VERSION "HNNBNNNYNNNNNNNNNNNNNNNNNNNNNNNNNNNNNNNNNN/4/%%%/4/'%**4NNN///"

NS_ :

BS_:

BU_: BAP_Tester FASFrontradar ICAS1_X_Gateway MFK MFK120 MIK MRR2023 NR_1 NR_2

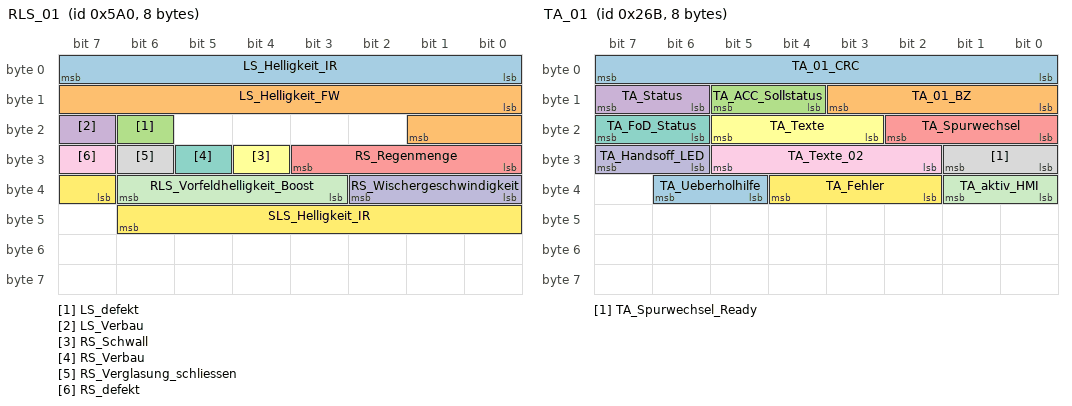
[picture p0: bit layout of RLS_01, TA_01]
BO_ 1440 RLS_01: 8 ICAS1_X_Gateway
 SG_ LS_Helligkeit_IR : 0|8@1+ (400,0) [0|101200] "Unit_Lux"  Vector__XXX
 SG_ LS_Helligkeit_FW : 8|10@1+ (6,0) [0|6126] "Unit_Lux"  Vector__XXX
 SG_ LS_defekt : 22|1@1+ (1.0,0.0) [0.0|1] ""  Vector__XXX
 SG_ LS_Verbau : 23|1@1+ (1.0,0.0) [0.0|1] ""  Vector__XXX
 SG_ RS_Regenmenge : 24|4@1+ (1.0,0.0) [0.0|15] ""  MFK120
 SG_ RS_Schwall : 28|1@1+ (1.0,0.0) [0.0|1] ""  Vector__XXX
 SG_ RS_Verbau : 29|1@1+ (1.0,0.0) [0.0|1] ""  Vector__XXX
 SG_ RS_Verglasung_schliessen : 30|1@1+ (1.0,0.0) [0.0|1] ""  Vector__XXX
 SG_ RS_defekt : 31|1@1+ (1.0,0.0) [0.0|1] ""  Vector__XXX
 SG_ RS_Wischergeschwindigkeit : 32|3@1+ (1.0,0.0) [0.0|7] ""  MFK,MFK120
 SG_ RLS_Vorfeldhelligkeit_Boost : 35|4@1+ (1.0,0.0) [0.0|15] ""  Vector__XXX
 SG_ SLS_Helligkeit_IR : 39|8@1+ (250,0) [0|7000] "Unit_Lux"  Vector__XXX

BO_ 2463978697 SAL_01: 8 ICAS1_X_Gateway
 SG_ SAL_01_CRC : 0|8@1+ (1,0) [0|255] ""  Vector__XXX
 SG_ SAL_01_BZ : 8|4@1+ (1,0) [0|15] ""  Vector__XXX
 SG_ SAL_LDS_Abblendlicht_Anf : 12|1@1+ (1.0,0.0) [0.0|1] ""  Vector__XXX
 SG_ SAL_LDS_Assistenzfahrlicht_Anf : 13|1@1+ (1.0,0.0) [0.0|1] ""  Vector__XXX
 SG_ SAL_LDS_Nullstellung_Anf : 14|1@1+ (1.0,0.0) [0.0|1] ""  Vector__XXX
 SG_ SAL_LDS_Standlicht_Anf : 15|1@1+ (1.0,0.0) [0.0|1] ""  Vector__XXX
 SG_ SBBR_SL_AnimDimm_Freigabe : 16|2@1+ (1.0,0.0) [0.0|3] ""  Vector__XXX
 SG_ BCM2_Bremsl_durch_ECD : 18|1@1+ (1.0,0.0) [0.0|1] ""  Vector__XXX
 SG_ SAL_LH_Anf : 19|1@1+ (1.0,0.0) [0.0|1] ""  Vector__XXX
 SG_ SAL_BRL_Anf : 20|1@1+ (1.0,0.0) [0.0|1] ""  Vector__XXX
 SG_ SAL_WBT_Bel : 21|1@1+ (1.0,0.0) [0.0|1] ""  Vector__XXX
 SG_ SAL_CH_Anf : 22|1@1+ (1.0,0.0) [0.0|1] ""  Vector__XXX
 SG_ SAL_PL_R_Anf : 23|1@1+ (1.0,0.0) [0.0|1] ""  Vector__XXX
 SG_ SAL_PL_L_Anf : 24|1@1+ (1.0,0.0) [0.0|1] ""  Vector__XXX
 SG_ SAL_BLK_R_Anf : 25|1@1+ (1.0,0.0) [0.0|1] ""  Vector__XXX
 SG_ SAL_BLK_L_Anf : 26|1@1+ (1.0,0.0) [0.0|1] ""  Vector__XXX
 SG_ SAL_RFL_Anf : 27|1@1+ (1.0,0.0) [0.0|1] ""  Vector__XXX
 SG_ SAL_NSL_Anf : 28|1@1+ (1.0,0.0) [0.0|1] ""  Vector__XXX
 SG_ SAL_SL_Anf : 29|1@1+ (1.0,0.0) [0.0|1] ""  Vector__XXX
 SG_ SAL_HGB_Anf : 30|1@1+ (1.0,0.0) [0.0|1] ""  Vector__XXX
 SG_ LWR_SollDC : 32|8@1+ (0.5,0) [0.0|100.0] "Unit_PerCent"  Vector__XXX
 SG_ SAL_Bremszyklus : 43|1@1+ (1.0,0.0) [0.0|1] ""  Vector__XXX
 SG_ SAL_Blinkerzyklus_R : 44|1@1+ (1.0,0.0) [0.0|1] ""  Vector__XXX
 SG_ SAL_Blinkerzyklus_L : 45|1@1+ (1.0,0.0) [0.0|1] ""  Vector__XXX
 SG_ LWR_Lampe : 46|1@1+ (1.0,0.0) [0.0|1] ""  Vector__XXX
 SG_ AFS_Lampe : 47|1@1+ (1.0,0.0) [0.0|1] ""  Vector__XXX
 SG_ LWR_Reisemodus_Texte : 48|2@1+ (1.0,0.0) [0.0|3] ""  Vector__XXX
 SG_ SAL_KZL_Anf : 50|1@1+ (1.0,0.0) [0.0|1] ""  Vector__XXX
 SG_ SAL_KL_50 : 51|1@1+ (1.0,0.0) [0.0|1] ""  Vector__XXX
 SG_ SAL_KL_75a_vFzg : 52|1@1+ (1.0,0.0) [0.0|1] ""  Vector__XXX
 SG_ SAL_KL_75a : 53|1@1+ (1.0,0.0) [0.0|1] ""  Vector__XXX
 SG_ SAL_KL_75_vFzg : 54|1@1+ (1.0,0.0) [0.0|1] ""  Vector__XXX
 SG_ SAL_Kl_75 : 55|1@1+ (1.0,0.0) [0.0|1] ""  Vector__XXX
 SG_ SAL_KL_50_5s : 56|1@1+ (1.0,0.0) [0.0|1] ""  Vector__XXX
 SG_ SAL_Kl_15_vFzg_S : 57|1@1+ (1.0,0.0) [0.0|1] ""  Vector__XXX
 SG_ SAL_Kl_15_vFzg : 58|1@1+ (1.0,0.0) [0.0|1] ""  Vector__XXX
 SG_ SAL_Kl_15 : 59|1@1+ (1.0,0.0) [0.0|1] ""  Vector__XXX
 SG_ DLI_Ambex_RefStatus : 60|3@1+ (1.0,0.0) [0.0|7] ""  Vector__XXX
 SG_ SAL_Aussenbeleuchtung_defekt : 63|1@1+ (1.0,0.0) [0.0|1] ""  MFK

BO_ 980 SMLS_01: 8 ICAS1_X_Gateway
 SG_ SMLS_01_CRC : 0|8@1+ (1,0) [0|255] ""  Vector__XXX
 SG_ SMLS_01_BZ : 8|4@1+ (1,0) [0|15] ""  Vector__XXX
 SG_ BH_Blinker_li : 12|1@1+ (1.0,0.0) [0.0|1] ""  FASFrontradar,MFK,MFK120,MRR2023
 SG_ BH_Blinker_re : 13|1@1+ (1.0,0.0) [0.0|1] ""  FASFrontradar,MFK,MFK120,MRR2023
 SG_ BH_Lichthupe : 14|1@1+ (1.0,0.0) [0.0|1] ""  Vector__XXX
 SG_ BH_Fernlicht : 15|1@1+ (1.0,0.0) [0.0|1] ""  MFK
 SG_ WH_Tipwischen : 16|1@1+ (1.0,0.0) [0.0|1] ""  Vector__XXX
 SG_ WH_Intervall : 17|1@1+ (1.0,0.0) [0.0|1] ""  Vector__XXX
 SG_ WH_WischerStufe1 : 18|1@1+ (1.0,0.0) [0.0|1] ""  Vector__XXX
 SG_ WH_WischerStufe2 : 19|1@1+ (1.0,0.0) [0.0|1] ""  Vector__XXX
 SG_ WH_Frontwaschen : 20|1@1+ (1.0,0.0) [0.0|1] ""  Vector__XXX
 SG_ WH_Heckintervall : 21|1@1+ (1.0,0.0) [0.0|1] ""  Vector__XXX
 SG_ WH_Heckwaschen : 22|1@1+ (1.0,0.0) [0.0|1] ""  Vector__XXX
 SG_ WH_Intervallstufen : 23|4@1+ (1.0,0.0) [0.0|15] ""  Vector__XXX
 SG_ FAS_Taster : 27|1@1+ (1.0,0.0) [0.0|1] ""  MFK
 SG_ FAS_Taster_Fehler : 28|1@1+ (1.0,0.0) [0.0|1] ""  MFK
 SG_ SMLS_Hupe : 29|1@1+ (1.0,0.0) [0.0|1] ""  Vector__XXX
 SG_ LRH_On_Off : 30|2@1+ (1.0,0.0) [0.0|3] ""  Vector__XXX
 SG_ LSS_Tastencode : 32|8@1+ (1.0,0.0) [0.0|255] ""  Vector__XXX
 SG_ LRH_aktiv : 40|1@1+ (1.0,0.0) [0.0|1] ""  Vector__XXX
 SG_ SMLS_P_verriegelt : 41|2@1+ (1.0,0.0) [0.0|3] ""  Vector__XXX
 SG_ SMLS_P_verriegelt_plausibel : 43|1@1+ (1.0,0.0) [0.0|1] ""  Vector__XXX
 SG_ WH_SRA : 44|1@1+ (1.0,0.0) [0.0|1] ""  Vector__XXX
 SG_ WH_Wischer_Fehler : 45|1@1+ (1.0,0.0) [0.0|1] ""  Vector__XXX
 SG_ BH_Blinker_Fehler : 46|1@1+ (1.0,0.0) [0.0|1] ""  FASFrontradar,MRR2023
 SG_ SMLS_PTT : 47|1@1+ (1.0,0.0) [0.0|1] ""  Vector__XXX
 SG_ WH_Tipwischen_lang : 48|1@1+ (1.0,0.0) [0.0|1] ""  Vector__XXX

BO_ 2464153679 SOK_FoD_Kamera_Req_Chal_01: 8 MFK120
 SG_ SOK_FoD_Kamera_Req_Challenge : 0|64@1+ (1,0) [0|18446744073709551615] "Unit_None"  ICAS1_X_Gateway

BO_ 2464284751 SOK_FoD_Kamera_Resp_Chal_01: 8 ICAS1_X_Gateway
 SG_ SOK_FoD_Kamera_Resp_Challenge : 0|64@1+ (1,0) [0|18446744073709551615] "Unit_None"  MFK120

BO_ 2464155061 SOK_FR_Auth_NAD_Chal_02: 8 ICAS1_X_Gateway
 SG_ SOK_FR_Auth_NAD_Challenge : 0|64@1+ (1,0) [0|18446744073709551615] "Unit_None"  MIK

BO_ 2464286133 SOK_FR_Auth_NAD_Resp_02: 16 MIK
 SG_ FaceRec_Status : 48|8@1+ (1,0) [0|255] "Unit_None"  ICAS1_X_Gateway
 SG_ FaceRec_Status_UserId : 56|8@1+ (1,0) [0|255] "Unit_None"  ICAS1_X_Gateway
 SG_ SOK_FR_Auth_NAD_Signatur : 64|64@1+ (1,0) [0|18446744073709551615] "Unit_None"  ICAS1_X_Gateway

BO_ 2464153657 SOK_FR_Enroll_MIK_Chal_01: 8 MIK
 SG_ SOK_FR_Enroll_MIK_Challenge : 0|64@1+ (1,0) [0|18446744073709551615] "Unit_None"  ICAS1_X_Gateway

BO_ 2464284729 SOK_FR_Enroll_MIK_Resp_01: 16 ICAS1_X_Gateway
 SG_ FaceRec_Control : 48|8@1+ (1,0) [0|255] "Unit_None"  MIK
 SG_ FaceRec_Control_UserId : 56|8@1+ (1,0) [0|255] "Unit_None"  MIK
 SG_ SOK_FR_Enroll_MIK_Signatur : 64|64@1+ (1,0) [0|18446744073709551615] "Unit_None"  MIK

BO_ 2589283756 SOK_NoAuthenticTime_01: 8 ICAS1_X_Gateway
 SG_ SOK_ungeschuetzte_Zeit : 8|56@1+ (1,0) [1|72057594037927935] "Unit_None"  Vector__XXX

BO_ 1413 Systeminfo_01: 8 ICAS1_X_Gateway
 SG_ SI_Sammel_SG_Fehler : 0|6@1+ (1,0) [0|60] ""  Vector__XXX
 SG_ SI_P_Mode_gueltig : 6|1@1+ (1.0,0.0) [0.0|1] ""  FASFrontradar
 SG_ SI_Diagnose_Aktiv : 7|1@1+ (1.0,0.0) [0.0|1] ""  Vector__XXX
 SG_ SI_QRS_Mode : 8|1@1+ (1.0,0.0) [0.0|1] ""  MIK
 SG_ SI_T_Mode : 9|1@1+ (1.0,0.0) [0.0|1] ""  MIK
 SG_ SI_NWDF : 10|1@1+ (1.0,0.0) [0.0|1] ""  FASFrontradar,MFK,MIK
 SG_ SI_NWDF_gueltig : 11|1@1+ (1.0,0.0) [0.0|1] ""  FASFrontradar,MFK,MIK
 SG_ SI_Sammelfehler : 12|1@1+ (1.0,0.0) [0.0|1] ""  Vector__XXX
 SG_ GW_KD_Fehler : 13|1@1+ (1.0,0.0) [0.0|1] ""  Vector__XXX
 SG_ SI_T_Schutz : 14|1@1+ (1.0,0.0) [0.0|1] ""  FASFrontradar,MIK
 SG_ SI_P_Mode : 15|1@1+ (1.0,0.0) [0.0|1] ""  FASFrontradar
 SG_ SI_BUS_01 : 16|1@1+ (1.0,0.0) [0.0|1] ""  MIK
 SG_ SI_BUS_02 : 17|1@1+ (1.0,0.0) [0.0|1] ""  MIK
 SG_ SI_BUS_03 : 18|1@1+ (1.0,0.0) [0.0|1] ""  Vector__XXX
 SG_ SI_BUS_04 : 19|1@1+ (1.0,0.0) [0.0|1] ""  Vector__XXX
 SG_ SI_BUS_05 : 20|1@1+ (1.0,0.0) [0.0|1] ""  Vector__XXX
 SG_ SI_BUS_06 : 21|1@1+ (1.0,0.0) [0.0|1] ""  Vector__XXX
 SG_ SI_BUS_07 : 22|1@1+ (1.0,0.0) [0.0|1] ""  Vector__XXX
 SG_ SI_BUS_08 : 23|1@1+ (1.0,0.0) [0.0|1] ""  Vector__XXX
 SG_ SI_BUS_09 : 24|1@1+ (1.0,0.0) [0.0|1] ""  Vector__XXX
 SG_ SI_BUS_10 : 25|1@1+ (1.0,0.0) [0.0|1] ""  Vector__XXX
 SG_ SI_BUS_11 : 26|1@1+ (1.0,0.0) [0.0|1] ""  Vector__XXX
 SG_ SI_BUS_12 : 27|1@1+ (1.0,0.0) [0.0|1] ""  Vector__XXX
 SG_ SI_BUS_13 : 28|1@1+ (1.0,0.0) [0.0|1] ""  Vector__XXX
 SG_ SI_BUS_14 : 29|1@1+ (1.0,0.0) [0.0|1] ""  Vector__XXX
 SG_ SI_BUS_15 : 30|1@1+ (1.0,0.0) [0.0|1] ""  Vector__XXX
 SG_ SI_Bus_Identifikation : 32|8@1+ (1.0,0.0) [0.0|255] ""  Vector__XXX
 SG_ SI_CAB_V15 : 40|24@1+ (1.0,0.0) [0.0|16777215] ""  Vector__XXX

BO_ 2589283775 SystemState_01: 8 ICAS1_X_Gateway
 SG_ NM_Req_Kessy : 0|1@1+ (1.0,0.0) [0.0|1] ""  Vector__XXX
 SG_ NM_Req_USS : 1|1@1+ (1.0,0.0) [0.0|1] ""  Vector__XXX
 SG_ NM_Req_IAA_PSO : 2|1@1+ (1.0,0.0) [0.0|1] ""  Vector__XXX
 SG_ NM_Req_KS : 3|1@1+ (1.0,0.0) [0.0|1] ""  Vector__XXX
 SG_ NM_Req_PaCo : 4|1@1+ (1.0,0.0) [0.0|1] ""  Vector__XXX
 SG_ NM_Req_STK : 5|1@1+ (1.0,0.0) [0.0|1] ""  Vector__XXX
 SG_ NM_Req_ZV : 6|1@1+ (1.0,0.0) [0.0|1] ""  Vector__XXX
 SG_ NM_Req_RTM : 7|1@1+ (1.0,0.0) [0.0|1] ""  Vector__XXX
 SG_ NM_Req_ZM : 8|1@1+ (1.0,0.0) [0.0|1] ""  Vector__XXX
 SG_ NM_Req_FoD : 9|1@1+ (1.0,0.0) [0.0|1] ""  Vector__XXX
 SG_ NM_Req_EMHLR : 10|1@1+ (1.0,0.0) [0.0|1] ""  Vector__XXX
 SG_ NM_Req_HVEM : 11|1@1+ (1.0,0.0) [0.0|1] ""  Vector__XXX
 SG_ NM_Req_ECM : 12|1@1+ (1.0,0.0) [0.0|1] ""  Vector__XXX
 SG_ NM_Req_CMS : 13|1@1+ (1.0,0.0) [0.0|1] ""  Vector__XXX
 SG_ NM_Req_DCP_01 : 14|1@1+ (1.0,0.0) [0.0|1] ""  Vector__XXX
 SG_ NM_Req_DIM : 15|1@1+ (1.0,0.0) [0.0|1] ""  Vector__XXX
 SG_ NM_Req_SAL : 16|1@1+ (1.0,0.0) [0.0|1] ""  Vector__XXX
 SG_ NM_Req_KLS : 17|1@1+ (1.0,0.0) [0.0|1] ""  Vector__XXX
 SG_ NM_Req_DCP_02 : 18|1@1+ (1.0,0.0) [0.0|1] ""  Vector__XXX
 SG_ NM_Req_SWC1 : 19|1@1+ (1.0,0.0) [0.0|1] ""  Vector__XXX
 SG_ NM_Req_SWC2 : 20|1@1+ (1.0,0.0) [0.0|1] ""  Vector__XXX
 SG_ NM_Req_internal : 21|1@1+ (1.0,0.0) [0.0|1] ""  Vector__XXX
 SG_ NM_Req_EOC : 22|1@1+ (1.0,0.0) [0.0|1] ""  Vector__XXX
 SG_ NM_Req_SWC3 : 23|1@1+ (1.0,0.0) [0.0|1] ""  Vector__XXX
 SG_ NM_aktiv_CWU : 24|1@1+ (1.0,0.0) [0.0|1] ""  Vector__XXX
 SG_ NM_aktiv_Buskopplung : 25|1@1+ (1.0,0.0) [0.0|1] ""  Vector__XXX
 SG_ NM_aktiv_CAB : 26|1@1+ (1.0,0.0) [0.0|1] ""  Vector__XXX
 SG_ NM_Req_SWC4 : 27|1@1+ (1.0,0.0) [0.0|1] ""  Vector__XXX
 SG_ NM_Req_SWC5 : 28|1@1+ (1.0,0.0) [0.0|1] ""  Vector__XXX
 SG_ NM_Req_SWC6 : 29|1@1+ (1.0,0.0) [0.0|1] ""  Vector__XXX
 SG_ NM_Req_SWC7 : 30|1@1+ (1.0,0.0) [0.0|1] ""  Vector__XXX
 SG_ NM_Req_SWC8 : 31|1@1+ (1.0,0.0) [0.0|1] ""  Vector__XXX
 SG_ Powerstate_Act : 32|5@1+ (1.0,0.0) [0.0|31] ""  Vector__XXX
 SG_ NM_Req_LIN_EMHLR : 37|1@1+ (1.0,0.0) [0.0|1] ""  Vector__XXX
 SG_ NM_Req_LIN_AI : 38|1@1+ (1.0,0.0) [0.0|1] ""  Vector__XXX
 SG_ NM_Req_LIN_EOC : 39|1@1+ (1.0,0.0) [0.0|1] ""  Vector__XXX
 SG_ NM_Req_LIN_SWC1 : 40|1@1+ (1.0,0.0) [0.0|1] ""  Vector__XXX
 SG_ NM_Req_LIN_SWC2 : 41|1@1+ (1.0,0.0) [0.0|1] ""  Vector__XXX
 SG_ NM_Req_LIN_SWC3 : 42|1@1+ (1.0,0.0) [0.0|1] ""  Vector__XXX
 SG_ Diagnose_ActLine : 45|1@1+ (1.0,0.0) [0.0|1] ""  Vector__XXX
 SG_ Diagnose_OnBoard : 46|1@1+ (1.0,0.0) [0.0|1] ""  Vector__XXX
 SG_ Diagnose_OffBoard : 47|1@1+ (1.0,0.0) [0.0|1] ""  Vector__XXX
 SG_ Powerstate_Time : 48|16@1+ (1,0) [0|65535] "Unit_Minut"  Vector__XXX

BO_ 2589283947 SystemState_02: 16 ICAS1_X_Gateway
 SG_ NM_Reason_Kessy : 0|4@1+ (1.0,0.0) [0.0|15] ""  Vector__XXX
 SG_ NM_Reason_USS : 4|4@1+ (1.0,0.0) [0.0|15] ""  Vector__XXX
 SG_ NM_Reason_IAA_PSO : 8|4@1+ (1.0,0.0) [0.0|15] ""  Vector__XXX
 SG_ NM_Reason_KS : 12|4@1+ (1.0,0.0) [0.0|15] ""  Vector__XXX
 SG_ NM_Reason_PaCo : 16|4@1+ (1.0,0.0) [0.0|15] ""  Vector__XXX
 SG_ NM_Reason_STK : 20|4@1+ (1.0,0.0) [0.0|15] ""  Vector__XXX
 SG_ NM_Reason_ZV : 24|4@1+ (1.0,0.0) [0.0|15] ""  Vector__XXX
 SG_ NM_Reason_RTM : 28|4@1+ (1.0,0.0) [0.0|15] ""  Vector__XXX
 SG_ NM_Reason_ZM : 32|4@1+ (1.0,0.0) [0.0|15] ""  Vector__XXX
 SG_ NM_Reason_FoD : 36|4@1+ (1.0,0.0) [0.0|15] ""  Vector__XXX
 SG_ NM_Reason_EMHLR : 40|4@1+ (1.0,0.0) [0.0|15] ""  Vector__XXX
 SG_ NM_Reason_HVEM : 44|4@1+ (1.0,0.0) [0.0|15] ""  Vector__XXX
 SG_ NM_Reason_ECM : 48|4@1+ (1.0,0.0) [0.0|15] ""  Vector__XXX
 SG_ NM_Reason_CMS : 52|4@1+ (1.0,0.0) [0.0|15] ""  Vector__XXX
 SG_ NM_Reason_DCP_1 : 56|4@1+ (1.0,0.0) [0.0|15] ""  Vector__XXX
 SG_ NM_Reason_DCP_2 : 60|4@1+ (1.0,0.0) [0.0|15] ""  Vector__XXX
 SG_ NM_Reason_DIM : 64|4@1+ (1.0,0.0) [0.0|15] ""  Vector__XXX
 SG_ NM_Reason_SAL : 68|4@1+ (1.0,0.0) [0.0|15] ""  Vector__XXX
 SG_ NM_Reason_KLS : 72|4@1+ (1.0,0.0) [0.0|15] ""  Vector__XXX
 SG_ NM_Reason_SWC1 : 76|4@1+ (1.0,0.0) [0.0|15] ""  Vector__XXX
 SG_ NM_Reason_SWC2 : 80|4@1+ (1.0,0.0) [0.0|15] ""  Vector__XXX
 SG_ NM_Reason_ICAS1_internal : 84|4@1+ (1.0,0.0) [0.0|15] ""  Vector__XXX
 SG_ NM_Reason_EOC : 88|4@1+ (1.0,0.0) [0.0|15] ""  Vector__XXX
 SG_ NM_Reason_SWC3 : 92|4@1+ (1.0,0.0) [0.0|15] ""  Vector__XXX
 SG_ NM_Reason_SWC4 : 96|4@1+ (1.0,0.0) [0.0|15] ""  Vector__XXX
 SG_ NM_Reason_SWC5 : 100|4@1+ (1.0,0.0) [0.0|15] ""  Vector__XXX
 SG_ Powerstate_Prev_01 : 104|5@1+ (1.0,0.0) [0.0|31] ""  Vector__XXX
 SG_ Powerstate_Prev_02 : 109|5@1+ (1.0,0.0) [0.0|31] ""  Vector__XXX
 SG_ NM_Reason_SWC6 : 114|4@1+ (1.0,0.0) [0.0|15] ""  Vector__XXX
 SG_ NM_Reason_SWC7 : 118|4@1+ (1.0,0.0) [0.0|15] ""  Vector__XXX
 SG_ NM_Reason_SWC8 : 122|4@1+ (1.0,0.0) [0.0|15] ""  Vector__XXX

BO_ 619 TA_01: 8 MFK
 SG_ TA_01_CRC : 0|8@1+ (1,0) [0|255] ""  ICAS1_X_Gateway
 SG_ TA_01_BZ : 8|4@1+ (1,0) [0|15] ""  ICAS1_X_Gateway
 SG_ TA_ACC_Sollstatus : 12|2@1+ (1.0,0.0) [0.0|3] ""  FASFrontradar,ICAS1_X_Gateway,MRR2023
 SG_ TA_Status : 14|2@1+ (1.0,0.0) [0.0|3] ""  FASFrontradar,ICAS1_X_Gateway,MRR2023
 SG_ TA_Spurwechsel : 16|3@1+ (1.0,0.0) [0.0|7] ""  FASFrontradar,ICAS1_X_Gateway,MRR2023
 SG_ TA_Texte : 19|3@1+ (1.0,0.0) [0.0|7] ""  FASFrontradar,ICAS1_X_Gateway,MRR2023
 SG_ TA_FoD_Status : 22|2@1+ (1.0,0.0) [0.0|3] ""  FASFrontradar,ICAS1_X_Gateway
 SG_ TA_Spurwechsel_Ready : 24|2@1+ (1.0,0.0) [0.0|3] ""  ICAS1_X_Gateway
 SG_ TA_Texte_02 : 26|4@1+ (1.0,0.0) [0.0|15] ""  ICAS1_X_Gateway
 SG_ TA_Handsoff_LED : 30|2@1+ (1.0,0.0) [0.0|3] ""  ICAS1_X_Gateway
 SG_ TA_aktiv_HMI : 32|2@1+ (1.0,0.0) [0.0|3] ""  FASFrontradar,ICAS1_X_Gateway,MRR2023
 SG_ TA_Fehler : 34|3@1+ (1.0,0.0) [0.0|7] ""  FASFrontradar,ICAS1_X_Gateway,MRR2023
 SG_ TA_Ueberholhilfe : 37|2@1+ (1.0,0.0) [0.0|3] ""  FASFrontradar,ICAS1_X_Gateway,MRR2023

BO_ 2589283750 Temperaturen_01: 8 ICAS1_X_Gateway
 SG_ KBI_QBit_Aussen_Temp_gef : 12|1@1+ (1.0,0.0) [0.0|1] ""  Vector__XXX
 SG_ KBI_Aussen_Temp_gef : 16|8@1+ (0.5,-50) [-50.0|75.0] "Unit_DegreCelsi"  MFK120

BO_ 165 TimeSync_01: 16 ICAS1_X_Gateway
 SG_ TS_CAN_Ma_Type : 0|8@1+ (1.0,0.0) [0.0|255] ""  MFK120,MRR2023,NR_1,NR_2
 SG_ TS_CAN_Ma_CRC : 8|8@1+ (1,0) [0|255] ""  MFK120,MRR2023,NR_1,NR_2
 SG_ TS_CAN_Ma_SequenceCounter : 16|4@1+ (1,0) [0|15] ""  MFK120,MRR2023,NR_1,NR_2
 SG_ TS_CAN_Ma_TimeDomain : 20|4@1+ (1,0) [0|15] ""  MFK120,MRR2023,NR_1,NR_2
 SG_ TS_CAN_Ma_OVS : 24|2@1+ (1,0) [0|3] ""  MFK120,MRR2023,NR_1,NR_2
 SG_ TS_CAN_Ma_SGW : 26|1@1+ (1.0,0.0) [0.0|1] ""  MFK120,MRR2023,NR_1,NR_2
 SG_ TS_CAN_Ma_SyncTimeSec : 39|32@0+ (1,0) [0|4294967295] ""  MFK120,MRR2023,NR_1,NR_2

BO_ 2264486930 TLT_Req_ACC_01: 48 MRR2023
 SG_ TLT_ReqMsgType_ACC_01 : 12|3@1+ (1.0,0.0) [0.0|7] ""  ICAS1_X_Gateway
 SG_ TLT_ReqProtocolType_ACC_01 : 15|3@1+ (1.0,0.0) [0.0|7] ""  ICAS1_X_Gateway
 SG_ TLT_ReqSlaveID_ACC_01 : 24|8@1+ (1,0) [0|253] "Unit_None"  ICAS1_X_Gateway
 SG_ TLT_ReqSequenceID_ACC_01 : 32|16@1+ (1,0) [0|65533] "Unit_None"  ICAS1_X_Gateway
 SG_ TLT_CurSlaveTimestampS_ACC_01 : 48|48@1+ (1,0) [0|281474976710653] "Unit_Secon"  ICAS1_X_Gateway
 SG_ TLT_CurSlaveTimestampNs_ACC_01 : 96|32@1+ (1,0) [0|999999999] "Unit_NanoSecon"  ICAS1_X_Gateway
 SG_ TLT_CurRTTS_ACC_01 : 128|48@1+ (1,0) [0|281474976710653] "Unit_Secon"  ICAS1_X_Gateway
 SG_ TLT_CurRTTNs_ACC_01 : 176|32@1+ (1,0) [0|999999999] "Unit_NanoSecon"  ICAS1_X_Gateway
 SG_ TLT_ErrorMaxNs_ACC_01 : 208|32@1+ (1,0) [0|999999999] "Unit_NanoSecon"  ICAS1_X_Gateway
 SG_ TLT_ErrorMinNs_ACC_01 : 240|32@1+ (1,0) [0|999999999] "Unit_NanoSecon"  ICAS1_X_Gateway

BO_ 2264486928 TLT_Req_Kamera: 48 MFK120
 SG_ TLT_Req_Kamera_CRC : 0|8@1+ (1,0) [0|255] ""  Vector__XXX
 SG_ TLT_Req_Kamera_BZ : 8|4@1+ (1,0) [0|15] ""  Vector__XXX
 SG_ TLT_ReqMsgType_Kamera : 12|3@1+ (1.0,0.0) [0.0|7] ""  ICAS1_X_Gateway
 SG_ TLT_ReqProtocolType_Kamera : 15|3@1+ (1.0,0.0) [0.0|7] ""  ICAS1_X_Gateway
 SG_ TLT_ReqSlaveID_Kamera : 24|8@1+ (1,0) [0|253] "Unit_None"  ICAS1_X_Gateway
 SG_ TLT_ReqSequenceID_Kamera : 32|16@1+ (1,0) [0|65533] "Unit_None"  ICAS1_X_Gateway
 SG_ TLT_CurSlaveTimestampS_Kamera : 48|48@1+ (1,0) [0|281474976710653] "Unit_Secon"  ICAS1_X_Gateway
 SG_ TLT_CurSlaveTimestampNs_Kamera : 96|32@1+ (1,0) [0|999999999] "Unit_NanoSecon"  ICAS1_X_Gateway
 SG_ TLT_CurRTTS_Kamera : 128|48@1+ (1,0) [0|281474976710653] "Unit_Secon"  ICAS1_X_Gateway
 SG_ TLT_CurRTTNs_Kamera : 176|32@1+ (1,0) [0|999999999] "Unit_NanoSecon"  ICAS1_X_Gateway
 SG_ TLT_ErrorMaxNs_Kamera : 208|32@1+ (1,0) [0|999999999] "Unit_NanoSecon"  ICAS1_X_Gateway
 SG_ TLT_ErrorMinNs_Kamera : 240|32@1+ (1,0) [0|999999999] "Unit_NanoSecon"  ICAS1_X_Gateway

BO_ 2264486932 TLT_Req_NR_01: 48 NR_1
 SG_ TLT_Req_NR_01_CRC : 0|8@1+ (1,0) [0|255] ""  Vector__XXX
 SG_ TLT_Req_NR_01_BZ : 8|4@1+ (1,0) [0|15] ""  Vector__XXX
 SG_ TLT_ReqMsgType_NR_01 : 12|3@1+ (1.0,0.0) [0.0|7] ""  ICAS1_X_Gateway
 SG_ TLT_ReqProtocolType_NR_01 : 15|3@1+ (1.0,0.0) [0.0|7] ""  ICAS1_X_Gateway
 SG_ TLT_ReqSlaveID_NR_01 : 24|8@1+ (1,0) [0|253] "Unit_None"  ICAS1_X_Gateway
 SG_ TLT_ReqSequenceID_NR_01 : 32|16@1+ (1,0) [0|65533] "Unit_None"  ICAS1_X_Gateway
 SG_ TLT_CurSlaveTimestampS_NR_01 : 48|48@1+ (1,0) [0|281474976710653] "Unit_Secon"  ICAS1_X_Gateway
 SG_ TLT_CurSlaveTimestampNs_NR_01 : 96|32@1+ (1,0) [0|999999999] "Unit_NanoSecon"  ICAS1_X_Gateway
 SG_ TLT_CurRTTS_NR_01 : 128|48@1+ (1,0) [0|281474976710653] "Unit_Secon"  ICAS1_X_Gateway
 SG_ TLT_CurRTTNs_NR_01 : 176|32@1+ (1,0) [0|999999999] "Unit_NanoSecon"  ICAS1_X_Gateway
 SG_ TLT_ErrorMaxNs_NR_01 : 208|32@1+ (1,0) [0|999999999] "Unit_NanoSecon"  ICAS1_X_Gateway
 SG_ TLT_ErrorMinNs_NR_01 : 240|32@1+ (1,0) [0|999999999] "Unit_NanoSecon"  ICAS1_X_Gateway

BO_ 2264486934 TLT_Req_NR_02: 48 NR_2
 SG_ TLT_Req_NR_02_CRC : 0|8@1+ (1,0) [0|255] ""  Vector__XXX
 SG_ TLT_Req_NR_02_BZ : 8|4@1+ (1,0) [0|15] ""  Vector__XXX
 SG_ TLT_ReqMsgType_NR_02 : 12|3@1+ (1.0,0.0) [0.0|7] ""  ICAS1_X_Gateway
 SG_ TLT_ReqProtocolType_NR_02 : 15|3@1+ (1.0,0.0) [0.0|7] ""  ICAS1_X_Gateway
 SG_ TLT_ReqSlaveID_NR_02 : 24|8@1+ (1,0) [0|253] "Unit_None"  ICAS1_X_Gateway
 SG_ TLT_ReqSequenceID_NR_02 : 32|16@1+ (1,0) [0|65533] "Unit_None"  ICAS1_X_Gateway
 SG_ TLT_CurSlaveTimestampS_NR_02 : 48|48@1+ (1,0) [0|281474976710653] "Unit_Secon"  ICAS1_X_Gateway
 SG_ TLT_CurSlaveTimestampNs_NR_02 : 96|32@1+ (1,0) [0|999999999] "Unit_NanoSecon"  ICAS1_X_Gateway
 SG_ TLT_CurRTTS_NR_02 : 128|48@1+ (1,0) [0|281474976710653] "Unit_Secon"  ICAS1_X_Gateway
 SG_ TLT_CurRTTNs_NR_02 : 176|32@1+ (1,0) [0|999999999] "Unit_NanoSecon"  Vector__XXX
 SG_ TLT_ErrorMaxNs_NR_02 : 208|32@1+ (1,0) [0|999999999] "Unit_NanoSecon"  ICAS1_X_Gateway
 SG_ TLT_ErrorMinNs_NR_02 : 240|32@1+ (1,0) [0|999999999] "Unit_NanoSecon"  ICAS1_X_Gateway

BO_ 2264486931 TLT_Resp_ACC_01: 32 ICAS1_X_Gateway
 SG_ TLT_Resp_ACC_01_CRC : 0|8@1+ (1,0) [0|255] ""  MRR2023
 SG_ TLT_Resp_ACC_01_BZ : 8|4@1+ (1,0) [0|15] ""  MRR2023
 SG_ TLT_RespMsgType_ACC_01 : 12|3@1+ (1.0,0.0) [0.0|7] ""  MRR2023
 SG_ TLT_RespProtocolType_ACC_01 : 15|3@1+ (1.0,0.0) [0.0|7] ""  MRR2023
 SG_ TLT_LapCounter_ACC_01 : 18|14@1+ (1,0) [0|16381] "Unit_None"  MRR2023
 SG_ TLT_RespSequenceID_ACC_01 : 32|16@1+ (1,0) [0|65533] "Unit_None"  MRR2023
 SG_ TLT_RespSlaveID_ACC_01 : 48|8@1+ (1,0) [0|253] "Unit_None"  MRR2023
 SG_ TLT_ReqIngressTimestampNs_ACC_01 : 56|32@1+ (1,0) [0|999999999] "Unit_NanoSecon"  MRR2023
 SG_ TLT_ReqIngressTimestampS_ACC_01 : 88|48@1+ (1,0) [0|281474976710653] "Unit_Secon"  MRR2023
 SG_ TLT_RespEgressTimestampNs_ACC_01 : 136|32@1+ (1,0) [0|999999999] "Unit_NanoSecon"  MRR2023
 SG_ TLT_RespEgressTimestampS_ACC_01 : 168|48@1+ (1,0) [0|281474976710653] "Unit_Secon"  MRR2023

BO_ 2264486929 TLT_Resp_Kamera: 32 ICAS1_X_Gateway
 SG_ TLT_Resp_Kamera_CRC : 0|8@1+ (1,0) [0|255] ""  Vector__XXX
 SG_ TLT_Resp_Kamera_BZ : 8|4@1+ (1,0) [0|15] ""  Vector__XXX
 SG_ TLT_RespMsgType_Kamera : 12|3@1+ (1.0,0.0) [0.0|7] ""  MFK120
 SG_ TLT_RespProtocolType_Kamera : 15|3@1+ (1.0,0.0) [0.0|7] ""  MFK120
 SG_ TLT_LapCounter_Kamera : 18|14@1+ (1,0) [0|16381] "Unit_None"  MFK120
 SG_ TLT_RespSequenceID_Kamera : 32|16@1+ (1,0) [0|65533] "Unit_None"  MFK120
 SG_ TLT_RespSlaveID_Kamera : 48|8@1+ (1,0) [0|253] "Unit_None"  MFK120
 SG_ TLT_ReqIngressTimestampNs_Kamera : 56|32@1+ (1,0) [0|999999999] "Unit_NanoSecon"  MFK120
 SG_ TLT_ReqIngressTimestampS_Kamera : 88|48@1+ (1,0) [0|281474976710653] "Unit_Secon"  MFK120
 SG_ TLT_RespEgressTimestampNs_Kamera : 136|32@1+ (1,0) [0|999999999] "Unit_NanoSecon"  MFK120
 SG_ TLT_RespEgressTimestampS_Kamera : 168|48@1+ (1,0) [0|281474976710653] "Unit_Secon"  MFK120

BO_ 2264486933 TLT_Resp_NR_01: 32 ICAS1_X_Gateway
 SG_ TLT_Resp_NR_01_CRC : 0|8@1+ (1,0) [0|255] ""  Vector__XXX
 SG_ TLT_Resp_NR_01_BZ : 8|4@1+ (1,0) [0|15] ""  Vector__XXX
 SG_ TLT_RespMsgType_NR_01 : 12|3@1+ (1.0,0.0) [0.0|7] ""  NR_1
 SG_ TLT_RespProtocolType_NR_01 : 15|3@1+ (1.0,0.0) [0.0|7] ""  NR_1
 SG_ TLT_LapCounter_NR_01 : 18|14@1+ (1,0) [0|16381] "Unit_None"  NR_1
 SG_ TLT_RespSequenceID_NR_01 : 32|16@1+ (1,0) [0|65533] "Unit_None"  NR_1
 SG_ TLT_RespSlaveID_NR_01 : 48|8@1+ (1,0) [0|253] "Unit_None"  NR_1
 SG_ TLT_ReqIngressTimestampNs_NR_01 : 56|32@1+ (1,0) [0|999999999] "Unit_NanoSecon"  NR_1
 SG_ TLT_ReqIngressTimestampS_NR_01 : 88|48@1+ (1,0) [0|281474976710653] "Unit_Secon"  NR_1
 SG_ TLT_RespEgressTimestampNs_NR_01 : 136|32@1+ (1,0) [0|999999999] "Unit_NanoSecon"  NR_1
 SG_ TLT_RespEgressTimestampS_NR_01 : 168|48@1+ (1,0) [0|281474976710653] "Unit_Secon"  NR_1

BO_ 2264486935 TLT_Resp_NR_02: 32 ICAS1_X_Gateway
 SG_ TLT_Resp_NR_02_CRC : 0|8@1+ (1,0) [0|255] ""  Vector__XXX
 SG_ TLT_Resp_NR_02_BZ : 8|4@1+ (1,0) [0|15] ""  Vector__XXX
 SG_ TLT_RespMsgType_NR_02 : 12|3@1+ (1.0,0.0) [0.0|7] ""  Vector__XXX
 SG_ TLT_RespProtocolType_NR_02 : 15|3@1+ (1.0,0.0) [0.0|7] ""  Vector__XXX
 SG_ TLT_LapCounter_NR_02 : 18|14@1+ (1,0) [0|16381] "Unit_None"  Vector__XXX
 SG_ TLT_RespSequenceID_NR_02 : 32|16@1+ (1,0) [0|65533] "Unit_None"  Vector__XXX
 SG_ TLT_RespSlaveID_NR_02 : 48|8@1+ (1,0) [0|253] "Unit_None"  Vector__XXX
 SG_ TLT_ReqIngressTimestampNs_NR_02 : 56|32@1+ (1,0) [0|999999999] "Unit_NanoSecon"  Vector__XXX
 SG_ TLT_ReqIngressTimestampS_NR_02 : 88|48@1+ (1,0) [0|281474976710653] "Unit_Secon"  Vector__XXX
 SG_ TLT_RespEgressTimestampNs_NR_02 : 136|32@1+ (1,0) [0|999999999] "Unit_NanoSecon"  Vector__XXX
 SG_ TLT_RespEgressTimestampS_NR_02 : 168|48@1+ (1,0) [0|281474976710653] "Unit_Secon"  Vector__XXX

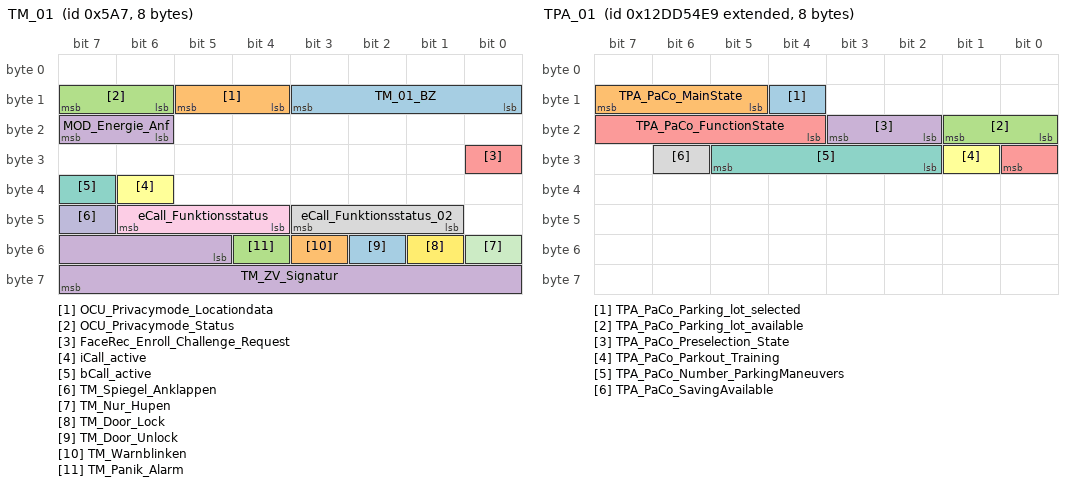
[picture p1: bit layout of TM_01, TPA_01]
BO_ 1447 TM_01: 8 ICAS1_X_Gateway
 SG_ TM_01_BZ : 8|4@1+ (1,0) [0|15] ""  Vector__XXX
 SG_ OCU_Privacymode_Locationdata : 12|2@1+ (1.0,0.0) [0.0|3] ""  Vector__XXX
 SG_ OCU_Privacymode_Status : 14|2@1+ (1.0,0.0) [0.0|3] ""  Vector__XXX
 SG_ MOD_Energie_Anf : 22|2@1+ (1.0,0.0) [0.0|3] ""  Vector__XXX
 SG_ FaceRec_Enroll_Challenge_Request : 24|1@1+ (1.0,0.0) [0.0|1] ""  MIK
 SG_ iCall_active : 38|1@1+ (1.0,0.0) [0.0|1] ""  Vector__XXX
 SG_ bCall_active : 39|1@1+ (1.0,0.0) [0.0|1] ""  Vector__XXX
 SG_ eCall_Funktionsstatus_02 : 41|3@1+ (1.0,0.0) [0.0|7] ""  Vector__XXX
 SG_ eCall_Funktionsstatus : 44|3@1+ (1.0,0.0) [0.0|7] ""  Vector__XXX
 SG_ TM_Spiegel_Anklappen : 47|1@1+ (1.0,0.0) [0.0|1] ""  Vector__XXX
 SG_ TM_Nur_Hupen : 48|1@1+ (1.0,0.0) [0.0|1] ""  Vector__XXX
 SG_ TM_Door_Lock : 49|1@1+ (1.0,0.0) [0.0|1] ""  Vector__XXX
 SG_ TM_Door_Unlock : 50|1@1+ (1.0,0.0) [0.0|1] ""  Vector__XXX
 SG_ TM_Warnblinken : 51|1@1+ (1.0,0.0) [0.0|1] ""  Vector__XXX
 SG_ TM_Panik_Alarm : 52|1@1+ (1.0,0.0) [0.0|1] ""  Vector__XXX
 SG_ TM_ZV_Signatur : 53|11@1+ (1,0) [1|2047] "Unit_None"  Vector__XXX

BO_ 2463978729 TPA_01: 8 MFK
 SG_ TPA_PaCo_Parking_lot_selected : 12|1@1+ (1.0,0.0) [0.0|1] ""  ICAS1_X_Gateway
 SG_ TPA_PaCo_MainState : 13|3@1+ (1.0,0.0) [0.0|7] ""  ICAS1_X_Gateway
 SG_ TPA_PaCo_Parking_lot_available : 16|2@1+ (1.0,0.0) [0.0|3] ""  ICAS1_X_Gateway
 SG_ TPA_PaCo_Preselection_State : 18|2@1+ (1.0,0.0) [0.0|3] ""  ICAS1_X_Gateway
 SG_ TPA_PaCo_FunctionState : 20|5@1+ (1.0,0.0) [0.0|31] ""  ICAS1_X_Gateway
 SG_ TPA_PaCo_Parkout_Training : 25|1@1+ (1.0,0.0) [0.0|1] ""  ICAS1_X_Gateway
 SG_ TPA_PaCo_Number_ParkingManeuvers : 26|4@1+ (1.0,0.0) [0.0|15] ""  ICAS1_X_Gateway
 SG_ TPA_PaCo_SavingAvailable : 30|1@1+ (1.0,0.0) [0.0|1] ""  ICAS1_X_Gateway

BO_ 2463978788 TPA_02: 64 MFK
 SG_ TPA_Traj_Update : 12|4@1+ (1,0) [0|15] "Unit_None"  ICAS1_X_Gateway
 SG_ TPA_Zeitstempel : 16|13@1+ (0.001,0) [0.000|8.190] "Unit_Secon"  ICAS1_X_Gateway
 SG_ TPA_Fortschrittsanzeige : 29|7@1+ (1,0) [0|100] "Unit_None"  ICAS1_X_Gateway
 SG_ TPA_Status : 36|4@1+ (1.0,0.0) [0.0|15] ""  ICAS1_X_Gateway
 SG_ TPA_Unsicherheit_PosX : 40|4@1+ (1,0) [0|15] "Unit_None"  ICAS1_X_Gateway
 SG_ TPA_Unsicherheit_PosY : 44|4@1+ (1,0) [0|15] "Unit_None"  ICAS1_X_Gateway
 SG_ TPA_FzgPositionY : 48|13@1+ (2,-8188) [-8188|8188] "Unit_Centimeter"  ICAS1_X_Gateway
 SG_ TPA_Verfuegbarkeit : 61|3@1+ (1.0,0.0) [0.0|7] ""  ICAS1_X_Gateway
 SG_ TPA_FzgPositionX : 64|13@1+ (2,-8188) [-8188|8188] "Unit_Centimeter"  ICAS1_X_Gateway
 SG_ TPA_FzgAusrichtung : 77|9@1+ (1,0) [0|509] "Unit_DegreOfArc"  ICAS1_X_Gateway
 SG_ TPA_Traj_P1_Zugrichtung : 86|2@1+ (1.0,0.0) [0.0|3] ""  ICAS1_X_Gateway
 SG_ TPA_Traj_P2_Zugrichtung : 88|2@1+ (1.0,0.0) [0.0|3] ""  ICAS1_X_Gateway
 SG_ TPA_Traj_P3_Zugrichtung : 90|2@1+ (1.0,0.0) [0.0|3] ""  ICAS1_X_Gateway
 SG_ TPA_Traj_P4_Zugrichtung : 92|2@1+ (1.0,0.0) [0.0|3] ""  ICAS1_X_Gateway
 SG_ TPA_Traj_P5_Zugrichtung : 94|2@1+ (1.0,0.0) [0.0|3] ""  ICAS1_X_Gateway
 SG_ TPA_Traj_P6_Zugrichtung : 96|2@1+ (1.0,0.0) [0.0|3] ""  ICAS1_X_Gateway
 SG_ TPA_Traj_P7_Zugrichtung : 98|2@1+ (1.0,0.0) [0.0|3] ""  ICAS1_X_Gateway
 SG_ TPA_Traj_P8_Zugrichtung : 100|2@1+ (1.0,0.0) [0.0|3] ""  ICAS1_X_Gateway
 SG_ TPA_Traj_P9_Zugrichtung : 102|2@1+ (1.0,0.0) [0.0|3] ""  ICAS1_X_Gateway
 SG_ TPA_Traj_P10_Zugrichtung : 104|2@1+ (1.0,0.0) [0.0|3] ""  ICAS1_X_Gateway
 SG_ TPA_Traj_P11_Zugrichtung : 106|2@1+ (1.0,0.0) [0.0|3] ""  ICAS1_X_Gateway
 SG_ TPA_Traj_P12_Zugrichtung : 108|2@1+ (1.0,0.0) [0.0|3] ""  ICAS1_X_Gateway
 SG_ TPA_Traj_P1_X : 110|13@1+ (2,-8188) [-8188|8188] "Unit_Centimeter"  ICAS1_X_Gateway
 SG_ TPA_Traj_P1_Y : 123|13@1+ (2,-8188) [-8188|8188] "Unit_Centimeter"  ICAS1_X_Gateway
 SG_ TPA_Traj_P2_dX : 136|8@1+ (1,-126) [-126|126] "Unit_Centimeter"  ICAS1_X_Gateway
 SG_ TPA_Traj_P2_dY : 144|8@1+ (1,-126) [-126|126] "Unit_Centimeter"  ICAS1_X_Gateway
 SG_ TPA_Traj_P3_dX : 152|8@1+ (1,-126) [-126|126] "Unit_Centimeter"  ICAS1_X_Gateway
 SG_ TPA_Traj_P3_dY : 160|8@1+ (1,-126) [-126|126] "Unit_Centimeter"  ICAS1_X_Gateway
 SG_ TPA_Traj_P4_dX : 168|8@1+ (1,-126) [-126|126] "Unit_Centimeter"  ICAS1_X_Gateway
 SG_ TPA_Traj_P4_dY : 176|8@1+ (1,-126) [-126|126] "Unit_Centimeter"  ICAS1_X_Gateway
 SG_ TPA_Traj_P5_dX : 184|8@1+ (1,-126) [-126|126] "Unit_Centimeter"  ICAS1_X_Gateway
 SG_ TPA_Traj_P5_dY : 192|8@1+ (1,-126) [-126|126] "Unit_Centimeter"  ICAS1_X_Gateway
 SG_ TPA_Traj_P6_dX : 200|8@1+ (1,-126) [-126|126] "Unit_Centimeter"  ICAS1_X_Gateway
 SG_ TPA_Traj_P6_dY : 208|8@1+ (1,-126) [-126|126] "Unit_Centimeter"  ICAS1_X_Gateway
 SG_ TPA_Traj_P7_dX : 216|8@1+ (1,-126) [-126|126] "Unit_Centimeter"  ICAS1_X_Gateway
 SG_ TPA_Traj_P7_dY : 224|8@1+ (1,-126) [-126|126] "Unit_Centimeter"  ICAS1_X_Gateway
 SG_ TPA_Traj_P8_dX : 232|8@1+ (1,-126) [-126|126] "Unit_Centimeter"  ICAS1_X_Gateway
 SG_ TPA_Traj_P8_dY : 240|8@1+ (1,-126) [-126|126] "Unit_Centimeter"  ICAS1_X_Gateway
 SG_ TPA_Traj_P9_dX : 248|8@1+ (1,-126) [-126|126] "Unit_Centimeter"  ICAS1_X_Gateway
 SG_ TPA_Traj_P9_dY : 256|8@1+ (1,-126) [-126|126] "Unit_Centimeter"  ICAS1_X_Gateway
 SG_ TPA_Traj_P10_dX : 264|8@1+ (1,-126) [-126|126] "Unit_Centimeter"  ICAS1_X_Gateway
 SG_ TPA_Traj_P10_dY : 272|8@1+ (1,-126) [-126|126] "Unit_Centimeter"  ICAS1_X_Gateway
 SG_ TPA_Traj_P11_dX : 280|8@1+ (1,-126) [-126|126] "Unit_Centimeter"  ICAS1_X_Gateway
 SG_ TPA_Traj_P11_dY : 288|8@1+ (1,-126) [-126|126] "Unit_Centimeter"  ICAS1_X_Gateway
 SG_ TPA_Traj_P12_dX : 296|8@1+ (1,-126) [-126|126] "Unit_Centimeter"  ICAS1_X_Gateway
 SG_ TPA_Traj_P12_dY : 304|8@1+ (1,-126) [-126|126] "Unit_Centimeter"  ICAS1_X_Gateway
 SG_ TPA_Traj_P1_Tangentenwinkel : 312|7@1+ (3,0) [0|375] "Unit_DegreOfArc"  ICAS1_X_Gateway
 SG_ TPA_Traj_P2_Tangentenwinkel : 319|7@1+ (3,0) [0|375] "Unit_DegreOfArc"  ICAS1_X_Gateway
 SG_ TPA_Traj_P3_Tangentenwinkel : 326|7@1+ (3,0) [0|375] "Unit_DegreOfArc"  ICAS1_X_Gateway
 SG_ TPA_Traj_P4_Tangentenwinkel : 333|7@1+ (3,0) [0|375] "Unit_DegreOfArc"  ICAS1_X_Gateway
 SG_ TPA_Traj_P5_Tangentenwinkel : 340|7@1+ (3,0) [0|375] "Unit_DegreOfArc"  ICAS1_X_Gateway
 SG_ TPA_Traj_P6_Tangentenwinkel : 347|7@1+ (3,0) [0|375] "Unit_DegreOfArc"  ICAS1_X_Gateway
 SG_ TPA_Traj_P7_Tangentenwinkel : 354|7@1+ (3,0) [0|375] "Unit_DegreOfArc"  ICAS1_X_Gateway
 SG_ TPA_Traj_P8_Tangentenwinkel : 361|7@1+ (3,0) [0|375] "Unit_DegreOfArc"  ICAS1_X_Gateway
 SG_ TPA_Traj_P9_Tangentenwinkel : 368|7@1+ (3,0) [0|375] "Unit_DegreOfArc"  ICAS1_X_Gateway
 SG_ TPA_Traj_P10_Tangentenwinkel : 375|7@1+ (3,0) [0|375] "Unit_DegreOfArc"  ICAS1_X_Gateway
 SG_ TPA_Traj_P11_Tangentenwinkel : 382|7@1+ (3,0) [0|375] "Unit_DegreOfArc"  ICAS1_X_Gateway
 SG_ TPA_Traj_P12_Tangentenwinkel : 389|7@1+ (3,0) [0|375] "Unit_DegreOfArc"  ICAS1_X_Gateway
 SG_ TPA_Abbruch : 396|3@1+ (1.0,0.0) [0.0|7] ""  ICAS1_X_Gateway
 SG_ TPA_Remote_aktivierbar : 399|1@1+ (1.0,0.0) [0.0|1] ""  ICAS1_X_Gateway
 SG_ TPA_Remote_verfuegbar : 400|1@1+ (1.0,0.0) [0.0|1] ""  ICAS1_X_Gateway
 SG_ TPA_Traj_P1_Kruemmung_VZ : 427|1@1+ (1.0,0.0) [0.0|1] ""  ICAS1_X_Gateway
 SG_ TPA_Traj_P2_Kruemmung_VZ : 428|1@1+ (1.0,0.0) [0.0|1] ""  ICAS1_X_Gateway
 SG_ TPA_Traj_P3_Kruemmung_VZ : 429|1@1+ (1.0,0.0) [0.0|1] ""  ICAS1_X_Gateway
 SG_ TPA_Traj_P4_Kruemmung_VZ : 430|1@1+ (1.0,0.0) [0.0|1] ""  ICAS1_X_Gateway
 SG_ TPA_Traj_P5_Kruemmung_VZ : 431|1@1+ (1.0,0.0) [0.0|1] ""  ICAS1_X_Gateway
 SG_ TPA_Traj_P1_Kruemmung_02 : 432|16@1+ (0.0000067,0) [0E-7|0.4390711] "Unit_MeterInver"  ICAS1_X_Gateway
 SG_ TPA_Traj_P2_Kruemmung_02 : 448|16@1+ (0.0000067,0) [0E-7|0.4390711] "Unit_MeterInver"  ICAS1_X_Gateway
 SG_ TPA_Traj_P3_Kruemmung_02 : 464|16@1+ (0.0000067,0) [0E-7|0.4390711] "Unit_MeterInver"  ICAS1_X_Gateway
 SG_ TPA_Traj_P4_Kruemmung_02 : 480|16@1+ (0.0000067,0) [0E-7|0.4390711] "Unit_MeterInver"  ICAS1_X_Gateway
 SG_ TPA_Traj_P5_Kruemmung_02 : 496|16@1+ (0.0000067,0) [0E-7|0.4390711] "Unit_MeterInver"  ICAS1_X_Gateway

BO_ 2589283583 TPA_03: 32 MFK
 SG_ TPA_Traj_Update_TS : 12|4@1+ (1,0) [0|15] "Unit_None"  ICAS1_X_Gateway
 SG_ TPA_Zeitstempel_Sek : 16|32@1+ (1,0) [0|4294967295] "Unit_Secon"  ICAS1_X_Gateway
 SG_ TPA_Zeitstempel_NSek : 48|32@1+ (1,0) [0|4294967295] "Unit_NanoSecon"  ICAS1_X_Gateway
 SG_ TPA_Traj_P6_Kruemmung_02 : 80|16@1+ (0.0000067,0) [0E-7|0.4390711] "Unit_MeterInver"  ICAS1_X_Gateway
 SG_ TPA_Traj_P7_Kruemmung_02 : 96|16@1+ (0.0000067,0) [0E-7|0.4390711] "Unit_MeterInver"  ICAS1_X_Gateway
 SG_ TPA_Traj_P8_Kruemmung_02 : 112|16@1+ (0.0000067,0) [0E-7|0.4390711] "Unit_MeterInver"  ICAS1_X_Gateway
 SG_ TPA_Traj_P9_Kruemmung_02 : 128|16@1+ (0.0000067,0) [0E-7|0.4390711] "Unit_MeterInver"  ICAS1_X_Gateway
 SG_ TPA_Traj_P10_Kruemmung_02 : 144|16@1+ (0.0000067,0) [0E-7|0.4390711] "Unit_MeterInver"  ICAS1_X_Gateway
 SG_ TPA_Traj_P11_Kruemmung_02 : 160|16@1+ (0.0000067,0) [0E-7|0.4390711] "Unit_MeterInver"  ICAS1_X_Gateway
 SG_ TPA_Traj_P12_Kruemmung_02 : 176|16@1+ (0.0000067,0) [0E-7|0.4390711] "Unit_MeterInver"  ICAS1_X_Gateway
 SG_ TPA_Traj_P6_Kruemmung_VZ : 192|1@1+ (1.0,0.0) [0.0|1] ""  ICAS1_X_Gateway
 SG_ TPA_Traj_P7_Kruemmung_VZ : 193|1@1+ (1.0,0.0) [0.0|1] ""  ICAS1_X_Gateway
 SG_ TPA_Traj_P8_Kruemmung_VZ : 194|1@1+ (1.0,0.0) [0.0|1] ""  ICAS1_X_Gateway
 SG_ TPA_Traj_P9_Kruemmung_VZ : 195|1@1+ (1.0,0.0) [0.0|1] ""  ICAS1_X_Gateway
 SG_ TPA_Traj_P10_Kruemmung_VZ : 196|1@1+ (1.0,0.0) [0.0|1] ""  ICAS1_X_Gateway
 SG_ TPA_Traj_P11_Kruemmung_VZ : 197|1@1+ (1.0,0.0) [0.0|1] ""  ICAS1_X_Gateway
 SG_ TPA_Traj_P12_Kruemmung_VZ : 198|1@1+ (1.0,0.0) [0.0|1] ""  ICAS1_X_Gateway
 SG_ TPA_Traj_P13_Kruemmung_VZ : 199|1@1+ (1.0,0.0) [0.0|1] ""  ICAS1_X_Gateway
 SG_ TPA_Traj_P14_Kruemmung_VZ : 200|1@1+ (1.0,0.0) [0.0|1] ""  ICAS1_X_Gateway
 SG_ TPA_Traj_P15_Kruemmung_VZ : 201|1@1+ (1.0,0.0) [0.0|1] ""  ICAS1_X_Gateway
 SG_ TPA_Traj_P13_Kruemmung_02 : 208|16@1+ (0.0000067,0) [0E-7|0.4390711] "Unit_MeterInver"  ICAS1_X_Gateway
 SG_ TPA_Traj_P14_Kruemmung_02 : 224|16@1+ (0.0000067,0) [0E-7|0.4390711] "Unit_MeterInver"  ICAS1_X_Gateway
 SG_ TPA_Traj_P15_Kruemmung_02 : 240|16@1+ (0.0000067,0) [0E-7|0.4390711] "Unit_MeterInver"  ICAS1_X_Gateway

BO_TX_BU_ 619 :MFK,MFK120;
CM_ BO_ 1440 "8Byte ab MLBevo
LIN-CAN (1:1) Botschaften werden geroutet
-  wenn entsprechender Slave codiert ist
-  wenn fehlerfreie Kommunikation zum Slave besteht
-  bei fehlerhafter Kommunikation zum Slave wird die Botschaft für 4s mit den letzten gültigen Werte";
CM_ BO_ 980 "Ab MQB 7.2";
CM_ BO_ 1413 "MQB, MLBevo";

CM_ SG_ 1440 LS_defekt "Fehlererkennung Lichtsensor
";
CM_ SG_ 1440 LS_Helligkeit_FW "Vorfeldhelligkeit";
CM_ SG_ 1440 LS_Helligkeit_IR "Globalfeldhelligkeit";
CM_ SG_ 1440 LS_Verbau "Verbauinfo Lichtsensor";
CM_ SG_ 1440 RLS_Vorfeldhelligkeit_Boost "erweiterte Helligkeitssensierung für HUD";
CM_ SG_ 1440 RS_defekt "Fehlererkennung Regensensor";
CM_ SG_ 1440 RS_Regenmenge "Regenmenge";
CM_ SG_ 1440 RS_Schwall "Schwallereignis";
CM_ SG_ 1440 RS_Verbau "Verbauinfo Regensensor";
CM_ SG_ 1440 RS_Verglasung_schliessen "Anforderung: Verglasung schliessen
";
CM_ SG_ 1440 RS_Wischergeschwindigkeit "Wischergeschwindigkeit (Hübe/min)";
CM_ SG_ 1440 SLS_Helligkeit_IR "Helligkeitswert des 'Smart-Light-Sensor' im Dashboard analog / alternativ zu LS_Helligkeit_IR.

Es ist entweder ein RLS_LIN oder ein Smart-LS im FZG verbaut.";

CM_ SG_ 2463978697 AFS_Lampe "Status der Fehlerlampe: aktuell anliegender Fehlerzustand des dynamischen oder statischen Kurvenlichtes";
CM_ SG_ 2463978697 BCM2_Bremsl_durch_ECD "Bremslicht (ECD-Bremsung)
";
CM_ SG_ 2463978697 DLI_Ambex_RefStatus "Status vom DLI an das Exterieur Ambiente";
CM_ SG_ 2463978697 LWR_Lampe "Status der Fehlerlampe: aktuell anliegender Fehlerzustand";
CM_ SG_ 2463978697 LWR_Reisemodus_Texte "Anzeige der eingestellten Verkehrsart bei aktivem Touristenlicht";
CM_ SG_ 2463978697 LWR_SollDC "Sollspannung in [% von UBatt] des linken und rechten Abblendlichtbündels.";
CM_ SG_ 2463978697 SAL_01_BZ "4bit Botschaftszähler, wird mit jeder Sendebotschaft inkrementiert";
CM_ SG_ 2463978697 SAL_01_CRC "Für MLB:
Berechnung siehe Lastenheft 'Kommunikationsabsicherung für FlexRay und CAN'
Ab MQB und MLBevo:
Berechnung siehe Lastenheft 'End-to-End Kommunikationsabsicherung'

Endwerte siehe Begleitdokument 'S-PDU Kennungsfolgen'";
CM_ SG_ 2463978697 SAL_Aussenbeleuchtung_defekt "Signal gibt an, ob mindestens ein Leuchtmittel der Außenbeleuchtung defekt ist. Dies wird für Funktionen benötigt, die bei defekter Außenbeleuchtung nicht starten bzw. abbrechen (z.B. IPA/RPA, Parkhauspilot, etc.)";
CM_ SG_ 2463978697 SAL_Blinkerzyklus_L "Signal wird im MEB benötigt, um dem SAM mitzuteilen, dass eine Blinkfunktion für die linke Seite aktiv ist.";
CM_ SG_ 2463978697 SAL_Blinkerzyklus_R "Signal wird im MEB benötigt, um dem SAM mitzuteilen, dass eine Blinkfunktion für die rechte Seite aktiv ist.";
CM_ SG_ 2463978697 SAL_BLK_L_Anf "Blink-Anforderung links an Lichtrouter";
CM_ SG_ 2463978697 SAL_BLK_R_Anf "Anforderung Blinker rechts an Lichtrouter";
CM_ SG_ 2463978697 SAL_Bremszyklus "Das Signal ist aktiv, wenn im Falle einer Notbremsung (Bremslicht-Blinken EA bzw. NBA) das Bremslicht hochfrequenz blinkt.";
CM_ SG_ 2463978697 SAL_BRL_Anf "Bremslicht-Anforderung an Lichtrouter";
CM_ SG_ 2463978697 SAL_CH_Anf "Anforderung CH an Lichtrouter";
CM_ SG_ 2463978697 SAL_HGB_Anf "Anforderung HGB an Lichtrouter";
CM_ SG_ 2463978697 SAL_Kl_15 "Vom Standard Außenlicht generierte Kl15, welche durch das Geschwindigkeitssignal plausibilisiert ist. Hiermit wird sichergestellt, dass das Licht nicht erlischt, wenn die Kl15 aus ist und das FZG trotzdem rollt.";
CM_ SG_ 2463978697 SAL_Kl_15_vFzg "Die Kl-15 Botschaft, erweitert um die Information, ob das Fahrzeug aktive Wegstrecke zurücklegt.";
CM_ SG_ 2463978697 SAL_Kl_15_vFzg_S "Kl_15_vfzg_S für Sicherheitsanforderung im Außenlicht.";
CM_ SG_ 2463978697 SAL_KL_50 "Klemme 50 nach Plausibilisierung des Startwunsches. Dies wird für das Außenlicht benötigt.";
CM_ SG_ 2463978697 SAL_KL_50_5s "Kl_50_5s ist die um 5 Sekunden verzögerte Klemme 50.";
CM_ SG_ 2463978697 SAL_Kl_75 "Für Standard-Außenlicht wird die abgesicherte Kl.75 benötigt. Diese wird um das Geschwindigkeitssignal erweitert.";
CM_ SG_ 2463978697 SAL_KL_75_vFzg "Die um das Geschwindigkeitssignal erweiterte Klemme 75.";
CM_ SG_ 2463978697 SAL_KL_75a "Für Standard-Außenlicht wird die abgesicherte Kl.75a benötigt. Diese wird um das Geschwindigkeitssignal erweitert.";
CM_ SG_ 2463978697 SAL_KL_75a_vFzg "Die um die Geschwindigkeitsinformation erweiterte Kl75a.";
CM_ SG_ 2463978697 SAL_KZL_Anf "Anforderung Kennzeichenleuchte an Lichtrouter";
CM_ SG_ 2463978697 SAL_LDS_Abblendlicht_Anf "Signal gibt an, ob das Abblendlicht angefordert wird.";
CM_ SG_ 2463978697 SAL_LDS_Assistenzfahrlicht_Anf "Signal gibt an, ob das Assistenzfahrlicht (AUTO) angefordert wird.";
CM_ SG_ 2463978697 SAL_LDS_Nullstellung_Anf "Signal gibt an, ob das Nullstellung vom Lichtdrehschalter angefordert wird.";
CM_ SG_ 2463978697 SAL_LDS_Standlicht_Anf "Signal gibt an, ob das Standlicht angefordert wird.";
CM_ SG_ 2463978697 SAL_LH_Anf "Anforderung LH an Lichtrouter";
CM_ SG_ 2463978697 SAL_NSL_Anf "Anforderung Nebelschlussleuchte an Lichtrouter";
CM_ SG_ 2463978697 SAL_PL_L_Anf "Anforderung Parklicht Links an Lichtrouter.";
CM_ SG_ 2463978697 SAL_PL_R_Anf "Anforderung Parklicht rechts an Lichtrouter";
CM_ SG_ 2463978697 SAL_RFL_Anf "Anforderung Rückfahrlicht an Lichtrouter";
CM_ SG_ 2463978697 SAL_SL_Anf "Anforderung Standlicht an Lichtrouter.";
CM_ SG_ 2463978697 SAL_WBT_Bel "Beleuchtung Warnblinktaster an SAM";
CM_ SG_ 2463978697 SBBR_SL_AnimDimm_Freigabe "Freigabesignal für Dimmung und Animation";

CM_ SG_ 980 BH_Blinker_Fehler "Anzeige, ob am Lenkstockschalter ein Fehler anliegt.
Notwendig aufgrund ASIL-Einstufung";
CM_ SG_ 980 BH_Blinker_li "Blinkerhebel Richtung links";
CM_ SG_ 980 BH_Blinker_re "Blinkerhebel Richtung rechts";
CM_ SG_ 980 BH_Fernlicht "Betaetigung Fernlicht
";
CM_ SG_ 980 BH_Lichthupe "Betaetigung Lichthupe
";
CM_ SG_ 980 FAS_Taster "Betaetigung FAS Taster
";
CM_ SG_ 980 FAS_Taster_Fehler "Fehlerstatus FAS Taster
";
CM_ SG_ 980 LRH_aktiv "Signal gibt an, ob ein Heizstrom durch die Lenkradheizung fließt. Es dient der Auswertung durch das Energiemanagement.";
CM_ SG_ 980 LRH_On_Off "Status Lenkradheizung";
CM_ SG_ 980 LSS_Tastencode "0x00 = No key pressed / key released
0x01 = Menu
0x02 = Menu Up / Next Screen
0x03 = Menu Down / Previous Screen
0x04 = Up
0x05 = Down
0x06 = Up / Down ThumbWheel
0x07 = OK (ThumbWheel-Button)
0x08 = Cancel / Escape
0x09..0x0F = reserved for furt";
CM_ SG_ 980 SMLS_01_BZ "4bit Botschaftszaehler, wird mit jeder Sendebotschaft inkrementiert";
CM_ SG_ 980 SMLS_01_CRC "Für MLB:
'Berechnung siehe Lastenheft 'Kommunikationsabsicherung für FlexRay und CAN''

Ab MQB und MLBevo:
'Berechnung siehe Lastenheft 'End-to-End Kommunikationsabsicherung''

Endwerte siehe Begleitdokument 'S-PDU Kennungsfolgen'";
CM_ SG_ 980 SMLS_Hupe "Betaetigung Hupe
";
CM_ SG_ 980 SMLS_P_verriegelt "Signal stellt den Status des Signals P-verriegelt auf den Fahrzeugbus zur Verfügung. Nutzer sind z.B. die ELV, die das Signal für die Verriegelung benötigt und die Funktion Verlassenswarnung, die den Fahrer beim Verrollen des Fahrzeugs warnt.";
CM_ SG_ 980 SMLS_P_verriegelt_plausibel "Signal stellt den Plausibilisierungstatus des Signals p_verriegelt auf den Fahrzeugbus zur Verfügung. Eine Plausibilität muss explizit erkannt werden. Initial wird 'unplausibel' gesendet. Ein plausibles Signal wird erkannt, wenn p_verriegelt plausibel geg";
CM_ SG_ 980 SMLS_PTT "Betaetigung PTT";
CM_ SG_ 980 WH_Frontwaschen "Wischerhebel: Stellung Wisch Wasch vorne
";
CM_ SG_ 980 WH_Heckintervall "Wischerhebel: Stellung Heckintervall
";
CM_ SG_ 980 WH_Heckwaschen "Wischerhebel: Stellung Wisch Wasch hinten
";
CM_ SG_ 980 WH_Intervall "Wischerhebel: Stellung Intervall
";
CM_ SG_ 980 WH_Intervallstufen "Wischerhebel: Stellung Intervallstufen";
CM_ SG_ 980 WH_SRA "Scheinwerferreinigungsanlage

derzeit nur bei PAG umgesetzt";
CM_ SG_ 980 WH_Tipwischen "Wischerhebel: Tippwischen

MQB A0/ PQ26: Bei Verbau LSS (kein SMLS): gespiegelter Wert zu Signal WH_WischerStufe1";
CM_ SG_ 980 WH_Tipwischen_lang "Wischerhebel: Tippwischen lang
(dient zur Auswertung für die Unterscheidung Tippwischen oder Serviceposition Wischer)";
CM_ SG_ 980 WH_Wischer_Fehler "Anzeige, ob am Lenkstockschalter ein Fehler anliegt.
Notwendig aufgrund ASIL-Einstufung";
CM_ SG_ 980 WH_WischerStufe1 "Wischerhebel: Stufe Wischen 1
";
CM_ SG_ 980 WH_WischerStufe2 "Wischerhebel: Stufe Wischen 2
";

CM_ SG_ 2464153679 SOK_FoD_Kamera_Req_Challenge "Challenge im Rahmen des SOK Challenge-Response Protokolls.

Geschützte Funktion: Function on Demand";

CM_ SG_ 2464284751 SOK_FoD_Kamera_Resp_Challenge "Challenge im Rahmen des SOK Challenge-Response Protokolls.

Geschützte Funktion: Function on Demand";

CM_ SG_ 2464155061 SOK_FR_Auth_NAD_Challenge "Challenge im Rahmen des SOK Challenge-Response Protokolls.

Geschützte Funktion: Gesichtserkennung (FaceRec)";

CM_ SG_ 2464286133 FaceRec_Status "status messages used to signal state changes, recognition/authentication events and errors to the HMI/IAA components";
CM_ SG_ 2464286133 FaceRec_Status_UserId "Id associated with a users face template. Is sent together with FaceRec_Status";
CM_ SG_ 2464286133 SOK_FR_Auth_NAD_Signatur "Signatur im Rahmen des SOK Challenge-Response Protokolls

Geschützte Funktion: Gesichtserkennung (FaceRec)
Geschützte Signale: FaceRec_Status, FaceRec_Status_UserId";

CM_ SG_ 2464153657 SOK_FR_Enroll_MIK_Challenge "Challenge im Rahmen des SOK Challenge-Response Protokolls.

Geschützte Funktion: Gesichtserkennung (FaceRec)";

CM_ SG_ 2464284729 FaceRec_Control "Predefined messages used to control the Face Recognition function on the MIK";
CM_ SG_ 2464284729 FaceRec_Control_UserId "Id associated with a users face template. Is sent together with  FaceRec_Control.";
CM_ SG_ 2464284729 SOK_FR_Enroll_MIK_Signatur "Signatur im Rahmen des SOK Challenge-Response Protokolls

Geschützte Funktion: Gesichtserkennung (FaceRec)
Geschützte Signale: FaceRec_Control, FaceRec_Control_UserId";

CM_ SG_ 2589283756 SOK_ungeschuetzte_Zeit "Periodisch verschickter SOK Zeitwert des SOK Zeitmasters als Referenzzeit zur Erkennung von Clockjitter durch andere SOK Teilnehmer.

Der Empfang dieses Signals ist verpflichtend für jedes Steuergerät, das durch die authentische Broadcast Funktionalität";

CM_ SG_ 1413 GW_KD_Fehler "Kundendienstfehlerbit Gateway zur Anzeige eines im Gateway abgelegten Fehlerspeichereintrages.";
CM_ SG_ 1413 SI_BUS_01 "MQB/MQB_A0/PQ26: ACAN
MQB2020: ACAN(FD)
MLBevo: HCAN
E3_Volumen: ACAN(FD)
MQBw_Baseline: ACAN(FD)";
CM_ SG_ 1413 SI_BUS_02 "MQB/MQB A0 Standard+, High: FCAN
MQB2020: FCAN(FD)
MLBevo: Frei
E3_Volumen: FCAN(FD)
MQBw_Baseline: FCAN(FD)";
CM_ SG_ 1413 SI_BUS_03 "MQB/MQB A0/PQ26: KCAN
MQB2020: KCAN
MLBevo: KCAN
E3_Volumen: KCAN(HS) / K2CAN(FD) (Buskopplung)
MQBw_Baseline: KCAN(HS)";
CM_ SG_ 1413 SI_BUS_04 "MQB/MQB A0 Standard+, High: ICAN
MQB2020: ICAN(HS)
MLBevo: ICAN
E3_Volumen: ABCAN(FD)
MQBw_Baseline: ICAN(HS)";
CM_ SG_ 1413 SI_BUS_05 "MQB/MQB A0/PQ26: DiagCAN
MQB2020: DiagCAN(FD)
MLBevo: DiagCAN
E3_Volumen: DiagCAN(FD)
MQBw_Baseline: DiagCAN(FD)";
CM_ SG_ 1413 SI_BUS_06 "MQB/MQB A0/PQ26: ECAN
MQB2020: FASCAN(FD)
MLBevo: ECAN
E3_Volumen: FASCAN_1(FD)
MQBw_Baseline: FASCAN_1(FD)";
CM_ SG_ 1413 SI_BUS_07 "MQB: LIN1 (Energie)
MQB2020: LIN1 (Energie)
MLBevo: LIN1 (Energie)
E3_Volumen: LIN 1 (Energie)
MQBw_Baseline: LIN1 (Energie)";
CM_ SG_ 1413 SI_BUS_08 "MQB: LIN2 (MFL)
MQB2020: LIN2 (MFL)
MLBevo: LIN2 (MFL)
E3_Volumen: LIN2 (MFL)
MQBw_Baseline: LIN2 (MFL)";
CM_ SG_ 1413 SI_BUS_09 "MQB: LIN3 (unbelegt)
MQB2020: LIN3 (Uhr/FES)
MLBevo: LIN3 (Energie2)
MEB: LIN3
E³ 1.1 UNECE: MDKCAN";
CM_ SG_ 1413 SI_BUS_10 "MLBevo: Flexray
MQB2020: MCAN
MQBw_Baseline: FASCAN_2(FD)
E³ 1.1 UNECE: FASCAN_2(FD)";
CM_ SG_ 1413 SI_BUS_11 "MLBevo: Ethernet
MEB: LIN4";
CM_ SG_ 1413 SI_BUS_12 "MQB: unbelegt
MLBevo: K2CAN
E3_Volumen: MFLCAN
MQBw_Baseline: K2CAN(FD)";
CM_ SG_ 1413 SI_BUS_13 "MQB: unbelegt
MLBevo: DCAN
MEB: CCAN
MQBw_Baseline: K3CAN(FD)";
CM_ SG_ 1413 SI_BUS_14 "MQB/MQB A0: unbelegt
MQB2020: HCAN
MLBevo: CCAN
E3_Volumen: EVCAN(FD)
MQBw_Baseline: EVCANFD(FD)";
CM_ SG_ 1413 SI_BUS_15 "MQB: frei
MQB2020: frei
MLBevo: frei
MEB: AFSCAN";
CM_ SG_ 1413 SI_Bus_Identifikation "Das Signal identifiziert den Bus eindeutig. Das Signal ist konstant auf jedem Bus.
Der Signalwert entspricht dem Wert 'Busnummer' aus der VW80127 Gateway_component_list_databus_identification (0x2A2D) 'Bus-Identifier'.";
CM_ SG_ 1413 SI_CAB_V15 "CAB = Clusteraktivbits (V15)";
CM_ SG_ 1413 SI_Diagnose_Aktiv "Gibt an ob Diagnose-Botschaften empfangen werden und somit eine Diagnose aktiv ist.
MQB: Gibt an ob Diagnose-Bus Botschaften empfangen werden und somit eine Diagnose aktiv ist.";
CM_ SG_ 1413 SI_NWDF "Netzwerk-Diagnose Freigebe zur zentralen Aktivierung der Netzwerkdiagnose";
CM_ SG_ 1413 SI_NWDF_gueltig "Gültigkeitsbit zu SI_NWDF gemäß Lastenheft: Zentrale Aktivierung Netzwerkdiagnose";
CM_ SG_ 1413 SI_P_Mode "Zentrale Steuerung des Produktionsmodes gemäß Q-LAH-Produktionsmode (LAH.DUM.907.AS)";
CM_ SG_ 1413 SI_P_Mode_gueltig "zeigt an, ob es sich um ein Fahrzeug mit zentraler oder dezentraler Steu-erung des Produktionsmodes handelt
Siehe Q-LAH Produktionsmode (LAH.DUM.907.AS)";
CM_ SG_ 1413 SI_QRS_Mode "Messmodus Quick-Ruhestrom";
CM_ SG_ 1413 SI_Sammel_SG_Fehler "Anzahl der gesetzten KD-Fehler direkt angeschlossener Steuergeräte der DK3 und DK4 gemäß 80127.
Hinweis: Ein Subbusmaster stellt nur die gesammelte Information der an ihn angeschlossenen Steuergeräte der DK3 und DK4 zur Verfügung.

Für ServiceKey Auswe";
CM_ SG_ 1413 SI_Sammelfehler "Sammelfehlermeldung zur Anzeige im Kombi - siehe Spez. Sammelfehlermeldung
Hinweis: Einzelne Steuergeräte können zur Anpassung an den Produktionsprozess im Gateway auskodiert werden!";
CM_ SG_ 1413 SI_T_Mode "0x0: Transportmodus nicht aktiv
0x1: Transportmodus aktiv";
CM_ SG_ 1413 SI_T_Schutz "Transportschutz-Signal, das bei Transportmodus und Motorlauf aktiv bleibt
0x0: Transportschutz nicht aktiv
0x1: Transportschutz aktiv";

CM_ SG_ 2589283775 Diagnose_ActLine "Nachlauf aufgrund der Activation-Line";
CM_ SG_ 2589283775 Diagnose_OffBoard "Nachlauf aufgrund einer OffBoard Diagnose";
CM_ SG_ 2589283775 Diagnose_OnBoard "Nachlauf aufgrund einer OnBoard Diagnose";
CM_ SG_ 2589283775 NM_aktiv_Buskopplung "Nachlauf wegen Buskopplung (z.B. FAS CAN1 und CAN2)";
CM_ SG_ 2589283775 NM_aktiv_CAB "Nachlauf wegen empfangenen CAB-Signal";
CM_ SG_ 2589283775 NM_aktiv_CWU "Nachlauf wegen empfangenen CarWakeUp";
CM_ SG_ 2589283775 NM_Req_CMS "Cluster werden auf Grund einer Aktivität dieser SWC wachgehalten";
CM_ SG_ 2589283775 NM_Req_DCP_01 "Cluster werden auf Grund einer Aktivität dieser SWC wachgehalten";
CM_ SG_ 2589283775 NM_Req_DCP_02 "Cluster werden auf Grund einer Aktivität dieser SWC wachgehalten";
CM_ SG_ 2589283775 NM_Req_DIM "Cluster werden auf Grund einer Aktivität dieser SWC wachgehalten";
CM_ SG_ 2589283775 NM_Req_ECM "Cluster werden auf Grund einer Aktivität dieser SWC wachgehalten";
CM_ SG_ 2589283775 NM_Req_EMHLR "Cluster werden auf Grund einer Aktivität dieser SWC wachgehalten";
CM_ SG_ 2589283775 NM_Req_EOC "Cluster werden auf Grund einer Aktivität dieser Easy-Open-Close wachgehalten";
CM_ SG_ 2589283775 NM_Req_FoD "Dieser Bus wird auf Grund einer Aktivität der Function on Demand wachgehalten";
CM_ SG_ 2589283775 NM_Req_HVEM "Dieser Bus wird auf Grund einer Aktivität des Hochvolt Energiemanagements wachgehalten";
CM_ SG_ 2589283775 NM_Req_IAA_PSO "Dieser Bus wird auf Grund einer Aktivität des User State Servers wachgehalten";
CM_ SG_ 2589283775 NM_Req_internal "Cluster werden auf Grund einer Aktivität dieser SWC wachgehalten";
CM_ SG_ 2589283775 NM_Req_Kessy "Dieser Bus wird auf Grund einer Aktivität der Funktion Kessy wachgehalten";
CM_ SG_ 2589283775 NM_Req_KLS "Dieser Bus wird auf Grund einer Aktivität der Klemmensteuerung wachgehalten";
CM_ SG_ 2589283775 NM_Req_KS "Dieser Bus wird auf Grund einer Aktivität des Komponentenschutzes wachgehalten";
CM_ SG_ 2589283775 NM_Req_LIN_AI "LIN-Kommunikation aufgrund einer Aktivität der Alcohol-Interlock LIB.";
CM_ SG_ 2589283775 NM_Req_LIN_EMHLR "LIN-Kommunikation aufgrund einer Aktivität der EMHLR LIB.";
CM_ SG_ 2589283775 NM_Req_LIN_EOC "LIN-Kommunikation aufgrund einer Aktivität der EasyOpenClose LIB.";
CM_ SG_ 2589283775 NM_Req_LIN_SWC1 "LIN-Kommunikation aufgrund einer Aktivität dieser SW-Komponente.";
CM_ SG_ 2589283775 NM_Req_LIN_SWC2 "LIN-Kommunikation aufgrund einer Aktivität dieser SW-Komponente.";
CM_ SG_ 2589283775 NM_Req_LIN_SWC3 "LIN-Kommunikation aufgrund einer Aktivität dieser SW-Komponente.";
CM_ SG_ 2589283775 NM_Req_PaCo "Dieser Bus wird auf Grund einer Aktivität des Park Koordinators wachgehalten";
CM_ SG_ 2589283775 NM_Req_RTM "Cluster werden auf Grund einer Aktivität dieser SWC wachgehalten";
CM_ SG_ 2589283775 NM_Req_SAL "Dieser Bus wird auf Grund einer Aktivität des Standardaußenlichts wachgehalten";
CM_ SG_ 2589283775 NM_Req_STK "Cluster werden auf Grund einer Aktivität dieser SWC wachgehalten";
CM_ SG_ 2589283775 NM_Req_SWC1 "Cluster werden auf Grund einer Aktivität dieser SWC wachgehalten";
CM_ SG_ 2589283775 NM_Req_SWC2 "Cluster werden auf Grund einer Aktivität dieser SWC wachgehalten";
CM_ SG_ 2589283775 NM_Req_SWC3 "Cluster werden auf Grund einer Aktivität dieser SW-Komponente wachgehalten.";
CM_ SG_ 2589283775 NM_Req_SWC4 "Cluster werden auf Grund einer Aktivität dieser SW-Komponente wachgehalten.";
CM_ SG_ 2589283775 NM_Req_SWC5 "Cluster werden auf Grund einer Aktivität dieser SW-Komponente wachgehalten.";
CM_ SG_ 2589283775 NM_Req_SWC6 "Cluster werden aufgrund einer Aktivität dieser SW-Komponente wachgehalten.";
CM_ SG_ 2589283775 NM_Req_SWC7 "Cluster werden aufgrund einer Aktivität dieser SW-Komponente wachgehalten.";
CM_ SG_ 2589283775 NM_Req_SWC8 "Cluster werden aufgrund einer Aktivität dieser SW-Komponente wachgehalten.";
CM_ SG_ 2589283775 NM_Req_USS "Dieser Bus wird auf Grund einer Aktivität des User State Servers wachgehalten";
CM_ SG_ 2589283775 NM_Req_ZM "Dieser Bus wird auf Grund einer Aktivität des Zeitmasters wachgehalten";
CM_ SG_ 2589283775 NM_Req_ZV "Cluster werden auf Grund einer Aktivität dieser SWC wachgehalten";
CM_ SG_ 2589283775 Powerstate_Act "Zeigt die Übergänge und Zustände des Powermanagements vom Sender an";
CM_ SG_ 2589283775 Powerstate_Time "Zeigt die Dauer des Ausgangszustands an";

CM_ SG_ 2589283947 NM_Reason_CMS "Cluster werden auf Grundeiner Aktivität des Charging Management Servers vom HVLM wachgehalten";
CM_ SG_ 2589283947 NM_Reason_DCP_1 "Cluster werden auf Grundeiner Aktivität von Dynamic Charging POIs vom HVLM wachgehalten";
CM_ SG_ 2589283947 NM_Reason_DCP_2 "Cluster werden auf Grundeiner Aktivität von Dynamic Charging POIs (Req) vom HVLM wachgehalten";
CM_ SG_ 2589283947 NM_Reason_DIM "Cluster werden auf Grundeiner Aktivität der Dimmung wachgehalten.";
CM_ SG_ 2589283947 NM_Reason_ECM "Cluster werden auf Grundeiner Aktivität des Extended Charging Monitoring vom HVLM wachgehalten";
CM_ SG_ 2589283947 NM_Reason_EMHLR "Cluster werden auf Grundeiner Aktivität der Energiemanagement Heizleistungsregelung wachgehalten";
CM_ SG_ 2589283947 NM_Reason_EOC "Cluster werden auf Grund einer Aktivität Easy-Open-Close wachgehalten.";
CM_ SG_ 2589283947 NM_Reason_FoD "Cluster werden auf Grundeiner Aktivität der Function on Demand wachgehalten";
CM_ SG_ 2589283947 NM_Reason_HVEM "Cluster werden auf Grundeiner Aktivität des Hochvolt Energiemanagements wachgehalten";
CM_ SG_ 2589283947 NM_Reason_IAA_PSO "Cluster werden auf Grundeiner Aktivität des IAA wachgehalten";
CM_ SG_ 2589283947 NM_Reason_ICAS1_internal "Cluster werden auf Grund einer internen ICAS Aktivität wachgehalten";
CM_ SG_ 2589283947 NM_Reason_Kessy "Cluster werden auf Grund einer Aktivität der Funktion Kessy wachgehalten";
CM_ SG_ 2589283947 NM_Reason_KLS "Cluster werden auf Grundeiner Aktivität der Klemmensteuerung wachgehalten";
CM_ SG_ 2589283947 NM_Reason_KS "Cluster werden auf Grundeiner Aktivität des Komponentenschutzes wachgehalten";
CM_ SG_ 2589283947 NM_Reason_PaCo "Cluster werden auf Grundeiner Aktivität des Park Koordinators wachgehalten";
CM_ SG_ 2589283947 NM_Reason_RTM "Cluster werden auf Grundeiner Aktivität des Real Time Monitors wachgehalten";
CM_ SG_ 2589283947 NM_Reason_SAL "Cluster werden auf Grundeiner Aktivität des Standardaußenlichts wachgehalten";
CM_ SG_ 2589283947 NM_Reason_STK "Cluster werden auf Grundeiner Aktivität der Standklimatisierung wachgehalten";
CM_ SG_ 2589283947 NM_Reason_SWC1 "Cluster werden auf Grundeiner Aktivität einer Softwarekomponente 1 wachgehalten.";
CM_ SG_ 2589283947 NM_Reason_SWC2 "Cluster werden auf Grundeiner Aktivität einer Softwarekomponente 2 wachgehalten.";
CM_ SG_ 2589283947 NM_Reason_SWC3 "Cluster werden aufgrund einer Aktivität dieser SW-Komponente wachgehalten.";
CM_ SG_ 2589283947 NM_Reason_SWC4 "Cluster werden aufgrund einer Aktivität dieser SW-Komponente wachgehalten.";
CM_ SG_ 2589283947 NM_Reason_SWC5 "Cluster werden aufgrund einer Aktivität dieser SW-Komponente wachgehalten.";
CM_ SG_ 2589283947 NM_Reason_SWC6 "Cluster werden aufgrund einer Aktivität dieser SW-Komponente wachgehalten.";
CM_ SG_ 2589283947 NM_Reason_SWC7 "Cluster werden aufgrund einer Aktivität dieser SW-Komponente wachgehalten.";
CM_ SG_ 2589283947 NM_Reason_SWC8 "Cluster werden aufgrund einer Aktivität dieser SW-Komponente wachgehalten.";
CM_ SG_ 2589283947 NM_Reason_USS "Cluster werden auf Grundeiner Aktivität des User State Servers wachgehalten";
CM_ SG_ 2589283947 NM_Reason_ZM "Cluster werden auf Grundeiner Aktivität des Zeitmasters wachgehalten";
CM_ SG_ 2589283947 NM_Reason_ZV "Cluster werden auf Grundeiner Aktivität der Zentralverriegelung wachgehalten";
CM_ SG_ 2589283947 Powerstate_Prev_01 "Zeigt die Übergänge und Zustände des Powermanagements vom Sender an";
CM_ SG_ 2589283947 Powerstate_Prev_02 "Zeigt die Übergänge und Zustände des Powermanagements vom Sender an";

CM_ SG_ 619 TA_01_BZ "4bit Botschaftszähler, wird mit jeder Sendebotschaft inkrementiert";
CM_ SG_ 619 TA_01_CRC "Für MLB:
Berechnung siehe Lastenheft 'Kommunikationsabsicherung für FlexRay und CAN'
Ab MQB und MLBevo:
Berechnung siehe Lastenheft 'End-to-End Kommunikationsabsicherung'

Endwerte siehe Begleitdokument 'S-PDU Kennungsfolgen'";
CM_ SG_ 619 TA_ACC_Sollstatus "Status-Anforderung ACC vom TravelAssist";
CM_ SG_ 619 TA_aktiv_HMI "Signalwert an Anzeigegerät welche Funktion aktiv";
CM_ SG_ 619 TA_Fehler "Fehler im Modus Travel Assist";
CM_ SG_ 619 TA_FoD_Status "TAwird durch FoD geschützt sein und so reicht die PR/Zieldatencontainer basierte Codierung nicht mehr aus.

Aus diesem Grund brauch wir ein separates Signal, dass uns den Freischaltezustand mitteilt.";
CM_ SG_ 619 TA_Handsoff_LED "Anfordern der Anzeige des LAHO-Icon in weiß und rot unabhängig von der Textmeldung";
CM_ SG_ 619 TA_Spurwechsel "Anzeige für die Durchführung eines Spurwechsels im Kombi";
CM_ SG_ 619 TA_Spurwechsel_Ready "Angabe der assistierten Spurwechselmöglichkeiten durch die Funktion 'Travel Assist'";
CM_ SG_ 619 TA_Status "Anzeige TravelAssist-Statusleuchte im Kombi";
CM_ SG_ 619 TA_Texte "Anzeige TravelAssist-Texte im Kombi";
CM_ SG_ 619 TA_Texte_02 "Anzeige TravelAssist-Texte im Kombi";
CM_ SG_ 619 TA_Ueberholhilfe "zusätzliches Signal für Handshake TA <--> ACC hinsichtlich Überholhilfe";

CM_ SG_ 2589283750 KBI_QBit_Aussen_Temp_gef "0x0 = gültiger Wert
0x1 = Ersatz-, Init- oder Fehlerwert";

CM_ SG_ 165 TS_CAN_Ma_CRC "CRC of TimeSync Message.
DataIDList={0x00;0x00;0x00;0x00;0x00;0x00;0x00;0x00;0x00;0x00;0x00;0x00;0x00;0x00;0x00;0x00}";
CM_ SG_ 165 TS_CAN_Ma_OVS "Overflow of seconds";
CM_ SG_ 165 TS_CAN_Ma_SequenceCounter "Sequence Counter of TimeSync Message";
CM_ SG_ 165 TS_CAN_Ma_SGW "Time Gateway synchronization status";
CM_ SG_ 165 TS_CAN_Ma_SyncTimeSec "32 bit LSB of the 48 bits  seconds part of time";
CM_ SG_ 165 TS_CAN_Ma_TimeDomain "Time Domain of TimeSync Messages";
CM_ SG_ 165 TS_CAN_Ma_Type "Type of TimeSync Message";

CM_ SG_ 2264486930 TLT_CurRTTNs_ACC_01 "Nanosecond portion of current calculated RTT at slave";
CM_ SG_ 2264486930 TLT_CurRTTS_ACC_01 "Second portion of current calculated RTT at slave";
CM_ SG_ 2264486930 TLT_CurSlaveTimestampNs_ACC_01 "Nanosecond portion of current local time at slave";
CM_ SG_ 2264486930 TLT_CurSlaveTimestampS_ACC_01 "Seconds part of current local time at slave";
CM_ SG_ 2264486930 TLT_ErrorMaxNs_ACC_01 "Upper bound of TLT window";
CM_ SG_ 2264486930 TLT_ErrorMinNs_ACC_01 "Lower bound of TLT window";
CM_ SG_ 2264486930 TLT_ReqMsgType_ACC_01 "Indicate Message Type";
CM_ SG_ 2264486930 TLT_ReqProtocolType_ACC_01 "Indicate protocol version";
CM_ SG_ 2264486930 TLT_ReqSequenceID_ACC_01 "Sequence ID of TLT synchronization cycle";
CM_ SG_ 2264486930 TLT_ReqSlaveID_ACC_01 "Unique ID for TLT Slave";

CM_ SG_ 2264486928 TLT_CurRTTNs_Kamera "Nanosecond portion of current calculated RTT at slave";
CM_ SG_ 2264486928 TLT_CurRTTS_Kamera "Second portion of current calculated RTT at slave";
CM_ SG_ 2264486928 TLT_CurSlaveTimestampNs_Kamera "Nanosecond portion of current local time at slave";
CM_ SG_ 2264486928 TLT_CurSlaveTimestampS_Kamera "Seconds part of current local time at slave";
CM_ SG_ 2264486928 TLT_ErrorMaxNs_Kamera "Upper bound of TLT window";
CM_ SG_ 2264486928 TLT_ErrorMinNs_Kamera "Lower bound of TLT window";
CM_ SG_ 2264486928 TLT_Req_Kamera_BZ "4bit Botschaftszähler, wird mit jeder Sendebotschaft inkrementiert";
CM_ SG_ 2264486928 TLT_Req_Kamera_CRC "Für MLB:
Berechnung siehe Lastenheft 'Kommunikationsabsicherung für FlexRay und CAN'
Ab MQB und MLBevo:
Berechnung siehe Lastenheft 'End-to-End Kommunikationsabsicherung'

Endwerte siehe Begleitdokument 'S-PDU Kennungsfolgen'";
CM_ SG_ 2264486928 TLT_ReqMsgType_Kamera "Indicate Message Type";
CM_ SG_ 2264486928 TLT_ReqProtocolType_Kamera "Indicate protocol version";
CM_ SG_ 2264486928 TLT_ReqSequenceID_Kamera "Sequence ID of TLT synchronization cycle";
CM_ SG_ 2264486928 TLT_ReqSlaveID_Kamera "Unique ID for TLT Slave";

CM_ SG_ 2264486932 TLT_CurRTTNs_NR_01 "Nanosecond portion of current calculated RTT at slave";
CM_ SG_ 2264486932 TLT_CurRTTS_NR_01 "Second portion of current calculated RTT at slave";
CM_ SG_ 2264486932 TLT_CurSlaveTimestampNs_NR_01 "Nanosecond portion of current local time at slave";
CM_ SG_ 2264486932 TLT_CurSlaveTimestampS_NR_01 "Seconds part of current local time at slave";
CM_ SG_ 2264486932 TLT_ErrorMaxNs_NR_01 "Upper bound of TLT window";
CM_ SG_ 2264486932 TLT_ErrorMinNs_NR_01 "Lower bound of TLT window";
CM_ SG_ 2264486932 TLT_Req_NR_01_BZ "4bit Botschaftszähler, wird mit jeder Sendebotschaft inkrementiert";
CM_ SG_ 2264486932 TLT_Req_NR_01_CRC "Für MLB:
Berechnung siehe Lastenheft 'Kommunikationsabsicherung für FlexRay und CAN'
Ab MQB und MLBevo:
Berechnung siehe Lastenheft 'End-to-End Kommunikationsabsicherung'

Endwerte siehe Begleitdokument 'S-PDU Kennungsfolgen'";
CM_ SG_ 2264486932 TLT_ReqMsgType_NR_01 "Indicate Message Type";
CM_ SG_ 2264486932 TLT_ReqProtocolType_NR_01 "Indicate protocol version";
CM_ SG_ 2264486932 TLT_ReqSequenceID_NR_01 "Sequence ID of TLT synchronization cycle";
CM_ SG_ 2264486932 TLT_ReqSlaveID_NR_01 "Unique ID for TLT Slave";

CM_ SG_ 2264486934 TLT_CurRTTNs_NR_02 "Nanosecond portion of current calculated RTT at slave";
CM_ SG_ 2264486934 TLT_CurRTTS_NR_02 "Second portion of current calculated RTT at slave";
CM_ SG_ 2264486934 TLT_CurSlaveTimestampNs_NR_02 "Nanosecond portion of current local time at slave";
CM_ SG_ 2264486934 TLT_CurSlaveTimestampS_NR_02 "Seconds part of current local time at slave";
CM_ SG_ 2264486934 TLT_ErrorMaxNs_NR_02 "Upper bound of TLT window";
CM_ SG_ 2264486934 TLT_ErrorMinNs_NR_02 "Lower bound of TLT window";
CM_ SG_ 2264486934 TLT_Req_NR_02_BZ "4bit Botschaftszähler, wird mit jeder Sendebotschaft inkrementiert";
CM_ SG_ 2264486934 TLT_Req_NR_02_CRC "Für MLB:
Berechnung siehe Lastenheft 'Kommunikationsabsicherung für FlexRay und CAN'
Ab MQB und MLBevo:
Berechnung siehe Lastenheft 'End-to-End Kommunikationsabsicherung'

Endwerte siehe Begleitdokument 'S-PDU Kennungsfolgen'";
CM_ SG_ 2264486934 TLT_ReqMsgType_NR_02 "Indicate Message Type";
CM_ SG_ 2264486934 TLT_ReqProtocolType_NR_02 "Indicate protocol version";
CM_ SG_ 2264486934 TLT_ReqSequenceID_NR_02 "Sequence ID of TLT synchronization cycle";
CM_ SG_ 2264486934 TLT_ReqSlaveID_NR_02 "Unique ID for TLT Slave";

CM_ SG_ 2264486931 TLT_LapCounter_ACC_01 "Number of current active TLT lap";
CM_ SG_ 2264486931 TLT_ReqIngressTimestampNs_ACC_01 "Timestamp of Request Ingress from Slave in Nanoseconds";
CM_ SG_ 2264486931 TLT_ReqIngressTimestampS_ACC_01 "Timestamp of TLT request ingress from slave in seconds";
CM_ SG_ 2264486931 TLT_Resp_ACC_01_BZ "4bit Botschaftszähler, wird mit jeder Sendebotschaft inkrementiert";
CM_ SG_ 2264486931 TLT_Resp_ACC_01_CRC "Für MLB:
Berechnung siehe Lastenheft 'Kommunikationsabsicherung für FlexRay und CAN'
Ab MQB und MLBevo:
Berechnung siehe Lastenheft 'End-to-End Kommunikationsabsicherung'

Endwerte siehe Begleitdokument 'S-PDU Kennungsfolgen'";
CM_ SG_ 2264486931 TLT_RespEgressTimestampNs_ACC_01 "Timestamp of Master response egress in Nanoseconds";
CM_ SG_ 2264486931 TLT_RespEgressTimestampS_ACC_01 "Timestamp of Master response egress in Seconds";
CM_ SG_ 2264486931 TLT_RespMsgType_ACC_01 "indicate message type";
CM_ SG_ 2264486931 TLT_RespProtocolType_ACC_01 "Indicate protocol type";
CM_ SG_ 2264486931 TLT_RespSequenceID_ACC_01 "Sequence ID of TLT synchronization cycle";
CM_ SG_ 2264486931 TLT_RespSlaveID_ACC_01 "Unique slave ID for response message";

CM_ SG_ 2264486929 TLT_LapCounter_Kamera "Number of current active TLT lap";
CM_ SG_ 2264486929 TLT_ReqIngressTimestampNs_Kamera "Timestamp of Request Ingress from Slave in Nanoseconds";
CM_ SG_ 2264486929 TLT_ReqIngressTimestampS_Kamera "Timestamp of TLT request ingress from slave in seconds";
CM_ SG_ 2264486929 TLT_Resp_Kamera_BZ "4bit Botschaftszähler, wird mit jeder Sendebotschaft inkrementiert";
CM_ SG_ 2264486929 TLT_Resp_Kamera_CRC "Für MLB:
Berechnung siehe Lastenheft 'Kommunikationsabsicherung für FlexRay und CAN'
Ab MQB und MLBevo:
Berechnung siehe Lastenheft 'End-to-End Kommunikationsabsicherung'

Endwerte siehe Begleitdokument 'S-PDU Kennungsfolgen'";
CM_ SG_ 2264486929 TLT_RespEgressTimestampNs_Kamera "Timestamp of Master response egress in Nanoseconds";
CM_ SG_ 2264486929 TLT_RespEgressTimestampS_Kamera "Timestamp of Master response egress in Seconds";
CM_ SG_ 2264486929 TLT_RespMsgType_Kamera "indicate message type";
CM_ SG_ 2264486929 TLT_RespProtocolType_Kamera "Indicate protocol type";
CM_ SG_ 2264486929 TLT_RespSequenceID_Kamera "Sequence ID of TLT synchronization cycle";
CM_ SG_ 2264486929 TLT_RespSlaveID_Kamera "Unique slave ID for response message";

CM_ SG_ 2264486933 TLT_LapCounter_NR_01 "Number of current active TLT lap";
CM_ SG_ 2264486933 TLT_ReqIngressTimestampNs_NR_01 "Timestamp of Request Ingress from Slave in Nanoseconds";
CM_ SG_ 2264486933 TLT_ReqIngressTimestampS_NR_01 "Timestamp of TLT request ingress from slave in seconds";
CM_ SG_ 2264486933 TLT_Resp_NR_01_BZ "4bit Botschaftszähler, wird mit jeder Sendebotschaft inkrementiert";
CM_ SG_ 2264486933 TLT_Resp_NR_01_CRC "Für MLB:
Berechnung siehe Lastenheft 'Kommunikationsabsicherung für FlexRay und CAN'
Ab MQB und MLBevo:
Berechnung siehe Lastenheft 'End-to-End Kommunikationsabsicherung'

Endwerte siehe Begleitdokument 'S-PDU Kennungsfolgen'";
CM_ SG_ 2264486933 TLT_RespEgressTimestampNs_NR_01 "Timestamp of Master response egress in Nanoseconds";
CM_ SG_ 2264486933 TLT_RespEgressTimestampS_NR_01 "Timestamp of Master response egress in Seconds";
CM_ SG_ 2264486933 TLT_RespMsgType_NR_01 "indicate message type";
CM_ SG_ 2264486933 TLT_RespProtocolType_NR_01 "Indicate protocol type";
CM_ SG_ 2264486933 TLT_RespSequenceID_NR_01 "Sequence ID of TLT synchronization cycle";
CM_ SG_ 2264486933 TLT_RespSlaveID_NR_01 "Unique slave ID for response message";

CM_ SG_ 2264486935 TLT_LapCounter_NR_02 "Number of current active TLT lap";
CM_ SG_ 2264486935 TLT_ReqIngressTimestampNs_NR_02 "Timestamp of Request Ingress from Slave in Nanoseconds";
CM_ SG_ 2264486935 TLT_ReqIngressTimestampS_NR_02 "Timestamp of TLT request ingress from slave in seconds";
CM_ SG_ 2264486935 TLT_Resp_NR_02_BZ "4bit Botschaftszähler, wird mit jeder Sendebotschaft inkrementiert";
CM_ SG_ 2264486935 TLT_Resp_NR_02_CRC "Für MLB:
Berechnung siehe Lastenheft 'Kommunikationsabsicherung für FlexRay und CAN'
Ab MQB und MLBevo:
Berechnung siehe Lastenheft 'End-to-End Kommunikationsabsicherung'

Endwerte siehe Begleitdokument 'S-PDU Kennungsfolgen'";
CM_ SG_ 2264486935 TLT_RespEgressTimestampNs_NR_02 "Timestamp of Master response egress in Nanoseconds";
CM_ SG_ 2264486935 TLT_RespEgressTimestampS_NR_02 "Timestamp of Master response egress in Seconds";
CM_ SG_ 2264486935 TLT_RespMsgType_NR_02 "indicate message type";
CM_ SG_ 2264486935 TLT_RespProtocolType_NR_02 "Indicate protocol type";
CM_ SG_ 2264486935 TLT_RespSequenceID_NR_02 "Sequence ID of TLT synchronization cycle";
CM_ SG_ 2264486935 TLT_RespSlaveID_NR_02 "Unique slave ID for response message";

CM_ SG_ 1447 bCall_active "1: Breakdown call is active
0: BreakdownCall is inactive";
CM_ SG_ 1447 eCall_Funktionsstatus "HMI-Aufruf im Kombi (Broadcast)
Fehlerfälle die im Kombi angezeigt werden können";
CM_ SG_ 1447 eCall_Funktionsstatus_02 "Erweiterung des Funktionsstatus für andere Funktionen
ACN aktiv, MEC aktiv
MEC = manual emergency call = maueller Notruf
ACN = automatic emergency call = automatischer Notruf";
CM_ SG_ 1447 FaceRec_Enroll_Challenge_Request "When FaceRec on MIK receives this signal it will provide a challenge via SOK_FR_Enroll_MIK_Challenge.";
CM_ SG_ 1447 iCall_active "Statusrückmeldung von OCU über Infocall aktiv/inaktiv";
CM_ SG_ 1447 MOD_Energie_Anf "Anforderung Energieversorgung MOD-Job an das NVEM";
CM_ SG_ 1447 OCU_Privacymode_Locationdata "Signal zur Ausgabe des speziellen Privacymode Status zur Ausleitung von Fahrzeugpositionsdaten.

0 = Init
1 = Ausgabe der Fahrzeugpositionsdaten ist erlaubt
2 = Ausgabe der Fahrzeugpositionsdaten ist untersagt";
CM_ SG_ 1447 OCU_Privacymode_Status "Signal zur Ausgabe des Privacymode Status

0 = Init
1 = Privacymode ist nicht aktiv
2 = Privacymode ist aktiv";
CM_ SG_ 1447 TM_01_BZ "4bit Botschaftszähler, wird mit jeder Sendebotschaft inkrementiert";
CM_ SG_ 1447 TM_Door_Lock "Remote Door lock angefordert: ZV zu/verriegeln";
CM_ SG_ 1447 TM_Door_Unlock "Remote Door unlock angefordert: ZV auf/entriegeln";
CM_ SG_ 1447 TM_Nur_Hupen "Remote Hupen (ohne Blinken) aktiviert";
CM_ SG_ 1447 TM_Panik_Alarm "Remote Hupen und Blinken aktiv";
CM_ SG_ 1447 TM_Spiegel_Anklappen "Anklappen der Außenspiegel über Remote MOD Anforderung";
CM_ SG_ 1447 TM_Warnblinken "Remote Blinken aktiviert";
CM_ SG_ 1447 TM_ZV_Signatur "Gespeicherte Signatur der ZV für Authentifizierung";

CM_ SG_ 2463978729 TPA_PaCo_FunctionState "Funktionsstatus der Kundenfunktion TPA";
CM_ SG_ 2463978729 TPA_PaCo_MainState "Hauptzustand der Kundenfunktion TPA.

0 Init: TPA befindet sich in der Initialisierung
1 InOperation_NoError: TPA befindet sich im Betrieb ohne Fehler
7 Fehler: TPA befindet sich im Fehlerzustand";
CM_ SG_ 2463978729 TPA_PaCo_Number_ParkingManeuvers "zeigt an, wie viele gespeicherte Parkplätze erkannt wurden";
CM_ SG_ 2463978729 TPA_PaCo_Parking_lot_available "Anzeige, ob ein trainierter Parkplatz erreichbar ist";
CM_ SG_ 2463978729 TPA_PaCo_Parking_lot_selected "Anzeige,ob ein trainierter Parkplatz ausgewählt ist";
CM_ SG_ 2463978729 TPA_PaCo_Parkout_Training "Das Signal zeigt an, ob das Training eines TPA-Ausparkmanövers aktiv ist";
CM_ SG_ 2463978729 TPA_PaCo_Preselection_State "Status der Vorauswahl eines trainierten Parkplatzes";
CM_ SG_ 2463978729 TPA_PaCo_SavingAvailable "zeigt an, ob dem Kunden das Speichern eines Parkplatzes angeboten werden soll";

CM_ SG_ 2463978788 TPA_Abbruch "zeigt den Abbruch der Funktion unter Angabe des Grundes an";
CM_ SG_ 2463978788 TPA_Fortschrittsanzeige "Signal zur Fortschrittsanzeige für den aktuellen Zug";
CM_ SG_ 2463978788 TPA_FzgAusrichtung "Ausrichtung des Fahrzeugs";
CM_ SG_ 2463978788 TPA_FzgPositionX "X-Position des Fahrzeugs";
CM_ SG_ 2463978788 TPA_FzgPositionY "Y-Position des Fahrzeugs";
CM_ SG_ 2463978788 TPA_Remote_aktivierbar "zeigt an, ob die Remote-Bedienung für einen Parkvorgang aktiviert werden kann bzw. soll";
CM_ SG_ 2463978788 TPA_Remote_verfuegbar "zeigt an, ob die Remote-Bedienung für ein Parkmanöver verfügbar ist";
CM_ SG_ 2463978788 TPA_Status "signalisiert den Funktionsstatus von TPA";
CM_ SG_ 2463978788 TPA_Traj_P10_dX "X-Position des Traj.-punkts P10 relativ zum Vorgänger; es werden immer die nächsten 12 Punkte der Trajektorie gemeinsam übertragen";
CM_ SG_ 2463978788 TPA_Traj_P10_dY "Y-Position des Traj.-punkts P10 relativ zum Vorgänger; es werden immer die nächsten 12 Punkte der Trajektorie gemeinsam übertragen";
CM_ SG_ 2463978788 TPA_Traj_P10_Tangentenwinkel "Winkel der Tangente am Traj.-Punkt P10; es werden immer die nächsten 15 Punkte der Trajektorie gemeinsam übertragen";
CM_ SG_ 2463978788 TPA_Traj_P10_Zugrichtung "Zugrichtung am Traj.-punkt P10; es werden immer die nächsten 15 Punkte der Trajektorie gemeinsam übertragen";
CM_ SG_ 2463978788 TPA_Traj_P11_dX "X-Position des Traj.-punkts P11 relativ zum Vorgänger; es werden immer die nächsten 12 Punkte der Trajektorie gemeinsam übertragen";
CM_ SG_ 2463978788 TPA_Traj_P11_dY "Y-Position des Traj.-punkts P11 relativ zum Vorgänger; es werden immer die nächsten 12 Punkte der Trajektorie gemeinsam übertragen";
CM_ SG_ 2463978788 TPA_Traj_P11_Tangentenwinkel "Winkel der Tangente am Traj.-Punkt P11; es werden immer die nächsten 15 Punkte der Trajektorie gemeinsam übertragen";
CM_ SG_ 2463978788 TPA_Traj_P11_Zugrichtung "Zugrichtung am Traj.-punkt P11; es werden immer die nächsten 15 Punkte der Trajektorie gemeinsam übertragen";
CM_ SG_ 2463978788 TPA_Traj_P12_dX "X-Position des Traj.-punkts P12 relativ zum Vorgänger; es werden immer die nächsten 12 Punkte der Trajektorie gemeinsam übertragen";
CM_ SG_ 2463978788 TPA_Traj_P12_dY "Y-Position des Traj.-punkts P12 relativ zum Vorgänger; es werden immer die nächsten 12 Punkte der Trajektorie gemeinsam übertragen";
CM_ SG_ 2463978788 TPA_Traj_P12_Tangentenwinkel "Winkel der Tangente am Traj.-Punkt P12; es werden immer die nächsten 15 Punkte der Trajektorie gemeinsam übertragen";
CM_ SG_ 2463978788 TPA_Traj_P12_Zugrichtung "Zugrichtung am Traj.-punkt P12; es werden immer die nächsten 15 Punkte der Trajektorie gemeinsam übertragen";
CM_ SG_ 2463978788 TPA_Traj_P1_Kruemmung_02 "Krümmung am Traj.-Punkt P1 mit erweitertem Wertebereich";
CM_ SG_ 2463978788 TPA_Traj_P1_Kruemmung_VZ "Vorzeichen für die Krümmung am Traj.-Punkt P1";
CM_ SG_ 2463978788 TPA_Traj_P1_Tangentenwinkel "Winkel der Tangente am Traj.-Punkt P1; es werden immer die nächsten 15 Punkte der Trajektorie gemeinsam übertragen";
CM_ SG_ 2463978788 TPA_Traj_P1_X "X-Position des Traj.-punkts P1; es werden immer die nächsten 15 Punkte der Trajektorie gemeinsam übertragen";
CM_ SG_ 2463978788 TPA_Traj_P1_Y "Y-Position des Traj.-punkts P1; es werden immer die nächsten 15 Punkte der Trajektorie gemeinsam übertragen";
CM_ SG_ 2463978788 TPA_Traj_P1_Zugrichtung "Zugrichtung am Traj.-punkt P1; es werden immer die nächsten 15 Punkte der Trajektorie gemeinsam übertragen";
CM_ SG_ 2463978788 TPA_Traj_P2_dX "X-Position des Traj.-punkts P2 relativ zum Vorgänger; es werden immer die nächsten 12 Punkte der Trajektorie gemeinsam übertragen";
CM_ SG_ 2463978788 TPA_Traj_P2_dY "Y-Position des Traj.-punkts P2 relativ zum Vorgänger; es werden immer die nächsten 12 Punkte der Trajektorie gemeinsam übertragen";
CM_ SG_ 2463978788 TPA_Traj_P2_Kruemmung_02 "Krümmung am Traj.-Punkt P2 mit erweitertem Wertebereich";
CM_ SG_ 2463978788 TPA_Traj_P2_Kruemmung_VZ "Vorzeichen für die Krümmung am Traj.-Punkt P2";
CM_ SG_ 2463978788 TPA_Traj_P2_Tangentenwinkel "Winkel der Tangente am Traj.-Punkt P2; es werden immer die nächsten 15 Punkte der Trajektorie gemeinsam übertragen";
CM_ SG_ 2463978788 TPA_Traj_P2_Zugrichtung "Zugrichtung am Traj.-punkt P2; es werden immer die nächsten 15 Punkte der Trajektorie gemeinsam übertragen";
CM_ SG_ 2463978788 TPA_Traj_P3_dX "X-Position des Traj.-punkts P3 relativ zum Vorgänger; es werden immer die nächsten 12 Punkte der Trajektorie gemeinsam übertragen";
CM_ SG_ 2463978788 TPA_Traj_P3_dY "Y-Position des Traj.-punkts P3 relativ zum Vorgänger; es werden immer die nächsten 12 Punkte der Trajektorie gemeinsam übertragen";
CM_ SG_ 2463978788 TPA_Traj_P3_Kruemmung_02 "Krümmung am Traj.-Punkt P3 mit erweitertem Wertebereich";
CM_ SG_ 2463978788 TPA_Traj_P3_Kruemmung_VZ "Vorzeichen für die Krümmung am Traj.-Punkt P3";
CM_ SG_ 2463978788 TPA_Traj_P3_Tangentenwinkel "Winkel der Tangente am Traj.-Punkt P3; es werden immer die nächsten 15 Punkte der Trajektorie gemeinsam übertragen";
CM_ SG_ 2463978788 TPA_Traj_P3_Zugrichtung "Zugrichtung am Traj.-punkt P3; es werden immer die nächsten 15 Punkte der Trajektorie gemeinsam übertragen";
CM_ SG_ 2463978788 TPA_Traj_P4_dX "X-Position des Traj.-punkts P4 relativ zum Vorgänger; es werden immer die nächsten 12 Punkte der Trajektorie gemeinsam übertragen";
CM_ SG_ 2463978788 TPA_Traj_P4_dY "Y-Position des Traj.-punkts P4 relativ zum Vorgänger; es werden immer die nächsten 12 Punkte der Trajektorie gemeinsam übertragen";
CM_ SG_ 2463978788 TPA_Traj_P4_Kruemmung_02 "Krümmung am Traj.-Punkt P4 mit erweitertem Wertebereich";
CM_ SG_ 2463978788 TPA_Traj_P4_Kruemmung_VZ "Vorzeichen für die Krümmung am Traj.-Punkt P4";
CM_ SG_ 2463978788 TPA_Traj_P4_Tangentenwinkel "Winkel der Tangente am Traj.-Punkt P4; es werden immer die nächsten 15 Punkte der Trajektorie gemeinsam übertragen";
CM_ SG_ 2463978788 TPA_Traj_P4_Zugrichtung "Zugrichtung am Traj.-punkt P4; es werden immer die nächsten 15 Punkte der Trajektorie gemeinsam übertragen";
CM_ SG_ 2463978788 TPA_Traj_P5_dX "X-Position des Traj.-punkts P5 relativ zum Vorgänger; es werden immer die nächsten 12 Punkte der Trajektorie gemeinsam übertragen";
CM_ SG_ 2463978788 TPA_Traj_P5_dY "Y-Position des Traj.-punkts P5 relativ zum Vorgänger; es werden immer die nächsten 12 Punkte der Trajektorie gemeinsam übertragen";
CM_ SG_ 2463978788 TPA_Traj_P5_Kruemmung_02 "Krümmung am Traj.-Punkt P5 mit erweitertem Wertebereich";
CM_ SG_ 2463978788 TPA_Traj_P5_Kruemmung_VZ "Vorzeichen für die Krümmung am Traj.-Punkt P5";
CM_ SG_ 2463978788 TPA_Traj_P5_Tangentenwinkel "Winkel der Tangente am Traj.-Punkt P5; es werden immer die nächsten 15 Punkte der Trajektorie gemeinsam übertragen";
CM_ SG_ 2463978788 TPA_Traj_P5_Zugrichtung "Zugrichtung am Traj.-punkt P5; es werden immer die nächsten 10 Punkte der Trajektorie gemeinsam übertragen";
CM_ SG_ 2463978788 TPA_Traj_P6_dX "X-Position des Traj.-punkts P6 relativ zum Vorgänger; es werden immer die nächsten 12 Punkte der Trajektorie gemeinsam übertragen";
CM_ SG_ 2463978788 TPA_Traj_P6_dY "Y-Position des Traj.-punkts P6 relativ zum Vorgänger; es werden immer die nächsten 12 Punkte der Trajektorie gemeinsam übertragen";
CM_ SG_ 2463978788 TPA_Traj_P6_Tangentenwinkel "Winkel der Tangente am Traj.-Punkt P6; es werden immer die nächsten 15 Punkte der Trajektorie gemeinsam übertragen";
CM_ SG_ 2463978788 TPA_Traj_P6_Zugrichtung "Zugrichtung am Traj.-punkt P6; es werden immer die nächsten 15 Punkte der Trajektorie gemeinsam übertragen";
CM_ SG_ 2463978788 TPA_Traj_P7_dX "X-Position des Traj.-punkts P7 relativ zum Vorgänger; es werden immer die nächsten 12 Punkte der Trajektorie gemeinsam übertragen";
CM_ SG_ 2463978788 TPA_Traj_P7_dY "Y-Position des Traj.-punkts P7 relativ zum Vorgänger; es werden immer die nächsten 12 Punkte der Trajektorie gemeinsam übertragen";
CM_ SG_ 2463978788 TPA_Traj_P7_Tangentenwinkel "Winkel der Tangente am Traj.-Punkt P7; es werden immer die nächsten 15 Punkte der Trajektorie gemeinsam übertragen";
CM_ SG_ 2463978788 TPA_Traj_P7_Zugrichtung "Zugrichtung am Traj.-punkt P7; es werden immer die nächsten 15 Punkte der Trajektorie gemeinsam übertragen";
CM_ SG_ 2463978788 TPA_Traj_P8_dX "X-Position des Traj.-punkts P8 relativ zum Vorgänger; es werden immer die nächsten 12 Punkte der Trajektorie gemeinsam übertragen";
CM_ SG_ 2463978788 TPA_Traj_P8_dY "Y-Position des Traj.-punkts P8 relativ zum Vorgänger; es werden immer die nächsten 12 Punkte der Trajektorie gemeinsam übertragen";
CM_ SG_ 2463978788 TPA_Traj_P8_Tangentenwinkel "Winkel der Tangente am Traj.-Punkt P8; es werden immer die nächsten 15 Punkte der Trajektorie gemeinsam übertragen";
CM_ SG_ 2463978788 TPA_Traj_P8_Zugrichtung "Zugrichtung am Traj.-punkt P8; es werden immer die nächsten 15 Punkte der Trajektorie gemeinsam übertragen";
CM_ SG_ 2463978788 TPA_Traj_P9_dX "X-Position des Traj.-punkts P9 relativ zum Vorgänger; es werden immer die nächsten 12 Punkte der Trajektorie gemeinsam übertragen";
CM_ SG_ 2463978788 TPA_Traj_P9_dY "Y-Position des Traj.-punkts P9 relativ zum Vorgänger; es werden immer die nächsten 12 Punkte der Trajektorie gemeinsam übertragen";
CM_ SG_ 2463978788 TPA_Traj_P9_Tangentenwinkel "Winkel der Tangente am Traj.-Punkt P9; es werden immer die nächsten 15 Punkte der Trajektorie gemeinsam übertragen";
CM_ SG_ 2463978788 TPA_Traj_P9_Zugrichtung "Zugrichtung am Traj.-punkt P9; es werden immer die nächsten 15 Punkte der Trajektorie gemeinsam übertragen";
CM_ SG_ 2463978788 TPA_Traj_Update "Aktualisierung der Trajektoriendaten";
CM_ SG_ 2463978788 TPA_Unsicherheit_PosX "Positionsunsicherheit in X-Richtung";
CM_ SG_ 2463978788 TPA_Unsicherheit_PosY "Positionsunsicherheit in Y-Richtung";
CM_ SG_ 2463978788 TPA_Verfuegbarkeit "zeigt eine Nicht-Verfuegbarkeit von TPA unter Angabe des Grundes an";
CM_ SG_ 2463978788 TPA_Zeitstempel "Zeitstempel der übertragenen Trajektoriendaten";

CM_ SG_ 2589283583 TPA_Traj_P10_Kruemmung_02 "Krümmung am Traj.-Punkt P10 mit erweitertem Wertebereich";
CM_ SG_ 2589283583 TPA_Traj_P10_Kruemmung_VZ "Vorzeichen für die Krümmung am Traj.-Punkt P10";
CM_ SG_ 2589283583 TPA_Traj_P11_Kruemmung_02 "Krümmung am Traj.-Punkt P11 mit erweitertem Wertebereich";
CM_ SG_ 2589283583 TPA_Traj_P11_Kruemmung_VZ "Vorzeichen für die Krümmung am Traj.-Punkt P11";
CM_ SG_ 2589283583 TPA_Traj_P12_Kruemmung_02 "Krümmung am Traj.-Punkt P12 mit erweitertem Wertebereich";
CM_ SG_ 2589283583 TPA_Traj_P12_Kruemmung_VZ "Vorzeichen für die Krümmung am Traj.-Punkt P1";
CM_ SG_ 2589283583 TPA_Traj_P13_Kruemmung_02 "Krümmung am Traj.-Punkt P13 mit erweitertem Wertebereich";
CM_ SG_ 2589283583 TPA_Traj_P13_Kruemmung_VZ "Vorzeichen für die Krümmung am Traj.-Punkt P13";
CM_ SG_ 2589283583 TPA_Traj_P14_Kruemmung_02 "Krümmung am Traj.-Punkt P14 mit erweitertem Wertebereich";
CM_ SG_ 2589283583 TPA_Traj_P14_Kruemmung_VZ "Vorzeichen für die Krümmung am Traj.-Punkt P14";
CM_ SG_ 2589283583 TPA_Traj_P15_Kruemmung_02 "Krümmung am Traj.-Punkt P15 mit erweitertem Wertebereich";
CM_ SG_ 2589283583 TPA_Traj_P15_Kruemmung_VZ "Vorzeichen für die Krümmung am Traj.-Punkt P15";
CM_ SG_ 2589283583 TPA_Traj_P6_Kruemmung_02 "Krümmung am Traj.-Punkt P6 mit erweitertem Wertebereich";
CM_ SG_ 2589283583 TPA_Traj_P6_Kruemmung_VZ "Vorzeichen für die Krümmung am Traj.-Punkt P6";
CM_ SG_ 2589283583 TPA_Traj_P7_Kruemmung_02 "Krümmung am Traj.-Punkt P7 mit erweitertem Wertebereich";
CM_ SG_ 2589283583 TPA_Traj_P7_Kruemmung_VZ "Vorzeichen für die Krümmung am Traj.-Punkt P7";
CM_ SG_ 2589283583 TPA_Traj_P8_Kruemmung_02 "Krümmung am Traj.-Punkt P8 mit erweitertem Wertebereich";
CM_ SG_ 2589283583 TPA_Traj_P8_Kruemmung_VZ "Vorzeichen für die Krümmung am Traj.-Punkt P8";
CM_ SG_ 2589283583 TPA_Traj_P9_Kruemmung_02 "Krümmung am Traj.-Punkt P9 mit erweitertem Wertebereich";
CM_ SG_ 2589283583 TPA_Traj_P9_Kruemmung_VZ "Vorzeichen für die Krümmung am Traj.-Punkt P9";
CM_ SG_ 2589283583 TPA_Traj_Update_TS "Aktualisierung der Trajektoriendaten";
CM_ SG_ 2589283583 TPA_Zeitstempel_NSek "Zeitstempel der übertragenen Trajektoriendaten basierend auf PLT (Nanosekundenteil)";
CM_ SG_ 2589283583 TPA_Zeitstempel_Sek "Zeitstempel der übertragenen Trajektoriendaten basierend auf PLT (Sekundenteil)";
BA_DEF_REL_ BU_SG_REL_  "GenSigTimeoutTime" INT 0 65535;
BA_DEF_ BO_  "DiagRequest" ENUM "No", "Yes";
BA_DEF_ BO_  "DiagResponse" ENUM "No", "Yes";
BA_DEF_ BO_  "DiagState" ENUM "No", "Yes";
BA_DEF_ BO_  "GenMsgChkConstant" HEX 0 4095;
BA_DEF_ BO_  "GenMsgCycleTime" INT 0 65535;
BA_DEF_ BO_  "GenMsgCycleTimeFast" INT 0 65535;
BA_DEF_ BO_  "GenMsgDelayTime" INT 0 100000;
BA_DEF_ BO_  "GenMsgILSupport" ENUM "No", "Yes";
BA_DEF_ BO_  "GenMsgNrOfRepetition" INT 0 100;
BA_DEF_ BO_  "GenMsgPDUConstants" STRING;
BA_DEF_ BO_  "GenMsgSendType" ENUM "Cyclic", "not_used", "not_used", "not_used", "not_used", "not_used", "not_used", "IfActive", "NoMsgSendType";
BA_DEF_ BO_  "GenMsgStartDelayTime" INT 0 100000;
BA_DEF_ BO_  "NmMessage" ENUM "No", "Yes";
BA_DEF_ BO_  "NmhMessage" ENUM "No", "Yes";
BA_DEF_ BO_  "MsgType" ENUM "Application", "NM ", "NMH", "TP2.0", "ISO-TP ", "BAP", "EID", "KS", "XCP_PRE_CONFIGURED", "XCP_RUNTIME_CONFIGURED";
BA_DEF_ BO_  "VAGTP20_API" HEX 0 255;
BA_DEF_ BO_  "VAGTP20_DynConnection" ENUM "No", "Yes";
BA_DEF_ BO_  "VAGTP20_DynSetup" ENUM "No", "Yes";
BA_DEF_ BO_  "VAGTP20_StatConnection" ENUM "No", "Yes";
BA_DEF_ BO_  "CANFD_BRS" ENUM "0", "1";
BA_DEF_ BO_  "VFrameFormat" ENUM "StandardCAN", "ExtendedCAN", "reserved", "reserved", "reserved", "reserved", "reserved", "reserved", "reserved", "reserved", "reserved", "reserved", "reserved", "reserved", "StandardCAN_FD", "ExtendedCAN_FD";
BA_DEF_ SG_  "GenSigActiveRepetitions" INT -2147483648 2147483647;
BA_DEF_ SG_  "GenSigInactiveValue" INT -2147483648 2147483647;
BA_DEF_ SG_  "GenSigSendType" ENUM "Cyclic", "OnWrite", "OnWriteWithRepetition", "OnChange", "OnChangeWithRepetition", "IfActive", "IfActiveWithRepetition", "NoSigSendType", "OnChangeAndIfActive", "OnChangeAndIfActiveWithRepetition";
BA_DEF_ SG_  "GenSigStartValue" INT -2147483648 2147483647;
BA_DEF_ SG_  "NWM-WakeupAllowed" ENUM "No", "Yes";
BA_DEF_ SG_  "GenSigFuncType" ENUM "NoFunction", "MsgCounter", "CRC-8", "XOR", "XOR-2", "DatedBit", "SW-Kl15", "CHK", "Constant", "Protocol", "CRC-8-SAE_J1850", "CRC-32", "DataLength", "DataID", "MsgCounter16", "SOK-Signatur", "Cluster";
BA_DEF_ SG_  "GenSigSwitchedByIgnition" ENUM "No", "Yes";
BA_DEF_ SG_  "Fehlerwert" HEX 0 2147483647;
BA_DEF_ SG_  "GenSigMissingSourceValue" HEX 0 2147483647;
BA_DEF_DEF_REL_  "GenSigTimeoutTime" 0;
BA_DEF_DEF_  "DiagRequest" "No";
BA_DEF_DEF_  "DiagResponse" "No";
BA_DEF_DEF_  "DiagState" "No";
BA_DEF_DEF_  "GenMsgChkConstant" 0;
BA_DEF_DEF_  "GenMsgCycleTime" 0;
BA_DEF_DEF_  "GenMsgCycleTimeFast" 0;
BA_DEF_DEF_  "GenMsgDelayTime" 0;
BA_DEF_DEF_  "GenMsgILSupport" "No";
BA_DEF_DEF_  "GenMsgNrOfRepetition" 0;
BA_DEF_DEF_  "GenMsgPDUConstants" "";
BA_DEF_DEF_  "GenMsgSendType" "NoMsgSendType";
BA_DEF_DEF_  "GenMsgStartDelayTime" 0;
BA_DEF_DEF_  "NmMessage" "No";
BA_DEF_DEF_  "NmhMessage" "No";
BA_DEF_DEF_  "MsgType" "Application";
BA_DEF_DEF_  "VAGTP20_API" 0;
BA_DEF_DEF_  "VAGTP20_DynConnection" "No";
BA_DEF_DEF_  "VAGTP20_DynSetup" "No";
BA_DEF_DEF_  "VAGTP20_StatConnection" "No";
BA_DEF_DEF_  "CANFD_BRS" "1";
BA_DEF_DEF_  "VFrameFormat" "StandardCAN";
BA_DEF_DEF_  "GenSigActiveRepetitions" 0;
BA_DEF_DEF_  "GenSigInactiveValue" 0;
BA_DEF_DEF_  "GenSigSendType" "NoSigSendType";
BA_DEF_DEF_  "GenSigStartValue" 0;
BA_DEF_DEF_  "NWM-WakeupAllowed" "No";
BA_DEF_DEF_  "GenSigFuncType" "NoFunction";
BA_DEF_DEF_  "GenSigSwitchedByIgnition" "Yes";
BA_DEF_DEF_  "Fehlerwert" 0;
BA_DEF_DEF_  "GenSigMissingSourceValue" 0;
BA_ "GenMsgCycleTime" BO_ 1440 200;
BA_ "GenMsgILSupport" BO_ 1440 1;
BA_ "GenMsgSendType" BO_ 1440 0;
BA_ "VFrameFormat" BO_ 1440 14;
BA_ "GenMsgCycleTime" BO_ 2463978697 80;
BA_ "GenMsgCycleTimeFast" BO_ 2463978697 50;
BA_ "GenMsgDelayTime" BO_ 2463978697 10;
BA_ "GenMsgILSupport" BO_ 2463978697 1;
BA_ "GenMsgNrOfRepetition" BO_ 2463978697 5;
BA_ "GenMsgPDUConstants" BO_ 2463978697 "0xde,0xa9,0x83,0x0b,0x0c,0x64,0x79,0x44,0x0f,0xf6,0xc6,0xc7,0x05,0x45,0xb7,0x59";
BA_ "GenMsgSendType" BO_ 2463978697 0;
BA_ "VFrameFormat" BO_ 2463978697 15;
BA_ "GenMsgCycleTime" BO_ 980 1000;
BA_ "GenMsgCycleTimeFast" BO_ 980 100;
BA_ "GenMsgDelayTime" BO_ 980 50;
BA_ "GenMsgILSupport" BO_ 980 1;
BA_ "GenMsgNrOfRepetition" BO_ 980 5;
BA_ "GenMsgPDUConstants" BO_ 980 "0xc3,0x79,0xbf,0xdb,0xe9,0x11,0x46,0x86,0x69,0xb6,0x9b,0x29,0x15,0x9c,0x45,0x0d";
BA_ "GenMsgSendType" BO_ 980 0;
BA_ "VFrameFormat" BO_ 980 14;
BA_ "GenMsgDelayTime" BO_ 2464153679 50;
BA_ "GenMsgILSupport" BO_ 2464153679 1;
BA_ "VFrameFormat" BO_ 2464153679 15;
BA_ "GenMsgDelayTime" BO_ 2464284751 50;
BA_ "GenMsgILSupport" BO_ 2464284751 1;
BA_ "VFrameFormat" BO_ 2464284751 15;
BA_ "GenMsgCycleTime" BO_ 2464155061 1000;
BA_ "GenMsgDelayTime" BO_ 2464155061 100;
BA_ "GenMsgILSupport" BO_ 2464155061 1;
BA_ "GenMsgSendType" BO_ 2464155061 0;
BA_ "VFrameFormat" BO_ 2464155061 15;
BA_ "GenMsgCycleTime" BO_ 2464286133 1000;
BA_ "GenMsgDelayTime" BO_ 2464286133 100;
BA_ "GenMsgSendType" BO_ 2464286133 0;
BA_ "VFrameFormat" BO_ 2464286133 15;
BA_ "GenMsgCycleTime" BO_ 2464153657 2000;
BA_ "GenMsgDelayTime" BO_ 2464153657 100;
BA_ "GenMsgILSupport" BO_ 2464153657 1;
BA_ "VFrameFormat" BO_ 2464153657 15;
BA_ "GenMsgDelayTime" BO_ 2464284729 100;
BA_ "VFrameFormat" BO_ 2464284729 15;
BA_ "GenMsgCycleTime" BO_ 2589283756 1000;
BA_ "GenMsgDelayTime" BO_ 2589283756 100;
BA_ "GenMsgILSupport" BO_ 2589283756 1;
BA_ "GenMsgSendType" BO_ 2589283756 0;
BA_ "VFrameFormat" BO_ 2589283756 15;
BA_ "GenMsgCycleTime" BO_ 1413 1000;
BA_ "GenMsgDelayTime" BO_ 1413 10;
BA_ "GenMsgILSupport" BO_ 1413 1;
BA_ "GenMsgSendType" BO_ 1413 0;
BA_ "VFrameFormat" BO_ 1413 14;
BA_ "GenMsgCycleTime" BO_ 2589283775 1000;
BA_ "GenMsgDelayTime" BO_ 2589283775 40;
BA_ "GenMsgILSupport" BO_ 2589283775 1;
BA_ "GenMsgSendType" BO_ 2589283775 0;
BA_ "VFrameFormat" BO_ 2589283775 15;
BA_ "GenMsgCycleTime" BO_ 2589283947 1000;
BA_ "GenMsgDelayTime" BO_ 2589283947 40;
BA_ "GenMsgILSupport" BO_ 2589283947 1;
BA_ "GenMsgSendType" BO_ 2589283947 0;
BA_ "VFrameFormat" BO_ 2589283947 15;
BA_ "GenMsgCycleTime" BO_ 619 100;
BA_ "GenMsgDelayTime" BO_ 619 20;
BA_ "GenMsgILSupport" BO_ 619 1;
BA_ "GenMsgPDUConstants" BO_ 619 "0xce,0xcc,0xbd,0x69,0xa1,0x3c,0x18,0x76,0x0f,0x04,0xf2,0x3a,0x93,0x24,0x19,0x51";
BA_ "GenMsgSendType" BO_ 619 0;
BA_ "VFrameFormat" BO_ 619 14;
BA_ "GenMsgCycleTime" BO_ 2589283750 1000;
BA_ "GenMsgILSupport" BO_ 2589283750 1;
BA_ "GenMsgSendType" BO_ 2589283750 0;
BA_ "VFrameFormat" BO_ 2589283750 15;
BA_ "GenMsgCycleTime" BO_ 165 100;
BA_ "GenMsgDelayTime" BO_ 165 10;
BA_ "GenMsgILSupport" BO_ 165 1;
BA_ "GenMsgSendType" BO_ 165 0;
BA_ "VFrameFormat" BO_ 165 14;
BA_ "GenMsgCycleTime" BO_ 2264486930 500;
BA_ "GenMsgILSupport" BO_ 2264486930 1;
BA_ "GenMsgPDUConstants" BO_ 2264486930 "0x43,0xc3,0xfb,0x79,0x9e,0xbf,0xf3,0xdb,0x3f,0xe9,0x66,0x11,0x35,0x46,0x98,0x86";
BA_ "GenMsgSendType" BO_ 2264486930 0;
BA_ "VFrameFormat" BO_ 2264486930 15;
BA_ "GenMsgCycleTime" BO_ 2264486928 500;
BA_ "GenMsgILSupport" BO_ 2264486928 1;
BA_ "GenMsgPDUConstants" BO_ 2264486928 "0x58,0xb7,0x03,0x85,0x41,0x13,0x20,0x34,0x23,0x87,0x28,0x7a,0x79,0xca,0x40,0x8f";
BA_ "GenMsgSendType" BO_ 2264486928 0;
BA_ "VFrameFormat" BO_ 2264486928 15;
BA_ "GenMsgCycleTime" BO_ 2264486932 500;
BA_ "GenMsgILSupport" BO_ 2264486932 1;
BA_ "GenMsgPDUConstants" BO_ 2264486932 "0x5e,0x4f,0x33,0x2f,0xf0,0x9f,0x99,0x44,0x18,0x97,0x7b,0x72,0x80,0xc5,0x5b,0xd3";
BA_ "GenMsgSendType" BO_ 2264486932 0;
BA_ "VFrameFormat" BO_ 2264486932 15;
BA_ "GenMsgCycleTime" BO_ 2264486934 500;
BA_ "GenMsgILSupport" BO_ 2264486934 1;
BA_ "GenMsgPDUConstants" BO_ 2264486934 "0xb0,0xf1,0xe8,0x5e,0xfa,0xa1,0x84,0x4f,0x3b,0x8e,0xc8,0x33,0x8a,0x01,0xd5,0x2f";
BA_ "GenMsgSendType" BO_ 2264486934 0;
BA_ "VFrameFormat" BO_ 2264486934 15;
BA_ "GenMsgCycleTime" BO_ 2264486931 500;
BA_ "GenMsgILSupport" BO_ 2264486931 1;
BA_ "GenMsgPDUConstants" BO_ 2264486931 "0xa3,0xc7,0xb0,0xd8,0x95,0xf1,0x7f,0xc4,0xe8,0xe3,0x51,0x5e,0x90,0x9a,0xfa,0xe2";
BA_ "GenMsgSendType" BO_ 2264486931 0;
BA_ "VFrameFormat" BO_ 2264486931 15;
BA_ "GenMsgCycleTime" BO_ 2264486929 500;
BA_ "GenMsgILSupport" BO_ 2264486929 1;
BA_ "GenMsgPDUConstants" BO_ 2264486929 "0x4d,0xb9,0x2d,0x36,0x78,0xea,0x52,0x3b,0x6c,0x68,0xef,0xe0,0x63,0x8c,0x3a,0x5f";
BA_ "GenMsgSendType" BO_ 2264486929 0;
BA_ "VFrameFormat" BO_ 2264486929 15;
BA_ "GenMsgCycleTime" BO_ 2264486933 500;
BA_ "GenMsgILSupport" BO_ 2264486933 1;
BA_ "GenMsgPDUConstants" BO_ 2264486933 "0xfb,0xbf,0x3f,0x11,0x98,0x69,0x3d,0x29,0x39,0x45,0x12,0xdc,0x2a,0x28,0x94,0xbd";
BA_ "GenMsgSendType" BO_ 2264486933 0;
BA_ "VFrameFormat" BO_ 2264486933 15;
BA_ "GenMsgCycleTime" BO_ 2264486935 500;
BA_ "GenMsgILSupport" BO_ 2264486935 1;
BA_ "GenMsgPDUConstants" BO_ 2264486935 "0x56,0x3f,0xc5,0x69,0x47,0x39,0xcd,0xdc,0xc7,0x94,0x85,0xf9,0x0e,0x14,0x92,0x64";
BA_ "GenMsgSendType" BO_ 2264486935 0;
BA_ "VFrameFormat" BO_ 2264486935 15;
BA_ "GenMsgCycleTime" BO_ 1447 1000;
BA_ "GenMsgCycleTimeFast" BO_ 1447 100;
BA_ "GenMsgDelayTime" BO_ 1447 50;
BA_ "GenMsgILSupport" BO_ 1447 1;
BA_ "GenMsgSendType" BO_ 1447 0;
BA_ "VFrameFormat" BO_ 1447 14;
BA_ "GenMsgCycleTime" BO_ 2463978729 100;
BA_ "GenMsgILSupport" BO_ 2463978729 1;
BA_ "GenMsgSendType" BO_ 2463978729 0;
BA_ "VFrameFormat" BO_ 2463978729 15;
BA_ "GenMsgCycleTime" BO_ 2463978788 500;
BA_ "GenMsgDelayTime" BO_ 2463978788 20;
BA_ "GenMsgILSupport" BO_ 2463978788 1;
BA_ "GenMsgSendType" BO_ 2463978788 0;
BA_ "VFrameFormat" BO_ 2463978788 15;
BA_ "GenMsgCycleTime" BO_ 2589283583 500;
BA_ "GenMsgDelayTime" BO_ 2589283583 20;
BA_ "GenMsgILSupport" BO_ 2589283583 1;
BA_ "GenMsgSendType" BO_ 2589283583 0;
BA_ "VFrameFormat" BO_ 2589283583 15;
BA_ "GenSigSendType" SG_ 1440 LS_defekt 0;
BA_ "GenSigSwitchedByIgnition" SG_ 1440 LS_defekt 0;
BA_ "GenSigSendType" SG_ 1440 LS_Helligkeit_FW 0;
BA_ "GenSigStartValue" SG_ 1440 LS_Helligkeit_FW 1022;
BA_ "GenSigSwitchedByIgnition" SG_ 1440 LS_Helligkeit_FW 0;
BA_ "Fehlerwert" SG_ 1440 LS_Helligkeit_FW 1023;
BA_ "GenSigMissingSourceValue" SG_ 1440 LS_Helligkeit_FW 1023;
BA_ "GenSigSendType" SG_ 1440 LS_Helligkeit_IR 0;
BA_ "GenSigStartValue" SG_ 1440 LS_Helligkeit_IR 254;
BA_ "GenSigSwitchedByIgnition" SG_ 1440 LS_Helligkeit_IR 0;
BA_ "Fehlerwert" SG_ 1440 LS_Helligkeit_IR 255;
BA_ "GenSigMissingSourceValue" SG_ 1440 LS_Helligkeit_IR 255;
BA_ "GenSigSendType" SG_ 1440 LS_Verbau 0;
BA_ "GenSigSwitchedByIgnition" SG_ 1440 LS_Verbau 0;
BA_ "GenSigSendType" SG_ 1440 RLS_Vorfeldhelligkeit_Boost 0;
BA_ "GenSigStartValue" SG_ 1440 RLS_Vorfeldhelligkeit_Boost 15;
BA_ "GenSigSwitchedByIgnition" SG_ 1440 RLS_Vorfeldhelligkeit_Boost 0;
BA_ "GenSigSendType" SG_ 1440 RS_defekt 0;
BA_ "GenSigSwitchedByIgnition" SG_ 1440 RS_defekt 0;
BA_ "GenSigSendType" SG_ 1440 RS_Regenmenge 0;
BA_ "GenSigStartValue" SG_ 1440 RS_Regenmenge 14;
BA_ "GenSigSwitchedByIgnition" SG_ 1440 RS_Regenmenge 0;
BA_ "Fehlerwert" SG_ 1440 RS_Regenmenge 15;
BA_ "GenSigMissingSourceValue" SG_ 1440 RS_Regenmenge 15;
BA_ "GenSigSendType" SG_ 1440 RS_Schwall 0;
BA_ "GenSigSwitchedByIgnition" SG_ 1440 RS_Schwall 0;
BA_ "GenSigSendType" SG_ 1440 RS_Verbau 0;
BA_ "GenSigSwitchedByIgnition" SG_ 1440 RS_Verbau 0;
BA_ "GenSigSendType" SG_ 1440 RS_Verglasung_schliessen 0;
BA_ "GenSigSwitchedByIgnition" SG_ 1440 RS_Verglasung_schliessen 0;
BA_ "GenSigSendType" SG_ 1440 RS_Wischergeschwindigkeit 0;
BA_ "GenSigSwitchedByIgnition" SG_ 1440 RS_Wischergeschwindigkeit 0;
BA_ "GenSigSendType" SG_ 1440 SLS_Helligkeit_IR 0;
BA_ "GenSigStartValue" SG_ 1440 SLS_Helligkeit_IR 254;
BA_ "GenSigSwitchedByIgnition" SG_ 1440 SLS_Helligkeit_IR 0;
BA_ "Fehlerwert" SG_ 1440 SLS_Helligkeit_IR 255;
BA_ "GenSigSendType" SG_ 2463978697 AFS_Lampe 3;
BA_ "GenSigSendType" SG_ 2463978697 BCM2_Bremsl_durch_ECD 4;
BA_ "GenSigSwitchedByIgnition" SG_ 2463978697 BCM2_Bremsl_durch_ECD 0;
BA_ "GenSigSendType" SG_ 2463978697 DLI_Ambex_RefStatus 3;
BA_ "GenSigSwitchedByIgnition" SG_ 2463978697 DLI_Ambex_RefStatus 0;
BA_ "Fehlerwert" SG_ 2463978697 DLI_Ambex_RefStatus 4;
BA_ "GenSigSendType" SG_ 2463978697 LWR_Lampe 3;
BA_ "GenSigSendType" SG_ 2463978697 LWR_Reisemodus_Texte 3;
BA_ "GenSigSendType" SG_ 2463978697 LWR_SollDC 3;
BA_ "GenSigStartValue" SG_ 2463978697 LWR_SollDC 254;
BA_ "GenSigSwitchedByIgnition" SG_ 2463978697 LWR_SollDC 0;
BA_ "Fehlerwert" SG_ 2463978697 LWR_SollDC 255;
BA_ "GenSigSendType" SG_ 2463978697 SAL_01_BZ 0;
BA_ "GenSigFuncType" SG_ 2463978697 SAL_01_BZ 1;
BA_ "GenSigSwitchedByIgnition" SG_ 2463978697 SAL_01_BZ 0;
BA_ "GenSigSendType" SG_ 2463978697 SAL_01_CRC 0;
BA_ "GenSigFuncType" SG_ 2463978697 SAL_01_CRC 2;
BA_ "GenSigSwitchedByIgnition" SG_ 2463978697 SAL_01_CRC 0;
BA_ "GenSigSendType" SG_ 2463978697 SAL_Aussenbeleuchtung_defekt 3;
BA_ "GenSigSwitchedByIgnition" SG_ 2463978697 SAL_Aussenbeleuchtung_defekt 0;
BA_ "GenSigSendType" SG_ 2463978697 SAL_Blinkerzyklus_L 3;
BA_ "GenSigSwitchedByIgnition" SG_ 2463978697 SAL_Blinkerzyklus_L 0;
BA_ "GenSigSendType" SG_ 2463978697 SAL_Blinkerzyklus_R 3;
BA_ "GenSigSwitchedByIgnition" SG_ 2463978697 SAL_Blinkerzyklus_R 0;
BA_ "GenSigSendType" SG_ 2463978697 SAL_BLK_L_Anf 4;
BA_ "GenSigSwitchedByIgnition" SG_ 2463978697 SAL_BLK_L_Anf 0;
BA_ "GenSigSendType" SG_ 2463978697 SAL_BLK_R_Anf 4;
BA_ "GenSigSwitchedByIgnition" SG_ 2463978697 SAL_BLK_R_Anf 0;
BA_ "GenSigSendType" SG_ 2463978697 SAL_Bremszyklus 3;
BA_ "GenSigSwitchedByIgnition" SG_ 2463978697 SAL_Bremszyklus 0;
BA_ "GenSigSendType" SG_ 2463978697 SAL_BRL_Anf 4;
BA_ "GenSigSwitchedByIgnition" SG_ 2463978697 SAL_BRL_Anf 0;
BA_ "GenSigSendType" SG_ 2463978697 SAL_CH_Anf 4;
BA_ "GenSigSwitchedByIgnition" SG_ 2463978697 SAL_CH_Anf 0;
BA_ "GenSigSendType" SG_ 2463978697 SAL_HGB_Anf 4;
BA_ "GenSigSwitchedByIgnition" SG_ 2463978697 SAL_HGB_Anf 0;
BA_ "GenSigSendType" SG_ 2463978697 SAL_Kl_15 3;
BA_ "GenSigSwitchedByIgnition" SG_ 2463978697 SAL_Kl_15 0;
BA_ "GenSigSendType" SG_ 2463978697 SAL_Kl_15_vFzg 3;
BA_ "GenSigSwitchedByIgnition" SG_ 2463978697 SAL_Kl_15_vFzg 0;
BA_ "GenSigSendType" SG_ 2463978697 SAL_Kl_15_vFzg_S 3;
BA_ "GenSigSwitchedByIgnition" SG_ 2463978697 SAL_Kl_15_vFzg_S 0;
BA_ "GenSigSendType" SG_ 2463978697 SAL_KL_50 3;
BA_ "GenSigSwitchedByIgnition" SG_ 2463978697 SAL_KL_50 0;
BA_ "GenSigSendType" SG_ 2463978697 SAL_KL_50_5s 3;
BA_ "GenSigSwitchedByIgnition" SG_ 2463978697 SAL_KL_50_5s 0;
BA_ "GenSigSendType" SG_ 2463978697 SAL_Kl_75 3;
BA_ "GenSigSwitchedByIgnition" SG_ 2463978697 SAL_Kl_75 0;
BA_ "GenSigSendType" SG_ 2463978697 SAL_KL_75_vFzg 3;
BA_ "GenSigSwitchedByIgnition" SG_ 2463978697 SAL_KL_75_vFzg 0;
BA_ "GenSigSendType" SG_ 2463978697 SAL_KL_75a 3;
BA_ "GenSigSwitchedByIgnition" SG_ 2463978697 SAL_KL_75a 0;
BA_ "GenSigSendType" SG_ 2463978697 SAL_KL_75a_vFzg 3;
BA_ "GenSigSwitchedByIgnition" SG_ 2463978697 SAL_KL_75a_vFzg 0;
BA_ "GenSigSendType" SG_ 2463978697 SAL_KZL_Anf 4;
BA_ "GenSigSwitchedByIgnition" SG_ 2463978697 SAL_KZL_Anf 0;
BA_ "GenSigSendType" SG_ 2463978697 SAL_LDS_Abblendlicht_Anf 4;
BA_ "GenSigSwitchedByIgnition" SG_ 2463978697 SAL_LDS_Abblendlicht_Anf 0;
BA_ "GenSigSendType" SG_ 2463978697 SAL_LDS_Assistenzfahrlicht_Anf 4;
BA_ "GenSigSwitchedByIgnition" SG_ 2463978697 SAL_LDS_Assistenzfahrlicht_Anf 0;
BA_ "GenSigSendType" SG_ 2463978697 SAL_LDS_Nullstellung_Anf 4;
BA_ "GenSigSwitchedByIgnition" SG_ 2463978697 SAL_LDS_Nullstellung_Anf 0;
BA_ "GenSigSendType" SG_ 2463978697 SAL_LDS_Standlicht_Anf 4;
BA_ "GenSigSwitchedByIgnition" SG_ 2463978697 SAL_LDS_Standlicht_Anf 0;
BA_ "GenSigSendType" SG_ 2463978697 SAL_LH_Anf 4;
BA_ "GenSigSwitchedByIgnition" SG_ 2463978697 SAL_LH_Anf 0;
BA_ "GenSigSendType" SG_ 2463978697 SAL_NSL_Anf 4;
BA_ "GenSigSwitchedByIgnition" SG_ 2463978697 SAL_NSL_Anf 0;
BA_ "GenSigSendType" SG_ 2463978697 SAL_PL_L_Anf 4;
BA_ "GenSigSwitchedByIgnition" SG_ 2463978697 SAL_PL_L_Anf 0;
BA_ "GenSigSendType" SG_ 2463978697 SAL_PL_R_Anf 4;
BA_ "GenSigSwitchedByIgnition" SG_ 2463978697 SAL_PL_R_Anf 0;
BA_ "GenSigSendType" SG_ 2463978697 SAL_RFL_Anf 4;
BA_ "GenSigSwitchedByIgnition" SG_ 2463978697 SAL_RFL_Anf 0;
BA_ "GenSigSendType" SG_ 2463978697 SAL_SL_Anf 4;
BA_ "GenSigSwitchedByIgnition" SG_ 2463978697 SAL_SL_Anf 0;
BA_ "GenSigSendType" SG_ 2463978697 SAL_WBT_Bel 4;
BA_ "GenSigSwitchedByIgnition" SG_ 2463978697 SAL_WBT_Bel 0;
BA_ "GenSigSendType" SG_ 2463978697 SBBR_SL_AnimDimm_Freigabe 3;
BA_ "GenSigSwitchedByIgnition" SG_ 2463978697 SBBR_SL_AnimDimm_Freigabe 0;
BA_ "GenSigSendType" SG_ 980 BH_Blinker_Fehler 4;
BA_ "GenSigSwitchedByIgnition" SG_ 980 BH_Blinker_Fehler 0;
BA_ "Fehlerwert" SG_ 980 BH_Blinker_Fehler 1;
BA_ "GenSigSendType" SG_ 980 BH_Blinker_li 4;
BA_ "GenSigSwitchedByIgnition" SG_ 980 BH_Blinker_li 0;
BA_ "GenSigSendType" SG_ 980 BH_Blinker_re 4;
BA_ "GenSigSwitchedByIgnition" SG_ 980 BH_Blinker_re 0;
BA_ "GenSigSendType" SG_ 980 BH_Fernlicht 3;
BA_ "GenSigSwitchedByIgnition" SG_ 980 BH_Fernlicht 0;
BA_ "GenSigSendType" SG_ 980 BH_Lichthupe 4;
BA_ "GenSigSwitchedByIgnition" SG_ 980 BH_Lichthupe 0;
BA_ "GenSigSendType" SG_ 980 FAS_Taster 3;
BA_ "GenSigSwitchedByIgnition" SG_ 980 FAS_Taster 0;
BA_ "GenSigSendType" SG_ 980 FAS_Taster_Fehler 3;
BA_ "GenSigSwitchedByIgnition" SG_ 980 FAS_Taster_Fehler 0;
BA_ "Fehlerwert" SG_ 980 FAS_Taster_Fehler 1;
BA_ "GenSigSendType" SG_ 980 LRH_aktiv 3;
BA_ "GenSigSwitchedByIgnition" SG_ 980 LRH_aktiv 0;
BA_ "GenSigSendType" SG_ 980 LRH_On_Off 3;
BA_ "GenSigSwitchedByIgnition" SG_ 980 LRH_On_Off 0;
BA_ "Fehlerwert" SG_ 980 LRH_On_Off 3;
BA_ "GenSigSendType" SG_ 980 LSS_Tastencode 3;
BA_ "GenSigSwitchedByIgnition" SG_ 980 LSS_Tastencode 0;
BA_ "GenSigSendType" SG_ 980 SMLS_01_BZ 0;
BA_ "GenSigFuncType" SG_ 980 SMLS_01_BZ 1;
BA_ "GenSigSwitchedByIgnition" SG_ 980 SMLS_01_BZ 0;
BA_ "GenSigSendType" SG_ 980 SMLS_01_CRC 0;
BA_ "GenSigFuncType" SG_ 980 SMLS_01_CRC 2;
BA_ "GenSigSwitchedByIgnition" SG_ 980 SMLS_01_CRC 0;
BA_ "GenSigSendType" SG_ 980 SMLS_Hupe 4;
BA_ "GenSigSwitchedByIgnition" SG_ 980 SMLS_Hupe 0;
BA_ "GenSigSendType" SG_ 980 SMLS_P_verriegelt 4;
BA_ "GenSigSwitchedByIgnition" SG_ 980 SMLS_P_verriegelt 0;
BA_ "Fehlerwert" SG_ 980 SMLS_P_verriegelt 3;
BA_ "GenSigSendType" SG_ 980 SMLS_P_verriegelt_plausibel 3;
BA_ "GenSigSwitchedByIgnition" SG_ 980 SMLS_P_verriegelt_plausibel 0;
BA_ "GenSigSendType" SG_ 980 SMLS_PTT 4;
BA_ "GenSigSendType" SG_ 980 WH_Frontwaschen 3;
BA_ "GenSigSwitchedByIgnition" SG_ 980 WH_Frontwaschen 0;
BA_ "GenSigSendType" SG_ 980 WH_Heckintervall 3;
BA_ "GenSigSwitchedByIgnition" SG_ 980 WH_Heckintervall 0;
BA_ "GenSigSendType" SG_ 980 WH_Heckwaschen 3;
BA_ "GenSigSwitchedByIgnition" SG_ 980 WH_Heckwaschen 0;
BA_ "GenSigSendType" SG_ 980 WH_Intervall 3;
BA_ "GenSigSwitchedByIgnition" SG_ 980 WH_Intervall 0;
BA_ "GenSigSendType" SG_ 980 WH_Intervallstufen 3;
BA_ "GenSigSwitchedByIgnition" SG_ 980 WH_Intervallstufen 0;
BA_ "Fehlerwert" SG_ 980 WH_Intervallstufen 15;
BA_ "GenSigMissingSourceValue" SG_ 980 WH_Intervallstufen 15;
BA_ "GenSigSendType" SG_ 980 WH_SRA 3;
BA_ "GenSigSwitchedByIgnition" SG_ 980 WH_SRA 0;
BA_ "GenSigSendType" SG_ 980 WH_Tipwischen 4;
BA_ "GenSigSwitchedByIgnition" SG_ 980 WH_Tipwischen 0;
BA_ "GenSigSendType" SG_ 980 WH_Tipwischen_lang 4;
BA_ "GenSigSwitchedByIgnition" SG_ 980 WH_Tipwischen_lang 0;
BA_ "GenSigSendType" SG_ 980 WH_Wischer_Fehler 3;
BA_ "GenSigSwitchedByIgnition" SG_ 980 WH_Wischer_Fehler 0;
BA_ "Fehlerwert" SG_ 980 WH_Wischer_Fehler 1;
BA_ "GenSigSendType" SG_ 980 WH_WischerStufe1 3;
BA_ "GenSigSwitchedByIgnition" SG_ 980 WH_WischerStufe1 0;
BA_ "GenSigSendType" SG_ 980 WH_WischerStufe2 3;
BA_ "GenSigSwitchedByIgnition" SG_ 980 WH_WischerStufe2 0;
BA_ "GenSigSendType" SG_ 2464153679 SOK_FoD_Kamera_Req_Challenge 3;
BA_ "GenSigSwitchedByIgnition" SG_ 2464153679 SOK_FoD_Kamera_Req_Challenge 0;
BA_ "GenSigSendType" SG_ 2464284751 SOK_FoD_Kamera_Resp_Challenge 3;
BA_ "GenSigSwitchedByIgnition" SG_ 2464284751 SOK_FoD_Kamera_Resp_Challenge 0;
BA_ "GenSigSendType" SG_ 2464155061 SOK_FR_Auth_NAD_Challenge 3;
BA_ "GenSigSwitchedByIgnition" SG_ 2464155061 SOK_FR_Auth_NAD_Challenge 0;
BA_ "GenSigSendType" SG_ 2464286133 FaceRec_Status 3;
BA_ "GenSigSwitchedByIgnition" SG_ 2464286133 FaceRec_Status 0;
BA_ "GenSigSendType" SG_ 2464286133 FaceRec_Status_UserId 3;
BA_ "GenSigSwitchedByIgnition" SG_ 2464286133 FaceRec_Status_UserId 0;
BA_ "GenSigSendType" SG_ 2464286133 SOK_FR_Auth_NAD_Signatur 3;
BA_ "GenSigFuncType" SG_ 2464286133 SOK_FR_Auth_NAD_Signatur 15;
BA_ "GenSigSwitchedByIgnition" SG_ 2464286133 SOK_FR_Auth_NAD_Signatur 0;
BA_ "GenSigSendType" SG_ 2464153657 SOK_FR_Enroll_MIK_Challenge 3;
BA_ "GenSigSwitchedByIgnition" SG_ 2464153657 SOK_FR_Enroll_MIK_Challenge 0;
BA_ "GenSigSendType" SG_ 2464284729 FaceRec_Control 3;
BA_ "GenSigSwitchedByIgnition" SG_ 2464284729 FaceRec_Control 0;
BA_ "GenSigSendType" SG_ 2464284729 FaceRec_Control_UserId 3;
BA_ "GenSigSwitchedByIgnition" SG_ 2464284729 FaceRec_Control_UserId 0;
BA_ "GenSigSendType" SG_ 2464284729 SOK_FR_Enroll_MIK_Signatur 3;
BA_ "GenSigFuncType" SG_ 2464284729 SOK_FR_Enroll_MIK_Signatur 15;
BA_ "GenSigSwitchedByIgnition" SG_ 2464284729 SOK_FR_Enroll_MIK_Signatur 0;
BA_ "GenSigSendType" SG_ 2589283756 SOK_ungeschuetzte_Zeit 3;
BA_ "GenSigSwitchedByIgnition" SG_ 2589283756 SOK_ungeschuetzte_Zeit 0;
BA_ "GenSigSendType" SG_ 1413 GW_KD_Fehler 3;
BA_ "GenSigSendType" SG_ 1413 SI_BUS_01 3;
BA_ "GenSigStartValue" SG_ 1413 SI_BUS_01 1;
BA_ "GenSigSwitchedByIgnition" SG_ 1413 SI_BUS_01 0;
BA_ "GenSigSendType" SG_ 1413 SI_BUS_02 3;
BA_ "GenSigStartValue" SG_ 1413 SI_BUS_02 1;
BA_ "GenSigSwitchedByIgnition" SG_ 1413 SI_BUS_02 0;
BA_ "GenSigSendType" SG_ 1413 SI_BUS_03 3;
BA_ "GenSigStartValue" SG_ 1413 SI_BUS_03 1;
BA_ "GenSigSwitchedByIgnition" SG_ 1413 SI_BUS_03 0;
BA_ "GenSigSendType" SG_ 1413 SI_BUS_04 3;
BA_ "GenSigStartValue" SG_ 1413 SI_BUS_04 1;
BA_ "GenSigSwitchedByIgnition" SG_ 1413 SI_BUS_04 0;
BA_ "GenSigSendType" SG_ 1413 SI_BUS_05 3;
BA_ "GenSigStartValue" SG_ 1413 SI_BUS_05 1;
BA_ "GenSigSwitchedByIgnition" SG_ 1413 SI_BUS_05 0;
BA_ "GenSigSendType" SG_ 1413 SI_BUS_06 3;
BA_ "GenSigStartValue" SG_ 1413 SI_BUS_06 1;
BA_ "GenSigSwitchedByIgnition" SG_ 1413 SI_BUS_06 0;
BA_ "GenSigSendType" SG_ 1413 SI_BUS_07 3;
BA_ "GenSigStartValue" SG_ 1413 SI_BUS_07 1;
BA_ "GenSigSwitchedByIgnition" SG_ 1413 SI_BUS_07 0;
BA_ "GenSigSendType" SG_ 1413 SI_BUS_08 3;
BA_ "GenSigStartValue" SG_ 1413 SI_BUS_08 1;
BA_ "GenSigSwitchedByIgnition" SG_ 1413 SI_BUS_08 0;
BA_ "GenSigSendType" SG_ 1413 SI_BUS_09 3;
BA_ "GenSigStartValue" SG_ 1413 SI_BUS_09 1;
BA_ "GenSigSwitchedByIgnition" SG_ 1413 SI_BUS_09 0;
BA_ "GenSigSendType" SG_ 1413 SI_BUS_10 3;
BA_ "GenSigStartValue" SG_ 1413 SI_BUS_10 1;
BA_ "GenSigSwitchedByIgnition" SG_ 1413 SI_BUS_10 0;
BA_ "GenSigSendType" SG_ 1413 SI_BUS_11 3;
BA_ "GenSigStartValue" SG_ 1413 SI_BUS_11 1;
BA_ "GenSigSwitchedByIgnition" SG_ 1413 SI_BUS_11 0;
BA_ "GenSigSendType" SG_ 1413 SI_BUS_12 3;
BA_ "GenSigStartValue" SG_ 1413 SI_BUS_12 1;
BA_ "GenSigSwitchedByIgnition" SG_ 1413 SI_BUS_12 0;
BA_ "GenSigSendType" SG_ 1413 SI_BUS_13 3;
BA_ "GenSigStartValue" SG_ 1413 SI_BUS_13 1;
BA_ "GenSigSwitchedByIgnition" SG_ 1413 SI_BUS_13 0;
BA_ "GenSigSendType" SG_ 1413 SI_BUS_14 3;
BA_ "GenSigStartValue" SG_ 1413 SI_BUS_14 1;
BA_ "GenSigSwitchedByIgnition" SG_ 1413 SI_BUS_14 0;
BA_ "GenSigSendType" SG_ 1413 SI_BUS_15 3;
BA_ "GenSigStartValue" SG_ 1413 SI_BUS_15 1;
BA_ "GenSigSwitchedByIgnition" SG_ 1413 SI_BUS_15 0;
BA_ "GenSigSendType" SG_ 1413 SI_Bus_Identifikation 0;
BA_ "GenSigSwitchedByIgnition" SG_ 1413 SI_Bus_Identifikation 0;
BA_ "GenSigSendType" SG_ 1413 SI_CAB_V15 3;
BA_ "GenSigSwitchedByIgnition" SG_ 1413 SI_CAB_V15 0;
BA_ "GenSigSendType" SG_ 1413 SI_Diagnose_Aktiv 3;
BA_ "GenSigSwitchedByIgnition" SG_ 1413 SI_Diagnose_Aktiv 0;
BA_ "GenSigSendType" SG_ 1413 SI_NWDF 3;
BA_ "GenSigSwitchedByIgnition" SG_ 1413 SI_NWDF 0;
BA_ "GenSigSendType" SG_ 1413 SI_NWDF_gueltig 3;
BA_ "GenSigFuncType" SG_ 1413 SI_NWDF_gueltig 8;
BA_ "GenSigSwitchedByIgnition" SG_ 1413 SI_NWDF_gueltig 0;
BA_ "GenSigSendType" SG_ 1413 SI_P_Mode 3;
BA_ "GenSigSwitchedByIgnition" SG_ 1413 SI_P_Mode 0;
BA_ "GenSigSendType" SG_ 1413 SI_P_Mode_gueltig 3;
BA_ "GenSigSwitchedByIgnition" SG_ 1413 SI_P_Mode_gueltig 0;
BA_ "GenSigSendType" SG_ 1413 SI_QRS_Mode 3;
BA_ "GenSigSwitchedByIgnition" SG_ 1413 SI_QRS_Mode 0;
BA_ "GenSigSendType" SG_ 1413 SI_Sammel_SG_Fehler 0;
BA_ "GenSigStartValue" SG_ 1413 SI_Sammel_SG_Fehler 63;
BA_ "GenSigSwitchedByIgnition" SG_ 1413 SI_Sammel_SG_Fehler 0;
BA_ "GenSigSendType" SG_ 1413 SI_Sammelfehler 3;
BA_ "GenSigSwitchedByIgnition" SG_ 1413 SI_Sammelfehler 0;
BA_ "GenSigSendType" SG_ 1413 SI_T_Mode 3;
BA_ "GenSigSwitchedByIgnition" SG_ 1413 SI_T_Mode 0;
BA_ "GenSigSendType" SG_ 1413 SI_T_Schutz 3;
BA_ "GenSigSwitchedByIgnition" SG_ 1413 SI_T_Schutz 0;
BA_ "GenSigSendType" SG_ 2589283775 Diagnose_ActLine 3;
BA_ "GenSigSwitchedByIgnition" SG_ 2589283775 Diagnose_ActLine 0;
BA_ "GenSigSendType" SG_ 2589283775 Diagnose_OffBoard 3;
BA_ "GenSigSwitchedByIgnition" SG_ 2589283775 Diagnose_OffBoard 0;
BA_ "GenSigSendType" SG_ 2589283775 Diagnose_OnBoard 3;
BA_ "GenSigSwitchedByIgnition" SG_ 2589283775 Diagnose_OnBoard 0;
BA_ "GenSigSendType" SG_ 2589283775 NM_aktiv_Buskopplung 3;
BA_ "GenSigSwitchedByIgnition" SG_ 2589283775 NM_aktiv_Buskopplung 0;
BA_ "GenSigSendType" SG_ 2589283775 NM_aktiv_CAB 3;
BA_ "GenSigSwitchedByIgnition" SG_ 2589283775 NM_aktiv_CAB 0;
BA_ "GenSigSendType" SG_ 2589283775 NM_aktiv_CWU 3;
BA_ "GenSigSwitchedByIgnition" SG_ 2589283775 NM_aktiv_CWU 0;
BA_ "GenSigSendType" SG_ 2589283775 NM_Req_CMS 3;
BA_ "GenSigSwitchedByIgnition" SG_ 2589283775 NM_Req_CMS 0;
BA_ "GenSigSendType" SG_ 2589283775 NM_Req_DCP_01 3;
BA_ "GenSigSwitchedByIgnition" SG_ 2589283775 NM_Req_DCP_01 0;
BA_ "GenSigSendType" SG_ 2589283775 NM_Req_DCP_02 3;
BA_ "GenSigSwitchedByIgnition" SG_ 2589283775 NM_Req_DCP_02 0;
BA_ "GenSigSendType" SG_ 2589283775 NM_Req_DIM 3;
BA_ "GenSigSwitchedByIgnition" SG_ 2589283775 NM_Req_DIM 0;
BA_ "GenSigSendType" SG_ 2589283775 NM_Req_ECM 3;
BA_ "GenSigSwitchedByIgnition" SG_ 2589283775 NM_Req_ECM 0;
BA_ "GenSigSendType" SG_ 2589283775 NM_Req_EMHLR 3;
BA_ "GenSigSwitchedByIgnition" SG_ 2589283775 NM_Req_EMHLR 0;
BA_ "GenSigSendType" SG_ 2589283775 NM_Req_EOC 3;
BA_ "GenSigSwitchedByIgnition" SG_ 2589283775 NM_Req_EOC 0;
BA_ "GenSigSendType" SG_ 2589283775 NM_Req_FoD 3;
BA_ "GenSigSwitchedByIgnition" SG_ 2589283775 NM_Req_FoD 0;
BA_ "GenSigSendType" SG_ 2589283775 NM_Req_HVEM 3;
BA_ "GenSigSwitchedByIgnition" SG_ 2589283775 NM_Req_HVEM 0;
BA_ "GenSigSendType" SG_ 2589283775 NM_Req_IAA_PSO 3;
BA_ "GenSigSwitchedByIgnition" SG_ 2589283775 NM_Req_IAA_PSO 0;
BA_ "GenSigSendType" SG_ 2589283775 NM_Req_internal 3;
BA_ "GenSigSwitchedByIgnition" SG_ 2589283775 NM_Req_internal 0;
BA_ "GenSigSendType" SG_ 2589283775 NM_Req_Kessy 3;
BA_ "GenSigSwitchedByIgnition" SG_ 2589283775 NM_Req_Kessy 0;
BA_ "GenSigSendType" SG_ 2589283775 NM_Req_KLS 3;
BA_ "GenSigSwitchedByIgnition" SG_ 2589283775 NM_Req_KLS 0;
BA_ "GenSigSendType" SG_ 2589283775 NM_Req_KS 3;
BA_ "GenSigSwitchedByIgnition" SG_ 2589283775 NM_Req_KS 0;
BA_ "GenSigSendType" SG_ 2589283775 NM_Req_LIN_AI 3;
BA_ "GenSigSwitchedByIgnition" SG_ 2589283775 NM_Req_LIN_AI 0;
BA_ "GenSigSendType" SG_ 2589283775 NM_Req_LIN_EMHLR 3;
BA_ "GenSigSwitchedByIgnition" SG_ 2589283775 NM_Req_LIN_EMHLR 0;
BA_ "GenSigSendType" SG_ 2589283775 NM_Req_LIN_EOC 3;
BA_ "GenSigSwitchedByIgnition" SG_ 2589283775 NM_Req_LIN_EOC 0;
BA_ "GenSigSendType" SG_ 2589283775 NM_Req_LIN_SWC1 3;
BA_ "GenSigSwitchedByIgnition" SG_ 2589283775 NM_Req_LIN_SWC1 0;
BA_ "GenSigSendType" SG_ 2589283775 NM_Req_LIN_SWC2 3;
BA_ "GenSigSwitchedByIgnition" SG_ 2589283775 NM_Req_LIN_SWC2 0;
BA_ "GenSigSendType" SG_ 2589283775 NM_Req_LIN_SWC3 3;
BA_ "GenSigSwitchedByIgnition" SG_ 2589283775 NM_Req_LIN_SWC3 0;
BA_ "GenSigSendType" SG_ 2589283775 NM_Req_PaCo 3;
BA_ "GenSigSwitchedByIgnition" SG_ 2589283775 NM_Req_PaCo 0;
BA_ "GenSigSendType" SG_ 2589283775 NM_Req_RTM 3;
BA_ "GenSigSwitchedByIgnition" SG_ 2589283775 NM_Req_RTM 0;
BA_ "GenSigSendType" SG_ 2589283775 NM_Req_SAL 3;
BA_ "GenSigSwitchedByIgnition" SG_ 2589283775 NM_Req_SAL 0;
BA_ "GenSigSendType" SG_ 2589283775 NM_Req_STK 3;
BA_ "GenSigSwitchedByIgnition" SG_ 2589283775 NM_Req_STK 0;
BA_ "GenSigSendType" SG_ 2589283775 NM_Req_SWC1 3;
BA_ "GenSigSwitchedByIgnition" SG_ 2589283775 NM_Req_SWC1 0;
BA_ "GenSigSendType" SG_ 2589283775 NM_Req_SWC2 3;
BA_ "GenSigSwitchedByIgnition" SG_ 2589283775 NM_Req_SWC2 0;
BA_ "GenSigSendType" SG_ 2589283775 NM_Req_SWC3 3;
BA_ "GenSigSwitchedByIgnition" SG_ 2589283775 NM_Req_SWC3 0;
BA_ "GenSigSendType" SG_ 2589283775 NM_Req_SWC4 3;
BA_ "GenSigSwitchedByIgnition" SG_ 2589283775 NM_Req_SWC4 0;
BA_ "GenSigSendType" SG_ 2589283775 NM_Req_SWC5 3;
BA_ "GenSigSwitchedByIgnition" SG_ 2589283775 NM_Req_SWC5 0;
BA_ "GenSigSendType" SG_ 2589283775 NM_Req_SWC6 3;
BA_ "GenSigSwitchedByIgnition" SG_ 2589283775 NM_Req_SWC6 0;
BA_ "GenSigSendType" SG_ 2589283775 NM_Req_SWC7 3;
BA_ "GenSigSwitchedByIgnition" SG_ 2589283775 NM_Req_SWC7 0;
BA_ "GenSigSendType" SG_ 2589283775 NM_Req_SWC8 3;
BA_ "GenSigSwitchedByIgnition" SG_ 2589283775 NM_Req_SWC8 0;
BA_ "GenSigSendType" SG_ 2589283775 NM_Req_USS 3;
BA_ "GenSigSwitchedByIgnition" SG_ 2589283775 NM_Req_USS 0;
BA_ "GenSigSendType" SG_ 2589283775 NM_Req_ZM 3;
BA_ "GenSigSwitchedByIgnition" SG_ 2589283775 NM_Req_ZM 0;
BA_ "GenSigSendType" SG_ 2589283775 NM_Req_ZV 3;
BA_ "GenSigSwitchedByIgnition" SG_ 2589283775 NM_Req_ZV 0;
BA_ "GenSigSendType" SG_ 2589283775 Powerstate_Act 3;
BA_ "GenSigSwitchedByIgnition" SG_ 2589283775 Powerstate_Act 0;
BA_ "GenSigSendType" SG_ 2589283775 Powerstate_Time 3;
BA_ "GenSigSwitchedByIgnition" SG_ 2589283775 Powerstate_Time 0;
BA_ "GenSigSendType" SG_ 2589283947 NM_Reason_CMS 3;
BA_ "GenSigSwitchedByIgnition" SG_ 2589283947 NM_Reason_CMS 0;
BA_ "GenSigSendType" SG_ 2589283947 NM_Reason_DCP_1 3;
BA_ "GenSigSwitchedByIgnition" SG_ 2589283947 NM_Reason_DCP_1 0;
BA_ "GenSigSendType" SG_ 2589283947 NM_Reason_DCP_2 3;
BA_ "GenSigSwitchedByIgnition" SG_ 2589283947 NM_Reason_DCP_2 0;
BA_ "GenSigSendType" SG_ 2589283947 NM_Reason_DIM 3;
BA_ "GenSigSwitchedByIgnition" SG_ 2589283947 NM_Reason_DIM 0;
BA_ "GenSigSendType" SG_ 2589283947 NM_Reason_ECM 3;
BA_ "GenSigSwitchedByIgnition" SG_ 2589283947 NM_Reason_ECM 0;
BA_ "GenSigSendType" SG_ 2589283947 NM_Reason_EMHLR 3;
BA_ "GenSigSwitchedByIgnition" SG_ 2589283947 NM_Reason_EMHLR 0;
BA_ "GenSigSendType" SG_ 2589283947 NM_Reason_EOC 3;
BA_ "GenSigSwitchedByIgnition" SG_ 2589283947 NM_Reason_EOC 0;
BA_ "GenSigSendType" SG_ 2589283947 NM_Reason_FoD 3;
BA_ "GenSigSwitchedByIgnition" SG_ 2589283947 NM_Reason_FoD 0;
BA_ "GenSigSendType" SG_ 2589283947 NM_Reason_HVEM 3;
BA_ "GenSigSwitchedByIgnition" SG_ 2589283947 NM_Reason_HVEM 0;
BA_ "GenSigSendType" SG_ 2589283947 NM_Reason_IAA_PSO 3;
BA_ "GenSigSwitchedByIgnition" SG_ 2589283947 NM_Reason_IAA_PSO 0;
BA_ "GenSigSendType" SG_ 2589283947 NM_Reason_ICAS1_internal 3;
BA_ "GenSigSwitchedByIgnition" SG_ 2589283947 NM_Reason_ICAS1_internal 0;
BA_ "GenSigSendType" SG_ 2589283947 NM_Reason_Kessy 3;
BA_ "GenSigSwitchedByIgnition" SG_ 2589283947 NM_Reason_Kessy 0;
BA_ "GenSigSendType" SG_ 2589283947 NM_Reason_KLS 3;
BA_ "GenSigSwitchedByIgnition" SG_ 2589283947 NM_Reason_KLS 0;
BA_ "GenSigSendType" SG_ 2589283947 NM_Reason_KS 3;
BA_ "GenSigSwitchedByIgnition" SG_ 2589283947 NM_Reason_KS 0;
BA_ "GenSigSendType" SG_ 2589283947 NM_Reason_PaCo 3;
BA_ "GenSigSwitchedByIgnition" SG_ 2589283947 NM_Reason_PaCo 0;
BA_ "GenSigSendType" SG_ 2589283947 NM_Reason_RTM 3;
BA_ "GenSigSwitchedByIgnition" SG_ 2589283947 NM_Reason_RTM 0;
BA_ "GenSigSendType" SG_ 2589283947 NM_Reason_SAL 3;
BA_ "GenSigSwitchedByIgnition" SG_ 2589283947 NM_Reason_SAL 0;
BA_ "GenSigSendType" SG_ 2589283947 NM_Reason_STK 3;
BA_ "GenSigSwitchedByIgnition" SG_ 2589283947 NM_Reason_STK 0;
BA_ "GenSigSendType" SG_ 2589283947 NM_Reason_SWC1 3;
BA_ "GenSigSwitchedByIgnition" SG_ 2589283947 NM_Reason_SWC1 0;
BA_ "GenSigSendType" SG_ 2589283947 NM_Reason_SWC2 3;
BA_ "GenSigSwitchedByIgnition" SG_ 2589283947 NM_Reason_SWC2 0;
BA_ "GenSigSendType" SG_ 2589283947 NM_Reason_SWC3 3;
BA_ "GenSigSwitchedByIgnition" SG_ 2589283947 NM_Reason_SWC3 0;
BA_ "GenSigSendType" SG_ 2589283947 NM_Reason_SWC4 3;
BA_ "GenSigSwitchedByIgnition" SG_ 2589283947 NM_Reason_SWC4 0;
BA_ "GenSigSendType" SG_ 2589283947 NM_Reason_SWC5 3;
BA_ "GenSigSwitchedByIgnition" SG_ 2589283947 NM_Reason_SWC5 0;
BA_ "GenSigSendType" SG_ 2589283947 NM_Reason_SWC6 3;
BA_ "GenSigSwitchedByIgnition" SG_ 2589283947 NM_Reason_SWC6 0;
BA_ "GenSigSendType" SG_ 2589283947 NM_Reason_SWC7 3;
BA_ "GenSigSwitchedByIgnition" SG_ 2589283947 NM_Reason_SWC7 0;
BA_ "GenSigSendType" SG_ 2589283947 NM_Reason_SWC8 3;
BA_ "GenSigSwitchedByIgnition" SG_ 2589283947 NM_Reason_SWC8 0;
BA_ "GenSigSendType" SG_ 2589283947 NM_Reason_USS 3;
BA_ "GenSigSwitchedByIgnition" SG_ 2589283947 NM_Reason_USS 0;
BA_ "GenSigSendType" SG_ 2589283947 NM_Reason_ZM 3;
BA_ "GenSigSwitchedByIgnition" SG_ 2589283947 NM_Reason_ZM 0;
BA_ "GenSigSendType" SG_ 2589283947 NM_Reason_ZV 3;
BA_ "GenSigSwitchedByIgnition" SG_ 2589283947 NM_Reason_ZV 0;
BA_ "GenSigSendType" SG_ 2589283947 Powerstate_Prev_01 3;
BA_ "GenSigSwitchedByIgnition" SG_ 2589283947 Powerstate_Prev_01 0;
BA_ "GenSigSendType" SG_ 2589283947 Powerstate_Prev_02 3;
BA_ "GenSigSwitchedByIgnition" SG_ 2589283947 Powerstate_Prev_02 0;
BA_ "GenSigSendType" SG_ 619 TA_01_BZ 0;
BA_ "GenSigFuncType" SG_ 619 TA_01_BZ 1;
BA_ "GenSigSwitchedByIgnition" SG_ 619 TA_01_BZ 0;
BA_ "GenSigSendType" SG_ 619 TA_01_CRC 0;
BA_ "GenSigFuncType" SG_ 619 TA_01_CRC 2;
BA_ "GenSigSwitchedByIgnition" SG_ 619 TA_01_CRC 0;
BA_ "GenSigSendType" SG_ 619 TA_ACC_Sollstatus 3;
BA_ "GenSigSendType" SG_ 619 TA_aktiv_HMI 0;
BA_ "GenSigSwitchedByIgnition" SG_ 619 TA_aktiv_HMI 0;
BA_ "GenSigSendType" SG_ 619 TA_Fehler 0;
BA_ "GenSigSwitchedByIgnition" SG_ 619 TA_Fehler 0;
BA_ "GenSigSendType" SG_ 619 TA_FoD_Status 3;
BA_ "GenSigSwitchedByIgnition" SG_ 619 TA_FoD_Status 0;
BA_ "GenSigSendType" SG_ 619 TA_Handsoff_LED 0;
BA_ "GenSigSendType" SG_ 619 TA_Spurwechsel 0;
BA_ "GenSigSwitchedByIgnition" SG_ 619 TA_Spurwechsel 0;
BA_ "GenSigSendType" SG_ 619 TA_Spurwechsel_Ready 3;
BA_ "GenSigSwitchedByIgnition" SG_ 619 TA_Spurwechsel_Ready 0;
BA_ "GenSigSendType" SG_ 619 TA_Status 0;
BA_ "GenSigSendType" SG_ 619 TA_Texte 0;
BA_ "GenSigSendType" SG_ 619 TA_Texte_02 0;
BA_ "GenSigSendType" SG_ 619 TA_Ueberholhilfe 0;
BA_ "GenSigSendType" SG_ 2589283750 KBI_Aussen_Temp_gef 0;
BA_ "GenSigStartValue" SG_ 2589283750 KBI_Aussen_Temp_gef 254;
BA_ "GenSigSwitchedByIgnition" SG_ 2589283750 KBI_Aussen_Temp_gef 0;
BA_ "Fehlerwert" SG_ 2589283750 KBI_Aussen_Temp_gef 255;
BA_ "GenSigSendType" SG_ 2589283750 KBI_QBit_Aussen_Temp_gef 0;
BA_ "GenSigStartValue" SG_ 2589283750 KBI_QBit_Aussen_Temp_gef 1;
BA_ "GenSigSwitchedByIgnition" SG_ 2589283750 KBI_QBit_Aussen_Temp_gef 0;
BA_ "GenSigSendType" SG_ 165 TS_CAN_Ma_CRC 0;
BA_ "GenSigFuncType" SG_ 165 TS_CAN_Ma_CRC 2;
BA_ "GenSigSendType" SG_ 165 TS_CAN_Ma_OVS 0;
BA_ "GenSigSendType" SG_ 165 TS_CAN_Ma_SequenceCounter 0;
BA_ "GenSigSendType" SG_ 165 TS_CAN_Ma_SGW 0;
BA_ "GenSigSendType" SG_ 165 TS_CAN_Ma_SyncTimeSec 0;
BA_ "GenSigSendType" SG_ 165 TS_CAN_Ma_TimeDomain 0;
BA_ "GenSigSendType" SG_ 165 TS_CAN_Ma_Type 3;
BA_ "GenSigSwitchedByIgnition" SG_ 165 TS_CAN_Ma_Type 0;
BA_ "GenSigSendType" SG_ 2264486930 TLT_CurRTTNs_ACC_01 0;
BA_ "GenSigSwitchedByIgnition" SG_ 2264486930 TLT_CurRTTNs_ACC_01 0;
BA_ "GenSigSendType" SG_ 2264486930 TLT_CurRTTS_ACC_01 0;
BA_ "GenSigSwitchedByIgnition" SG_ 2264486930 TLT_CurRTTS_ACC_01 0;
BA_ "GenSigSendType" SG_ 2264486930 TLT_CurSlaveTimestampNs_ACC_01 0;
BA_ "GenSigSwitchedByIgnition" SG_ 2264486930 TLT_CurSlaveTimestampNs_ACC_01 0;
BA_ "GenSigSendType" SG_ 2264486930 TLT_CurSlaveTimestampS_ACC_01 0;
BA_ "GenSigSwitchedByIgnition" SG_ 2264486930 TLT_CurSlaveTimestampS_ACC_01 0;
BA_ "GenSigSendType" SG_ 2264486930 TLT_ErrorMaxNs_ACC_01 0;
BA_ "GenSigSwitchedByIgnition" SG_ 2264486930 TLT_ErrorMaxNs_ACC_01 0;
BA_ "GenSigSendType" SG_ 2264486930 TLT_ErrorMinNs_ACC_01 0;
BA_ "GenSigSwitchedByIgnition" SG_ 2264486930 TLT_ErrorMinNs_ACC_01 0;
BA_ "GenSigSendType" SG_ 2264486930 TLT_ReqMsgType_ACC_01 0;
BA_ "GenSigSwitchedByIgnition" SG_ 2264486930 TLT_ReqMsgType_ACC_01 0;
BA_ "Fehlerwert" SG_ 2264486930 TLT_ReqMsgType_ACC_01 7;
BA_ "GenSigSendType" SG_ 2264486930 TLT_ReqProtocolType_ACC_01 0;
BA_ "GenSigSwitchedByIgnition" SG_ 2264486930 TLT_ReqProtocolType_ACC_01 0;
BA_ "Fehlerwert" SG_ 2264486930 TLT_ReqProtocolType_ACC_01 7;
BA_ "GenSigSendType" SG_ 2264486930 TLT_ReqSequenceID_ACC_01 0;
BA_ "GenSigStartValue" SG_ 2264486930 TLT_ReqSequenceID_ACC_01 65534;
BA_ "GenSigSwitchedByIgnition" SG_ 2264486930 TLT_ReqSequenceID_ACC_01 0;
BA_ "Fehlerwert" SG_ 2264486930 TLT_ReqSequenceID_ACC_01 65535;
BA_ "GenSigSendType" SG_ 2264486930 TLT_ReqSlaveID_ACC_01 0;
BA_ "GenSigStartValue" SG_ 2264486930 TLT_ReqSlaveID_ACC_01 254;
BA_ "GenSigSwitchedByIgnition" SG_ 2264486930 TLT_ReqSlaveID_ACC_01 0;
BA_ "Fehlerwert" SG_ 2264486930 TLT_ReqSlaveID_ACC_01 255;
BA_ "GenSigSendType" SG_ 2264486928 TLT_CurRTTNs_Kamera 0;
BA_ "GenSigSwitchedByIgnition" SG_ 2264486928 TLT_CurRTTNs_Kamera 0;
BA_ "GenSigSendType" SG_ 2264486928 TLT_CurRTTS_Kamera 0;
BA_ "GenSigSwitchedByIgnition" SG_ 2264486928 TLT_CurRTTS_Kamera 0;
BA_ "GenSigSendType" SG_ 2264486928 TLT_CurSlaveTimestampNs_Kamera 0;
BA_ "GenSigSwitchedByIgnition" SG_ 2264486928 TLT_CurSlaveTimestampNs_Kamera 0;
BA_ "GenSigSendType" SG_ 2264486928 TLT_CurSlaveTimestampS_Kamera 0;
BA_ "GenSigSwitchedByIgnition" SG_ 2264486928 TLT_CurSlaveTimestampS_Kamera 0;
BA_ "GenSigSendType" SG_ 2264486928 TLT_ErrorMaxNs_Kamera 0;
BA_ "GenSigSwitchedByIgnition" SG_ 2264486928 TLT_ErrorMaxNs_Kamera 0;
BA_ "GenSigSendType" SG_ 2264486928 TLT_ErrorMinNs_Kamera 0;
BA_ "GenSigSwitchedByIgnition" SG_ 2264486928 TLT_ErrorMinNs_Kamera 0;
BA_ "GenSigSendType" SG_ 2264486928 TLT_Req_Kamera_BZ 0;
BA_ "GenSigFuncType" SG_ 2264486928 TLT_Req_Kamera_BZ 1;
BA_ "GenSigSwitchedByIgnition" SG_ 2264486928 TLT_Req_Kamera_BZ 0;
BA_ "GenSigSendType" SG_ 2264486928 TLT_Req_Kamera_CRC 0;
BA_ "GenSigFuncType" SG_ 2264486928 TLT_Req_Kamera_CRC 2;
BA_ "GenSigSwitchedByIgnition" SG_ 2264486928 TLT_Req_Kamera_CRC 0;
BA_ "GenSigSendType" SG_ 2264486928 TLT_ReqMsgType_Kamera 0;
BA_ "GenSigSwitchedByIgnition" SG_ 2264486928 TLT_ReqMsgType_Kamera 0;
BA_ "Fehlerwert" SG_ 2264486928 TLT_ReqMsgType_Kamera 7;
BA_ "GenSigSendType" SG_ 2264486928 TLT_ReqProtocolType_Kamera 0;
BA_ "GenSigSwitchedByIgnition" SG_ 2264486928 TLT_ReqProtocolType_Kamera 0;
BA_ "Fehlerwert" SG_ 2264486928 TLT_ReqProtocolType_Kamera 7;
BA_ "GenSigSendType" SG_ 2264486928 TLT_ReqSequenceID_Kamera 0;
BA_ "GenSigStartValue" SG_ 2264486928 TLT_ReqSequenceID_Kamera 65534;
BA_ "GenSigSwitchedByIgnition" SG_ 2264486928 TLT_ReqSequenceID_Kamera 0;
BA_ "Fehlerwert" SG_ 2264486928 TLT_ReqSequenceID_Kamera 65535;
BA_ "GenSigSendType" SG_ 2264486928 TLT_ReqSlaveID_Kamera 0;
BA_ "GenSigStartValue" SG_ 2264486928 TLT_ReqSlaveID_Kamera 254;
BA_ "GenSigSwitchedByIgnition" SG_ 2264486928 TLT_ReqSlaveID_Kamera 0;
BA_ "Fehlerwert" SG_ 2264486928 TLT_ReqSlaveID_Kamera 255;
BA_ "GenSigSendType" SG_ 2264486932 TLT_CurRTTNs_NR_01 0;
BA_ "GenSigSwitchedByIgnition" SG_ 2264486932 TLT_CurRTTNs_NR_01 0;
BA_ "GenSigSendType" SG_ 2264486932 TLT_CurRTTS_NR_01 0;
BA_ "GenSigSwitchedByIgnition" SG_ 2264486932 TLT_CurRTTS_NR_01 0;
BA_ "GenSigSendType" SG_ 2264486932 TLT_CurSlaveTimestampNs_NR_01 0;
BA_ "GenSigSwitchedByIgnition" SG_ 2264486932 TLT_CurSlaveTimestampNs_NR_01 0;
BA_ "GenSigSendType" SG_ 2264486932 TLT_CurSlaveTimestampS_NR_01 0;
BA_ "GenSigSwitchedByIgnition" SG_ 2264486932 TLT_CurSlaveTimestampS_NR_01 0;
BA_ "GenSigSendType" SG_ 2264486932 TLT_ErrorMaxNs_NR_01 0;
BA_ "GenSigSwitchedByIgnition" SG_ 2264486932 TLT_ErrorMaxNs_NR_01 0;
BA_ "GenSigSendType" SG_ 2264486932 TLT_ErrorMinNs_NR_01 0;
BA_ "GenSigSwitchedByIgnition" SG_ 2264486932 TLT_ErrorMinNs_NR_01 0;
BA_ "GenSigSendType" SG_ 2264486932 TLT_Req_NR_01_BZ 0;
BA_ "GenSigFuncType" SG_ 2264486932 TLT_Req_NR_01_BZ 1;
BA_ "GenSigSendType" SG_ 2264486932 TLT_Req_NR_01_CRC 0;
BA_ "GenSigFuncType" SG_ 2264486932 TLT_Req_NR_01_CRC 2;
BA_ "GenSigSendType" SG_ 2264486932 TLT_ReqMsgType_NR_01 0;
BA_ "GenSigSwitchedByIgnition" SG_ 2264486932 TLT_ReqMsgType_NR_01 0;
BA_ "Fehlerwert" SG_ 2264486932 TLT_ReqMsgType_NR_01 7;
BA_ "GenSigSendType" SG_ 2264486932 TLT_ReqProtocolType_NR_01 0;
BA_ "GenSigSwitchedByIgnition" SG_ 2264486932 TLT_ReqProtocolType_NR_01 0;
BA_ "Fehlerwert" SG_ 2264486932 TLT_ReqProtocolType_NR_01 7;
BA_ "GenSigSendType" SG_ 2264486932 TLT_ReqSequenceID_NR_01 0;
BA_ "GenSigStartValue" SG_ 2264486932 TLT_ReqSequenceID_NR_01 65534;
BA_ "GenSigSwitchedByIgnition" SG_ 2264486932 TLT_ReqSequenceID_NR_01 0;
BA_ "Fehlerwert" SG_ 2264486932 TLT_ReqSequenceID_NR_01 65535;
BA_ "GenSigSendType" SG_ 2264486932 TLT_ReqSlaveID_NR_01 0;
BA_ "GenSigStartValue" SG_ 2264486932 TLT_ReqSlaveID_NR_01 254;
BA_ "GenSigSwitchedByIgnition" SG_ 2264486932 TLT_ReqSlaveID_NR_01 0;
BA_ "Fehlerwert" SG_ 2264486932 TLT_ReqSlaveID_NR_01 255;
BA_ "GenSigSendType" SG_ 2264486934 TLT_CurRTTNs_NR_02 0;
BA_ "GenSigSwitchedByIgnition" SG_ 2264486934 TLT_CurRTTNs_NR_02 0;
BA_ "GenSigSendType" SG_ 2264486934 TLT_CurRTTS_NR_02 0;
BA_ "GenSigSwitchedByIgnition" SG_ 2264486934 TLT_CurRTTS_NR_02 0;
BA_ "GenSigSendType" SG_ 2264486934 TLT_CurSlaveTimestampNs_NR_02 0;
BA_ "GenSigSwitchedByIgnition" SG_ 2264486934 TLT_CurSlaveTimestampNs_NR_02 0;
BA_ "GenSigSendType" SG_ 2264486934 TLT_CurSlaveTimestampS_NR_02 0;
BA_ "GenSigSwitchedByIgnition" SG_ 2264486934 TLT_CurSlaveTimestampS_NR_02 0;
BA_ "GenSigSendType" SG_ 2264486934 TLT_ErrorMaxNs_NR_02 0;
BA_ "GenSigSwitchedByIgnition" SG_ 2264486934 TLT_ErrorMaxNs_NR_02 0;
BA_ "GenSigSendType" SG_ 2264486934 TLT_ErrorMinNs_NR_02 0;
BA_ "GenSigSwitchedByIgnition" SG_ 2264486934 TLT_ErrorMinNs_NR_02 0;
BA_ "GenSigSendType" SG_ 2264486934 TLT_Req_NR_02_BZ 0;
BA_ "GenSigFuncType" SG_ 2264486934 TLT_Req_NR_02_BZ 1;
BA_ "GenSigSendType" SG_ 2264486934 TLT_Req_NR_02_CRC 0;
BA_ "GenSigFuncType" SG_ 2264486934 TLT_Req_NR_02_CRC 2;
BA_ "GenSigSendType" SG_ 2264486934 TLT_ReqMsgType_NR_02 0;
BA_ "GenSigSwitchedByIgnition" SG_ 2264486934 TLT_ReqMsgType_NR_02 0;
BA_ "Fehlerwert" SG_ 2264486934 TLT_ReqMsgType_NR_02 7;
BA_ "GenSigSendType" SG_ 2264486934 TLT_ReqProtocolType_NR_02 0;
BA_ "GenSigSwitchedByIgnition" SG_ 2264486934 TLT_ReqProtocolType_NR_02 0;
BA_ "Fehlerwert" SG_ 2264486934 TLT_ReqProtocolType_NR_02 7;
BA_ "GenSigSendType" SG_ 2264486934 TLT_ReqSequenceID_NR_02 0;
BA_ "GenSigStartValue" SG_ 2264486934 TLT_ReqSequenceID_NR_02 65534;
BA_ "GenSigSwitchedByIgnition" SG_ 2264486934 TLT_ReqSequenceID_NR_02 0;
BA_ "Fehlerwert" SG_ 2264486934 TLT_ReqSequenceID_NR_02 65535;
BA_ "GenSigSendType" SG_ 2264486934 TLT_ReqSlaveID_NR_02 0;
BA_ "GenSigStartValue" SG_ 2264486934 TLT_ReqSlaveID_NR_02 254;
BA_ "GenSigSwitchedByIgnition" SG_ 2264486934 TLT_ReqSlaveID_NR_02 0;
BA_ "Fehlerwert" SG_ 2264486934 TLT_ReqSlaveID_NR_02 255;
BA_ "GenSigSendType" SG_ 2264486931 TLT_LapCounter_ACC_01 0;
BA_ "GenSigStartValue" SG_ 2264486931 TLT_LapCounter_ACC_01 16382;
BA_ "GenSigSwitchedByIgnition" SG_ 2264486931 TLT_LapCounter_ACC_01 0;
BA_ "Fehlerwert" SG_ 2264486931 TLT_LapCounter_ACC_01 16383;
BA_ "GenSigSendType" SG_ 2264486931 TLT_ReqIngressTimestampNs_ACC_01 0;
BA_ "GenSigSwitchedByIgnition" SG_ 2264486931 TLT_ReqIngressTimestampNs_ACC_01 0;
BA_ "GenSigSendType" SG_ 2264486931 TLT_ReqIngressTimestampS_ACC_01 0;
BA_ "GenSigSwitchedByIgnition" SG_ 2264486931 TLT_ReqIngressTimestampS_ACC_01 0;
BA_ "GenSigSendType" SG_ 2264486931 TLT_Resp_ACC_01_BZ 0;
BA_ "GenSigFuncType" SG_ 2264486931 TLT_Resp_ACC_01_BZ 1;
BA_ "GenSigSwitchedByIgnition" SG_ 2264486931 TLT_Resp_ACC_01_BZ 0;
BA_ "GenSigSendType" SG_ 2264486931 TLT_Resp_ACC_01_CRC 0;
BA_ "GenSigFuncType" SG_ 2264486931 TLT_Resp_ACC_01_CRC 2;
BA_ "GenSigSwitchedByIgnition" SG_ 2264486931 TLT_Resp_ACC_01_CRC 0;
BA_ "GenSigSendType" SG_ 2264486931 TLT_RespEgressTimestampNs_ACC_01 0;
BA_ "GenSigSwitchedByIgnition" SG_ 2264486931 TLT_RespEgressTimestampNs_ACC_01 0;
BA_ "GenSigSendType" SG_ 2264486931 TLT_RespEgressTimestampS_ACC_01 0;
BA_ "GenSigSwitchedByIgnition" SG_ 2264486931 TLT_RespEgressTimestampS_ACC_01 0;
BA_ "GenSigSendType" SG_ 2264486931 TLT_RespMsgType_ACC_01 0;
BA_ "GenSigSwitchedByIgnition" SG_ 2264486931 TLT_RespMsgType_ACC_01 0;
BA_ "Fehlerwert" SG_ 2264486931 TLT_RespMsgType_ACC_01 7;
BA_ "GenSigSendType" SG_ 2264486931 TLT_RespProtocolType_ACC_01 0;
BA_ "GenSigSwitchedByIgnition" SG_ 2264486931 TLT_RespProtocolType_ACC_01 0;
BA_ "Fehlerwert" SG_ 2264486931 TLT_RespProtocolType_ACC_01 7;
BA_ "GenSigSendType" SG_ 2264486931 TLT_RespSequenceID_ACC_01 0;
BA_ "GenSigStartValue" SG_ 2264486931 TLT_RespSequenceID_ACC_01 65534;
BA_ "GenSigSwitchedByIgnition" SG_ 2264486931 TLT_RespSequenceID_ACC_01 0;
BA_ "Fehlerwert" SG_ 2264486931 TLT_RespSequenceID_ACC_01 65535;
BA_ "GenSigSendType" SG_ 2264486931 TLT_RespSlaveID_ACC_01 0;
BA_ "GenSigStartValue" SG_ 2264486931 TLT_RespSlaveID_ACC_01 254;
BA_ "GenSigSwitchedByIgnition" SG_ 2264486931 TLT_RespSlaveID_ACC_01 0;
BA_ "Fehlerwert" SG_ 2264486931 TLT_RespSlaveID_ACC_01 255;
BA_ "GenSigSendType" SG_ 2264486929 TLT_LapCounter_Kamera 0;
BA_ "GenSigStartValue" SG_ 2264486929 TLT_LapCounter_Kamera 16382;
BA_ "GenSigSwitchedByIgnition" SG_ 2264486929 TLT_LapCounter_Kamera 0;
BA_ "Fehlerwert" SG_ 2264486929 TLT_LapCounter_Kamera 16383;
BA_ "GenSigSendType" SG_ 2264486929 TLT_ReqIngressTimestampNs_Kamera 0;
BA_ "GenSigSwitchedByIgnition" SG_ 2264486929 TLT_ReqIngressTimestampNs_Kamera 0;
BA_ "GenSigSendType" SG_ 2264486929 TLT_ReqIngressTimestampS_Kamera 0;
BA_ "GenSigSwitchedByIgnition" SG_ 2264486929 TLT_ReqIngressTimestampS_Kamera 0;
BA_ "GenSigSendType" SG_ 2264486929 TLT_Resp_Kamera_BZ 0;
BA_ "GenSigFuncType" SG_ 2264486929 TLT_Resp_Kamera_BZ 1;
BA_ "GenSigSendType" SG_ 2264486929 TLT_Resp_Kamera_CRC 0;
BA_ "GenSigFuncType" SG_ 2264486929 TLT_Resp_Kamera_CRC 2;
BA_ "GenSigSendType" SG_ 2264486929 TLT_RespEgressTimestampNs_Kamera 0;
BA_ "GenSigSwitchedByIgnition" SG_ 2264486929 TLT_RespEgressTimestampNs_Kamera 0;
BA_ "GenSigSendType" SG_ 2264486929 TLT_RespEgressTimestampS_Kamera 0;
BA_ "GenSigSwitchedByIgnition" SG_ 2264486929 TLT_RespEgressTimestampS_Kamera 0;
BA_ "GenSigSendType" SG_ 2264486929 TLT_RespMsgType_Kamera 0;
BA_ "GenSigSwitchedByIgnition" SG_ 2264486929 TLT_RespMsgType_Kamera 0;
BA_ "Fehlerwert" SG_ 2264486929 TLT_RespMsgType_Kamera 7;
BA_ "GenSigSendType" SG_ 2264486929 TLT_RespProtocolType_Kamera 0;
BA_ "GenSigSwitchedByIgnition" SG_ 2264486929 TLT_RespProtocolType_Kamera 0;
BA_ "Fehlerwert" SG_ 2264486929 TLT_RespProtocolType_Kamera 7;
BA_ "GenSigSendType" SG_ 2264486929 TLT_RespSequenceID_Kamera 0;
BA_ "GenSigStartValue" SG_ 2264486929 TLT_RespSequenceID_Kamera 65534;
BA_ "GenSigSwitchedByIgnition" SG_ 2264486929 TLT_RespSequenceID_Kamera 0;
BA_ "Fehlerwert" SG_ 2264486929 TLT_RespSequenceID_Kamera 65535;
BA_ "GenSigSendType" SG_ 2264486929 TLT_RespSlaveID_Kamera 0;
BA_ "GenSigStartValue" SG_ 2264486929 TLT_RespSlaveID_Kamera 254;
BA_ "GenSigSwitchedByIgnition" SG_ 2264486929 TLT_RespSlaveID_Kamera 0;
BA_ "Fehlerwert" SG_ 2264486929 TLT_RespSlaveID_Kamera 255;
BA_ "GenSigSendType" SG_ 2264486933 TLT_LapCounter_NR_01 0;
BA_ "GenSigStartValue" SG_ 2264486933 TLT_LapCounter_NR_01 16382;
BA_ "GenSigSwitchedByIgnition" SG_ 2264486933 TLT_LapCounter_NR_01 0;
BA_ "Fehlerwert" SG_ 2264486933 TLT_LapCounter_NR_01 16383;
BA_ "GenSigSendType" SG_ 2264486933 TLT_ReqIngressTimestampNs_NR_01 0;
BA_ "GenSigSwitchedByIgnition" SG_ 2264486933 TLT_ReqIngressTimestampNs_NR_01 0;
BA_ "GenSigSendType" SG_ 2264486933 TLT_ReqIngressTimestampS_NR_01 0;
BA_ "GenSigSwitchedByIgnition" SG_ 2264486933 TLT_ReqIngressTimestampS_NR_01 0;
BA_ "GenSigSendType" SG_ 2264486933 TLT_Resp_NR_01_BZ 0;
BA_ "GenSigFuncType" SG_ 2264486933 TLT_Resp_NR_01_BZ 1;
BA_ "GenSigSendType" SG_ 2264486933 TLT_Resp_NR_01_CRC 0;
BA_ "GenSigFuncType" SG_ 2264486933 TLT_Resp_NR_01_CRC 2;
BA_ "GenSigSendType" SG_ 2264486933 TLT_RespEgressTimestampNs_NR_01 0;
BA_ "GenSigSwitchedByIgnition" SG_ 2264486933 TLT_RespEgressTimestampNs_NR_01 0;
BA_ "GenSigSendType" SG_ 2264486933 TLT_RespEgressTimestampS_NR_01 0;
BA_ "GenSigSwitchedByIgnition" SG_ 2264486933 TLT_RespEgressTimestampS_NR_01 0;
BA_ "GenSigSendType" SG_ 2264486933 TLT_RespMsgType_NR_01 0;
BA_ "GenSigSwitchedByIgnition" SG_ 2264486933 TLT_RespMsgType_NR_01 0;
BA_ "Fehlerwert" SG_ 2264486933 TLT_RespMsgType_NR_01 7;
BA_ "GenSigSendType" SG_ 2264486933 TLT_RespProtocolType_NR_01 0;
BA_ "GenSigSwitchedByIgnition" SG_ 2264486933 TLT_RespProtocolType_NR_01 0;
BA_ "Fehlerwert" SG_ 2264486933 TLT_RespProtocolType_NR_01 7;
BA_ "GenSigSendType" SG_ 2264486933 TLT_RespSequenceID_NR_01 0;
BA_ "GenSigStartValue" SG_ 2264486933 TLT_RespSequenceID_NR_01 65534;
BA_ "GenSigSwitchedByIgnition" SG_ 2264486933 TLT_RespSequenceID_NR_01 0;
BA_ "Fehlerwert" SG_ 2264486933 TLT_RespSequenceID_NR_01 65535;
BA_ "GenSigSendType" SG_ 2264486933 TLT_RespSlaveID_NR_01 0;
BA_ "GenSigStartValue" SG_ 2264486933 TLT_RespSlaveID_NR_01 254;
BA_ "GenSigSwitchedByIgnition" SG_ 2264486933 TLT_RespSlaveID_NR_01 0;
BA_ "Fehlerwert" SG_ 2264486933 TLT_RespSlaveID_NR_01 255;
BA_ "GenSigSendType" SG_ 2264486935 TLT_LapCounter_NR_02 0;
BA_ "GenSigStartValue" SG_ 2264486935 TLT_LapCounter_NR_02 16382;
BA_ "GenSigSwitchedByIgnition" SG_ 2264486935 TLT_LapCounter_NR_02 0;
BA_ "Fehlerwert" SG_ 2264486935 TLT_LapCounter_NR_02 16383;
BA_ "GenSigSendType" SG_ 2264486935 TLT_ReqIngressTimestampNs_NR_02 0;
BA_ "GenSigSwitchedByIgnition" SG_ 2264486935 TLT_ReqIngressTimestampNs_NR_02 0;
BA_ "GenSigSendType" SG_ 2264486935 TLT_ReqIngressTimestampS_NR_02 0;
BA_ "GenSigSwitchedByIgnition" SG_ 2264486935 TLT_ReqIngressTimestampS_NR_02 0;
BA_ "GenSigSendType" SG_ 2264486935 TLT_Resp_NR_02_BZ 0;
BA_ "GenSigFuncType" SG_ 2264486935 TLT_Resp_NR_02_BZ 1;
BA_ "GenSigSendType" SG_ 2264486935 TLT_Resp_NR_02_CRC 0;
BA_ "GenSigFuncType" SG_ 2264486935 TLT_Resp_NR_02_CRC 2;
BA_ "GenSigSendType" SG_ 2264486935 TLT_RespEgressTimestampNs_NR_02 0;
BA_ "GenSigSwitchedByIgnition" SG_ 2264486935 TLT_RespEgressTimestampNs_NR_02 0;
BA_ "GenSigSendType" SG_ 2264486935 TLT_RespEgressTimestampS_NR_02 0;
BA_ "GenSigSwitchedByIgnition" SG_ 2264486935 TLT_RespEgressTimestampS_NR_02 0;
BA_ "GenSigSendType" SG_ 2264486935 TLT_RespMsgType_NR_02 0;
BA_ "GenSigSwitchedByIgnition" SG_ 2264486935 TLT_RespMsgType_NR_02 0;
BA_ "Fehlerwert" SG_ 2264486935 TLT_RespMsgType_NR_02 7;
BA_ "GenSigSendType" SG_ 2264486935 TLT_RespProtocolType_NR_02 0;
BA_ "GenSigSwitchedByIgnition" SG_ 2264486935 TLT_RespProtocolType_NR_02 0;
BA_ "Fehlerwert" SG_ 2264486935 TLT_RespProtocolType_NR_02 7;
BA_ "GenSigSendType" SG_ 2264486935 TLT_RespSequenceID_NR_02 0;
BA_ "GenSigStartValue" SG_ 2264486935 TLT_RespSequenceID_NR_02 65534;
BA_ "GenSigSwitchedByIgnition" SG_ 2264486935 TLT_RespSequenceID_NR_02 0;
BA_ "Fehlerwert" SG_ 2264486935 TLT_RespSequenceID_NR_02 65535;
BA_ "GenSigSendType" SG_ 2264486935 TLT_RespSlaveID_NR_02 0;
BA_ "GenSigStartValue" SG_ 2264486935 TLT_RespSlaveID_NR_02 254;
BA_ "GenSigSwitchedByIgnition" SG_ 2264486935 TLT_RespSlaveID_NR_02 0;
BA_ "Fehlerwert" SG_ 2264486935 TLT_RespSlaveID_NR_02 255;
BA_ "GenSigSendType" SG_ 1447 bCall_active 3;
BA_ "GenSigSwitchedByIgnition" SG_ 1447 bCall_active 0;
BA_ "GenSigSendType" SG_ 1447 eCall_Funktionsstatus 0;
BA_ "GenSigSwitchedByIgnition" SG_ 1447 eCall_Funktionsstatus 0;
BA_ "GenSigSendType" SG_ 1447 eCall_Funktionsstatus_02 0;
BA_ "GenSigStartValue" SG_ 1447 eCall_Funktionsstatus_02 7;
BA_ "GenSigSwitchedByIgnition" SG_ 1447 eCall_Funktionsstatus_02 0;
BA_ "GenSigSendType" SG_ 1447 FaceRec_Enroll_Challenge_Request 0;
BA_ "GenSigSwitchedByIgnition" SG_ 1447 FaceRec_Enroll_Challenge_Request 0;
BA_ "GenSigSendType" SG_ 1447 iCall_active 3;
BA_ "GenSigSwitchedByIgnition" SG_ 1447 iCall_active 0;
BA_ "GenSigSendType" SG_ 1447 MOD_Energie_Anf 0;
BA_ "GenSigSwitchedByIgnition" SG_ 1447 MOD_Energie_Anf 0;
BA_ "Fehlerwert" SG_ 1447 MOD_Energie_Anf 3;
BA_ "GenSigSendType" SG_ 1447 OCU_Privacymode_Locationdata 0;
BA_ "GenSigSwitchedByIgnition" SG_ 1447 OCU_Privacymode_Locationdata 0;
BA_ "GenSigSendType" SG_ 1447 OCU_Privacymode_Status 0;
BA_ "GenSigSwitchedByIgnition" SG_ 1447 OCU_Privacymode_Status 0;
BA_ "GenSigSendType" SG_ 1447 TM_01_BZ 0;
BA_ "GenSigFuncType" SG_ 1447 TM_01_BZ 1;
BA_ "GenSigSwitchedByIgnition" SG_ 1447 TM_01_BZ 0;
BA_ "GenSigSendType" SG_ 1447 TM_Door_Lock 5;
BA_ "GenSigSwitchedByIgnition" SG_ 1447 TM_Door_Lock 0;
BA_ "GenSigSendType" SG_ 1447 TM_Door_Unlock 5;
BA_ "GenSigSwitchedByIgnition" SG_ 1447 TM_Door_Unlock 0;
BA_ "GenSigSendType" SG_ 1447 TM_Nur_Hupen 5;
BA_ "GenSigSwitchedByIgnition" SG_ 1447 TM_Nur_Hupen 0;
BA_ "GenSigSendType" SG_ 1447 TM_Panik_Alarm 5;
BA_ "GenSigSwitchedByIgnition" SG_ 1447 TM_Panik_Alarm 0;
BA_ "GenSigSendType" SG_ 1447 TM_Spiegel_Anklappen 5;
BA_ "GenSigSwitchedByIgnition" SG_ 1447 TM_Spiegel_Anklappen 0;
BA_ "GenSigSendType" SG_ 1447 TM_Warnblinken 5;
BA_ "GenSigSwitchedByIgnition" SG_ 1447 TM_Warnblinken 0;
BA_ "GenSigSendType" SG_ 1447 TM_ZV_Signatur 0;
BA_ "GenSigSwitchedByIgnition" SG_ 1447 TM_ZV_Signatur 0;
BA_ "GenSigSendType" SG_ 2463978729 TPA_PaCo_FunctionState 0;
BA_ "GenSigSwitchedByIgnition" SG_ 2463978729 TPA_PaCo_FunctionState 0;
BA_ "GenSigSendType" SG_ 2463978729 TPA_PaCo_MainState 0;
BA_ "GenSigSwitchedByIgnition" SG_ 2463978729 TPA_PaCo_MainState 0;
BA_ "GenSigSendType" SG_ 2463978729 TPA_PaCo_Number_ParkingManeuvers 0;
BA_ "GenSigSwitchedByIgnition" SG_ 2463978729 TPA_PaCo_Number_ParkingManeuvers 0;
BA_ "GenSigSendType" SG_ 2463978729 TPA_PaCo_Parking_lot_available 0;
BA_ "GenSigSwitchedByIgnition" SG_ 2463978729 TPA_PaCo_Parking_lot_available 0;
BA_ "GenSigSendType" SG_ 2463978729 TPA_PaCo_Parking_lot_selected 0;
BA_ "GenSigSwitchedByIgnition" SG_ 2463978729 TPA_PaCo_Parking_lot_selected 0;
BA_ "GenSigSendType" SG_ 2463978729 TPA_PaCo_Parkout_Training 0;
BA_ "GenSigSwitchedByIgnition" SG_ 2463978729 TPA_PaCo_Parkout_Training 0;
BA_ "GenSigSendType" SG_ 2463978729 TPA_PaCo_Preselection_State 0;
BA_ "GenSigSwitchedByIgnition" SG_ 2463978729 TPA_PaCo_Preselection_State 0;
BA_ "GenSigSendType" SG_ 2463978729 TPA_PaCo_SavingAvailable 0;
BA_ "GenSigSwitchedByIgnition" SG_ 2463978729 TPA_PaCo_SavingAvailable 0;
BA_ "GenSigSendType" SG_ 2463978788 TPA_Abbruch 0;
BA_ "GenSigSwitchedByIgnition" SG_ 2463978788 TPA_Abbruch 0;
BA_ "GenSigSendType" SG_ 2463978788 TPA_Fortschrittsanzeige 0;
BA_ "GenSigStartValue" SG_ 2463978788 TPA_Fortschrittsanzeige 126;
BA_ "GenSigSwitchedByIgnition" SG_ 2463978788 TPA_Fortschrittsanzeige 0;
BA_ "GenSigSendType" SG_ 2463978788 TPA_FzgAusrichtung 0;
BA_ "GenSigStartValue" SG_ 2463978788 TPA_FzgAusrichtung 510;
BA_ "GenSigSwitchedByIgnition" SG_ 2463978788 TPA_FzgAusrichtung 0;
BA_ "GenSigSendType" SG_ 2463978788 TPA_FzgPositionX 0;
BA_ "GenSigStartValue" SG_ 2463978788 TPA_FzgPositionX 8190;
BA_ "GenSigSwitchedByIgnition" SG_ 2463978788 TPA_FzgPositionX 0;
BA_ "GenSigSendType" SG_ 2463978788 TPA_FzgPositionY 0;
BA_ "GenSigStartValue" SG_ 2463978788 TPA_FzgPositionY 8190;
BA_ "GenSigSwitchedByIgnition" SG_ 2463978788 TPA_FzgPositionY 0;
BA_ "GenSigSendType" SG_ 2463978788 TPA_Remote_aktivierbar 0;
BA_ "GenSigStartValue" SG_ 2463978788 TPA_Remote_aktivierbar 1;
BA_ "GenSigSwitchedByIgnition" SG_ 2463978788 TPA_Remote_aktivierbar 0;
BA_ "GenSigSendType" SG_ 2463978788 TPA_Remote_verfuegbar 0;
BA_ "GenSigStartValue" SG_ 2463978788 TPA_Remote_verfuegbar 1;
BA_ "GenSigSwitchedByIgnition" SG_ 2463978788 TPA_Remote_verfuegbar 0;
BA_ "GenSigSendType" SG_ 2463978788 TPA_Status 3;
BA_ "GenSigStartValue" SG_ 2463978788 TPA_Status 1;
BA_ "GenSigSwitchedByIgnition" SG_ 2463978788 TPA_Status 0;
BA_ "GenSigSendType" SG_ 2463978788 TPA_Traj_P10_dX 0;
BA_ "GenSigStartValue" SG_ 2463978788 TPA_Traj_P10_dX 254;
BA_ "GenSigSwitchedByIgnition" SG_ 2463978788 TPA_Traj_P10_dX 0;
BA_ "GenSigSendType" SG_ 2463978788 TPA_Traj_P10_dY 0;
BA_ "GenSigStartValue" SG_ 2463978788 TPA_Traj_P10_dY 254;
BA_ "GenSigSwitchedByIgnition" SG_ 2463978788 TPA_Traj_P10_dY 0;
BA_ "GenSigSendType" SG_ 2463978788 TPA_Traj_P10_Tangentenwinkel 0;
BA_ "GenSigStartValue" SG_ 2463978788 TPA_Traj_P10_Tangentenwinkel 126;
BA_ "GenSigSwitchedByIgnition" SG_ 2463978788 TPA_Traj_P10_Tangentenwinkel 0;
BA_ "GenSigSendType" SG_ 2463978788 TPA_Traj_P10_Zugrichtung 0;
BA_ "GenSigSwitchedByIgnition" SG_ 2463978788 TPA_Traj_P10_Zugrichtung 0;
BA_ "GenSigSendType" SG_ 2463978788 TPA_Traj_P11_dX 0;
BA_ "GenSigStartValue" SG_ 2463978788 TPA_Traj_P11_dX 254;
BA_ "GenSigSwitchedByIgnition" SG_ 2463978788 TPA_Traj_P11_dX 0;
BA_ "GenSigSendType" SG_ 2463978788 TPA_Traj_P11_dY 0;
BA_ "GenSigStartValue" SG_ 2463978788 TPA_Traj_P11_dY 254;
BA_ "GenSigSwitchedByIgnition" SG_ 2463978788 TPA_Traj_P11_dY 0;
BA_ "GenSigSendType" SG_ 2463978788 TPA_Traj_P11_Tangentenwinkel 0;
BA_ "GenSigStartValue" SG_ 2463978788 TPA_Traj_P11_Tangentenwinkel 126;
BA_ "GenSigSwitchedByIgnition" SG_ 2463978788 TPA_Traj_P11_Tangentenwinkel 0;
BA_ "GenSigSendType" SG_ 2463978788 TPA_Traj_P11_Zugrichtung 0;
BA_ "GenSigSwitchedByIgnition" SG_ 2463978788 TPA_Traj_P11_Zugrichtung 0;
BA_ "GenSigSendType" SG_ 2463978788 TPA_Traj_P12_dX 0;
BA_ "GenSigStartValue" SG_ 2463978788 TPA_Traj_P12_dX 254;
BA_ "GenSigSwitchedByIgnition" SG_ 2463978788 TPA_Traj_P12_dX 0;
BA_ "GenSigSendType" SG_ 2463978788 TPA_Traj_P12_dY 0;
BA_ "GenSigStartValue" SG_ 2463978788 TPA_Traj_P12_dY 254;
BA_ "GenSigSwitchedByIgnition" SG_ 2463978788 TPA_Traj_P12_dY 0;
BA_ "GenSigSendType" SG_ 2463978788 TPA_Traj_P12_Tangentenwinkel 0;
BA_ "GenSigStartValue" SG_ 2463978788 TPA_Traj_P12_Tangentenwinkel 126;
BA_ "GenSigSwitchedByIgnition" SG_ 2463978788 TPA_Traj_P12_Tangentenwinkel 0;
BA_ "GenSigSendType" SG_ 2463978788 TPA_Traj_P12_Zugrichtung 0;
BA_ "GenSigSwitchedByIgnition" SG_ 2463978788 TPA_Traj_P12_Zugrichtung 0;
BA_ "GenSigSendType" SG_ 2463978788 TPA_Traj_P1_Kruemmung_02 0;
BA_ "GenSigSwitchedByIgnition" SG_ 2463978788 TPA_Traj_P1_Kruemmung_02 0;
BA_ "GenSigSendType" SG_ 2463978788 TPA_Traj_P1_Kruemmung_VZ 0;
BA_ "GenSigSwitchedByIgnition" SG_ 2463978788 TPA_Traj_P1_Kruemmung_VZ 0;
BA_ "GenSigSendType" SG_ 2463978788 TPA_Traj_P1_Tangentenwinkel 0;
BA_ "GenSigStartValue" SG_ 2463978788 TPA_Traj_P1_Tangentenwinkel 126;
BA_ "GenSigSwitchedByIgnition" SG_ 2463978788 TPA_Traj_P1_Tangentenwinkel 0;
BA_ "GenSigSendType" SG_ 2463978788 TPA_Traj_P1_X 0;
BA_ "GenSigStartValue" SG_ 2463978788 TPA_Traj_P1_X 8190;
BA_ "GenSigSwitchedByIgnition" SG_ 2463978788 TPA_Traj_P1_X 0;
BA_ "GenSigSendType" SG_ 2463978788 TPA_Traj_P1_Y 0;
BA_ "GenSigStartValue" SG_ 2463978788 TPA_Traj_P1_Y 8190;
BA_ "GenSigSwitchedByIgnition" SG_ 2463978788 TPA_Traj_P1_Y 0;
BA_ "GenSigSendType" SG_ 2463978788 TPA_Traj_P1_Zugrichtung 0;
BA_ "GenSigSwitchedByIgnition" SG_ 2463978788 TPA_Traj_P1_Zugrichtung 0;
BA_ "GenSigSendType" SG_ 2463978788 TPA_Traj_P2_dX 0;
BA_ "GenSigStartValue" SG_ 2463978788 TPA_Traj_P2_dX 254;
BA_ "GenSigSwitchedByIgnition" SG_ 2463978788 TPA_Traj_P2_dX 0;
BA_ "GenSigSendType" SG_ 2463978788 TPA_Traj_P2_dY 0;
BA_ "GenSigStartValue" SG_ 2463978788 TPA_Traj_P2_dY 254;
BA_ "GenSigSwitchedByIgnition" SG_ 2463978788 TPA_Traj_P2_dY 0;
BA_ "GenSigSendType" SG_ 2463978788 TPA_Traj_P2_Kruemmung_02 0;
BA_ "GenSigSwitchedByIgnition" SG_ 2463978788 TPA_Traj_P2_Kruemmung_02 0;
BA_ "GenSigSendType" SG_ 2463978788 TPA_Traj_P2_Kruemmung_VZ 0;
BA_ "NWM-WakeupAllowed" SG_ 2463978788 TPA_Traj_P2_Kruemmung_VZ 1;
BA_ "GenSigSwitchedByIgnition" SG_ 2463978788 TPA_Traj_P2_Kruemmung_VZ 0;
BA_ "GenSigSendType" SG_ 2463978788 TPA_Traj_P2_Tangentenwinkel 0;
BA_ "GenSigStartValue" SG_ 2463978788 TPA_Traj_P2_Tangentenwinkel 126;
BA_ "GenSigSwitchedByIgnition" SG_ 2463978788 TPA_Traj_P2_Tangentenwinkel 0;
BA_ "GenSigSendType" SG_ 2463978788 TPA_Traj_P2_Zugrichtung 0;
BA_ "GenSigSwitchedByIgnition" SG_ 2463978788 TPA_Traj_P2_Zugrichtung 0;
BA_ "GenSigSendType" SG_ 2463978788 TPA_Traj_P3_dX 0;
BA_ "GenSigStartValue" SG_ 2463978788 TPA_Traj_P3_dX 254;
BA_ "GenSigSwitchedByIgnition" SG_ 2463978788 TPA_Traj_P3_dX 0;
BA_ "GenSigSendType" SG_ 2463978788 TPA_Traj_P3_dY 0;
BA_ "GenSigStartValue" SG_ 2463978788 TPA_Traj_P3_dY 254;
BA_ "GenSigSwitchedByIgnition" SG_ 2463978788 TPA_Traj_P3_dY 0;
BA_ "GenSigSendType" SG_ 2463978788 TPA_Traj_P3_Kruemmung_02 0;
BA_ "GenSigSwitchedByIgnition" SG_ 2463978788 TPA_Traj_P3_Kruemmung_02 0;
BA_ "GenSigSendType" SG_ 2463978788 TPA_Traj_P3_Kruemmung_VZ 0;
BA_ "GenSigSwitchedByIgnition" SG_ 2463978788 TPA_Traj_P3_Kruemmung_VZ 0;
BA_ "GenSigSendType" SG_ 2463978788 TPA_Traj_P3_Tangentenwinkel 0;
BA_ "GenSigStartValue" SG_ 2463978788 TPA_Traj_P3_Tangentenwinkel 126;
BA_ "GenSigSwitchedByIgnition" SG_ 2463978788 TPA_Traj_P3_Tangentenwinkel 0;
BA_ "GenSigSendType" SG_ 2463978788 TPA_Traj_P3_Zugrichtung 0;
BA_ "GenSigSwitchedByIgnition" SG_ 2463978788 TPA_Traj_P3_Zugrichtung 0;
BA_ "GenSigSendType" SG_ 2463978788 TPA_Traj_P4_dX 0;
BA_ "GenSigStartValue" SG_ 2463978788 TPA_Traj_P4_dX 254;
BA_ "GenSigSwitchedByIgnition" SG_ 2463978788 TPA_Traj_P4_dX 0;
BA_ "GenSigSendType" SG_ 2463978788 TPA_Traj_P4_dY 0;
BA_ "GenSigStartValue" SG_ 2463978788 TPA_Traj_P4_dY 254;
BA_ "GenSigSwitchedByIgnition" SG_ 2463978788 TPA_Traj_P4_dY 0;
BA_ "GenSigSendType" SG_ 2463978788 TPA_Traj_P4_Kruemmung_02 0;
BA_ "GenSigSwitchedByIgnition" SG_ 2463978788 TPA_Traj_P4_Kruemmung_02 0;
BA_ "GenSigSendType" SG_ 2463978788 TPA_Traj_P4_Kruemmung_VZ 0;
BA_ "GenSigSwitchedByIgnition" SG_ 2463978788 TPA_Traj_P4_Kruemmung_VZ 0;
BA_ "GenSigSendType" SG_ 2463978788 TPA_Traj_P4_Tangentenwinkel 0;
BA_ "GenSigStartValue" SG_ 2463978788 TPA_Traj_P4_Tangentenwinkel 126;
BA_ "GenSigSwitchedByIgnition" SG_ 2463978788 TPA_Traj_P4_Tangentenwinkel 0;
BA_ "GenSigSendType" SG_ 2463978788 TPA_Traj_P4_Zugrichtung 0;
BA_ "GenSigSwitchedByIgnition" SG_ 2463978788 TPA_Traj_P4_Zugrichtung 0;
BA_ "GenSigSendType" SG_ 2463978788 TPA_Traj_P5_dX 0;
BA_ "GenSigStartValue" SG_ 2463978788 TPA_Traj_P5_dX 254;
BA_ "GenSigSwitchedByIgnition" SG_ 2463978788 TPA_Traj_P5_dX 0;
BA_ "GenSigSendType" SG_ 2463978788 TPA_Traj_P5_dY 0;
BA_ "GenSigStartValue" SG_ 2463978788 TPA_Traj_P5_dY 254;
BA_ "GenSigSwitchedByIgnition" SG_ 2463978788 TPA_Traj_P5_dY 0;
BA_ "GenSigSendType" SG_ 2463978788 TPA_Traj_P5_Kruemmung_02 0;
BA_ "GenSigSwitchedByIgnition" SG_ 2463978788 TPA_Traj_P5_Kruemmung_02 0;
BA_ "GenSigSendType" SG_ 2463978788 TPA_Traj_P5_Kruemmung_VZ 0;
BA_ "GenSigSwitchedByIgnition" SG_ 2463978788 TPA_Traj_P5_Kruemmung_VZ 0;
BA_ "GenSigSendType" SG_ 2463978788 TPA_Traj_P5_Tangentenwinkel 0;
BA_ "GenSigStartValue" SG_ 2463978788 TPA_Traj_P5_Tangentenwinkel 126;
BA_ "GenSigSwitchedByIgnition" SG_ 2463978788 TPA_Traj_P5_Tangentenwinkel 0;
BA_ "GenSigSendType" SG_ 2463978788 TPA_Traj_P5_Zugrichtung 0;
BA_ "GenSigSwitchedByIgnition" SG_ 2463978788 TPA_Traj_P5_Zugrichtung 0;
BA_ "GenSigSendType" SG_ 2463978788 TPA_Traj_P6_dX 0;
BA_ "GenSigStartValue" SG_ 2463978788 TPA_Traj_P6_dX 254;
BA_ "GenSigSwitchedByIgnition" SG_ 2463978788 TPA_Traj_P6_dX 0;
BA_ "GenSigSendType" SG_ 2463978788 TPA_Traj_P6_dY 0;
BA_ "GenSigStartValue" SG_ 2463978788 TPA_Traj_P6_dY 254;
BA_ "GenSigSwitchedByIgnition" SG_ 2463978788 TPA_Traj_P6_dY 0;
BA_ "GenSigSendType" SG_ 2463978788 TPA_Traj_P6_Tangentenwinkel 0;
BA_ "GenSigStartValue" SG_ 2463978788 TPA_Traj_P6_Tangentenwinkel 126;
BA_ "GenSigSwitchedByIgnition" SG_ 2463978788 TPA_Traj_P6_Tangentenwinkel 0;
BA_ "GenSigSendType" SG_ 2463978788 TPA_Traj_P6_Zugrichtung 0;
BA_ "GenSigSwitchedByIgnition" SG_ 2463978788 TPA_Traj_P6_Zugrichtung 0;
BA_ "GenSigSendType" SG_ 2463978788 TPA_Traj_P7_dX 0;
BA_ "GenSigStartValue" SG_ 2463978788 TPA_Traj_P7_dX 254;
BA_ "GenSigSwitchedByIgnition" SG_ 2463978788 TPA_Traj_P7_dX 0;
BA_ "GenSigSendType" SG_ 2463978788 TPA_Traj_P7_dY 0;
BA_ "GenSigStartValue" SG_ 2463978788 TPA_Traj_P7_dY 254;
BA_ "GenSigSwitchedByIgnition" SG_ 2463978788 TPA_Traj_P7_dY 0;
BA_ "GenSigSendType" SG_ 2463978788 TPA_Traj_P7_Tangentenwinkel 0;
BA_ "GenSigStartValue" SG_ 2463978788 TPA_Traj_P7_Tangentenwinkel 126;
BA_ "GenSigSwitchedByIgnition" SG_ 2463978788 TPA_Traj_P7_Tangentenwinkel 0;
BA_ "GenSigSendType" SG_ 2463978788 TPA_Traj_P7_Zugrichtung 0;
BA_ "GenSigSwitchedByIgnition" SG_ 2463978788 TPA_Traj_P7_Zugrichtung 0;
BA_ "GenSigSendType" SG_ 2463978788 TPA_Traj_P8_dX 0;
BA_ "GenSigStartValue" SG_ 2463978788 TPA_Traj_P8_dX 254;
BA_ "GenSigSwitchedByIgnition" SG_ 2463978788 TPA_Traj_P8_dX 0;
BA_ "GenSigSendType" SG_ 2463978788 TPA_Traj_P8_dY 0;
BA_ "GenSigStartValue" SG_ 2463978788 TPA_Traj_P8_dY 254;
BA_ "GenSigSwitchedByIgnition" SG_ 2463978788 TPA_Traj_P8_dY 0;
BA_ "GenSigSendType" SG_ 2463978788 TPA_Traj_P8_Tangentenwinkel 0;
BA_ "GenSigStartValue" SG_ 2463978788 TPA_Traj_P8_Tangentenwinkel 126;
BA_ "GenSigSwitchedByIgnition" SG_ 2463978788 TPA_Traj_P8_Tangentenwinkel 0;
BA_ "GenSigSendType" SG_ 2463978788 TPA_Traj_P8_Zugrichtung 0;
BA_ "GenSigSwitchedByIgnition" SG_ 2463978788 TPA_Traj_P8_Zugrichtung 0;
BA_ "GenSigSendType" SG_ 2463978788 TPA_Traj_P9_dX 0;
BA_ "GenSigStartValue" SG_ 2463978788 TPA_Traj_P9_dX 254;
BA_ "GenSigSwitchedByIgnition" SG_ 2463978788 TPA_Traj_P9_dX 0;
BA_ "GenSigSendType" SG_ 2463978788 TPA_Traj_P9_dY 0;
BA_ "GenSigStartValue" SG_ 2463978788 TPA_Traj_P9_dY 254;
BA_ "GenSigSwitchedByIgnition" SG_ 2463978788 TPA_Traj_P9_dY 0;
BA_ "GenSigSendType" SG_ 2463978788 TPA_Traj_P9_Tangentenwinkel 0;
BA_ "GenSigStartValue" SG_ 2463978788 TPA_Traj_P9_Tangentenwinkel 126;
BA_ "GenSigSwitchedByIgnition" SG_ 2463978788 TPA_Traj_P9_Tangentenwinkel 0;
BA_ "GenSigSendType" SG_ 2463978788 TPA_Traj_P9_Zugrichtung 0;
BA_ "GenSigSwitchedByIgnition" SG_ 2463978788 TPA_Traj_P9_Zugrichtung 0;
BA_ "GenSigSendType" SG_ 2463978788 TPA_Traj_Update 3;
BA_ "GenSigSwitchedByIgnition" SG_ 2463978788 TPA_Traj_Update 0;
BA_ "GenSigSendType" SG_ 2463978788 TPA_Unsicherheit_PosX 0;
BA_ "GenSigSwitchedByIgnition" SG_ 2463978788 TPA_Unsicherheit_PosX 0;
BA_ "GenSigSendType" SG_ 2463978788 TPA_Unsicherheit_PosY 0;
BA_ "GenSigSwitchedByIgnition" SG_ 2463978788 TPA_Unsicherheit_PosY 0;
BA_ "GenSigSendType" SG_ 2463978788 TPA_Verfuegbarkeit 0;
BA_ "GenSigSwitchedByIgnition" SG_ 2463978788 TPA_Verfuegbarkeit 0;
BA_ "GenSigSendType" SG_ 2463978788 TPA_Zeitstempel 0;
BA_ "GenSigStartValue" SG_ 2463978788 TPA_Zeitstempel 8191;
BA_ "GenSigSwitchedByIgnition" SG_ 2463978788 TPA_Zeitstempel 0;
BA_ "GenSigSendType" SG_ 2589283583 TPA_Traj_P10_Kruemmung_02 0;
BA_ "GenSigSwitchedByIgnition" SG_ 2589283583 TPA_Traj_P10_Kruemmung_02 0;
BA_ "GenSigSendType" SG_ 2589283583 TPA_Traj_P10_Kruemmung_VZ 0;
BA_ "GenSigSwitchedByIgnition" SG_ 2589283583 TPA_Traj_P10_Kruemmung_VZ 0;
BA_ "GenSigSendType" SG_ 2589283583 TPA_Traj_P11_Kruemmung_02 0;
BA_ "GenSigSwitchedByIgnition" SG_ 2589283583 TPA_Traj_P11_Kruemmung_02 0;
BA_ "GenSigSendType" SG_ 2589283583 TPA_Traj_P11_Kruemmung_VZ 0;
BA_ "GenSigSwitchedByIgnition" SG_ 2589283583 TPA_Traj_P11_Kruemmung_VZ 0;
BA_ "GenSigSendType" SG_ 2589283583 TPA_Traj_P12_Kruemmung_02 0;
BA_ "GenSigSwitchedByIgnition" SG_ 2589283583 TPA_Traj_P12_Kruemmung_02 0;
BA_ "GenSigSendType" SG_ 2589283583 TPA_Traj_P12_Kruemmung_VZ 0;
BA_ "GenSigSwitchedByIgnition" SG_ 2589283583 TPA_Traj_P12_Kruemmung_VZ 0;
BA_ "GenSigSendType" SG_ 2589283583 TPA_Traj_P13_Kruemmung_02 0;
BA_ "GenSigSwitchedByIgnition" SG_ 2589283583 TPA_Traj_P13_Kruemmung_02 0;
BA_ "GenSigSendType" SG_ 2589283583 TPA_Traj_P13_Kruemmung_VZ 0;
BA_ "GenSigSwitchedByIgnition" SG_ 2589283583 TPA_Traj_P13_Kruemmung_VZ 0;
BA_ "GenSigSendType" SG_ 2589283583 TPA_Traj_P14_Kruemmung_02 0;
BA_ "GenSigSwitchedByIgnition" SG_ 2589283583 TPA_Traj_P14_Kruemmung_02 0;
BA_ "GenSigSendType" SG_ 2589283583 TPA_Traj_P14_Kruemmung_VZ 0;
BA_ "GenSigSwitchedByIgnition" SG_ 2589283583 TPA_Traj_P14_Kruemmung_VZ 0;
BA_ "GenSigSendType" SG_ 2589283583 TPA_Traj_P15_Kruemmung_02 0;
BA_ "GenSigSwitchedByIgnition" SG_ 2589283583 TPA_Traj_P15_Kruemmung_02 0;
BA_ "GenSigSendType" SG_ 2589283583 TPA_Traj_P15_Kruemmung_VZ 0;
BA_ "GenSigSwitchedByIgnition" SG_ 2589283583 TPA_Traj_P15_Kruemmung_VZ 0;
BA_ "GenSigSendType" SG_ 2589283583 TPA_Traj_P6_Kruemmung_02 0;
BA_ "GenSigSwitchedByIgnition" SG_ 2589283583 TPA_Traj_P6_Kruemmung_02 0;
BA_ "GenSigSendType" SG_ 2589283583 TPA_Traj_P6_Kruemmung_VZ 0;
BA_ "GenSigSwitchedByIgnition" SG_ 2589283583 TPA_Traj_P6_Kruemmung_VZ 0;
BA_ "GenSigSendType" SG_ 2589283583 TPA_Traj_P7_Kruemmung_02 0;
BA_ "GenSigSwitchedByIgnition" SG_ 2589283583 TPA_Traj_P7_Kruemmung_02 0;
BA_ "GenSigSendType" SG_ 2589283583 TPA_Traj_P7_Kruemmung_VZ 0;
BA_ "GenSigSwitchedByIgnition" SG_ 2589283583 TPA_Traj_P7_Kruemmung_VZ 0;
BA_ "GenSigSendType" SG_ 2589283583 TPA_Traj_P8_Kruemmung_02 0;
BA_ "GenSigSwitchedByIgnition" SG_ 2589283583 TPA_Traj_P8_Kruemmung_02 0;
BA_ "GenSigSendType" SG_ 2589283583 TPA_Traj_P8_Kruemmung_VZ 0;
BA_ "GenSigSwitchedByIgnition" SG_ 2589283583 TPA_Traj_P8_Kruemmung_VZ 0;
BA_ "GenSigSendType" SG_ 2589283583 TPA_Traj_P9_Kruemmung_02 0;
BA_ "GenSigSwitchedByIgnition" SG_ 2589283583 TPA_Traj_P9_Kruemmung_02 0;
BA_ "GenSigSendType" SG_ 2589283583 TPA_Traj_P9_Kruemmung_VZ 0;
BA_ "GenSigSwitchedByIgnition" SG_ 2589283583 TPA_Traj_P9_Kruemmung_VZ 0;
BA_ "GenSigSendType" SG_ 2589283583 TPA_Traj_Update_TS 3;
BA_ "GenSigSwitchedByIgnition" SG_ 2589283583 TPA_Traj_Update_TS 0;
BA_ "GenSigSendType" SG_ 2589283583 TPA_Zeitstempel_NSek 0;
BA_ "GenSigSendType" SG_ 2589283583 TPA_Zeitstempel_Sek 0;
BA_REL_ "GenSigTimeoutTime" BU_SG_REL_ FASFrontradar SG_ 980 BH_Blinker_li 5000;
BA_REL_ "GenSigTimeoutTime" BU_SG_REL_ FASFrontradar SG_ 980 BH_Blinker_re 5000;
BA_REL_ "GenSigTimeoutTime" BU_SG_REL_ FASFrontradar SG_ 980 BH_Blinker_Fehler 5000;
BA_REL_ "GenSigTimeoutTime" BU_SG_REL_ FASFrontradar SG_ 1413 SI_P_Mode_gueltig 5000;
BA_REL_ "GenSigTimeoutTime" BU_SG_REL_ FASFrontradar SG_ 1413 SI_NWDF 5000;
BA_REL_ "GenSigTimeoutTime" BU_SG_REL_ FASFrontradar SG_ 1413 SI_NWDF_gueltig 5000;
BA_REL_ "GenSigTimeoutTime" BU_SG_REL_ FASFrontradar SG_ 1413 SI_T_Schutz 5000;
BA_REL_ "GenSigTimeoutTime" BU_SG_REL_ FASFrontradar SG_ 1413 SI_P_Mode 5000;
BA_REL_ "GenSigTimeoutTime" BU_SG_REL_ FASFrontradar SG_ 619 TA_ACC_Sollstatus 1000;
BA_REL_ "GenSigTimeoutTime" BU_SG_REL_ FASFrontradar SG_ 619 TA_Status 1000;
BA_REL_ "GenSigTimeoutTime" BU_SG_REL_ FASFrontradar SG_ 619 TA_Spurwechsel 1000;
BA_REL_ "GenSigTimeoutTime" BU_SG_REL_ FASFrontradar SG_ 619 TA_Texte 1000;
BA_REL_ "GenSigTimeoutTime" BU_SG_REL_ FASFrontradar SG_ 619 TA_FoD_Status 1000;
BA_REL_ "GenSigTimeoutTime" BU_SG_REL_ FASFrontradar SG_ 619 TA_aktiv_HMI 1000;
BA_REL_ "GenSigTimeoutTime" BU_SG_REL_ FASFrontradar SG_ 619 TA_Fehler 1000;
BA_REL_ "GenSigTimeoutTime" BU_SG_REL_ FASFrontradar SG_ 619 TA_Ueberholhilfe 1000;
BA_REL_ "GenSigTimeoutTime" BU_SG_REL_ ICAS1_X_Gateway SG_ 619 TA_01_CRC 1000;
BA_REL_ "GenSigTimeoutTime" BU_SG_REL_ ICAS1_X_Gateway SG_ 619 TA_01_BZ 1000;
BA_REL_ "GenSigTimeoutTime" BU_SG_REL_ ICAS1_X_Gateway SG_ 619 TA_Status 1000;
BA_REL_ "GenSigTimeoutTime" BU_SG_REL_ ICAS1_X_Gateway SG_ 619 TA_Spurwechsel 1000;
BA_REL_ "GenSigTimeoutTime" BU_SG_REL_ ICAS1_X_Gateway SG_ 619 TA_Texte 1000;
BA_REL_ "GenSigTimeoutTime" BU_SG_REL_ ICAS1_X_Gateway SG_ 619 TA_Spurwechsel_Ready 1000;
BA_REL_ "GenSigTimeoutTime" BU_SG_REL_ ICAS1_X_Gateway SG_ 619 TA_Texte_02 1000;
BA_REL_ "GenSigTimeoutTime" BU_SG_REL_ ICAS1_X_Gateway SG_ 619 TA_Handsoff_LED 1000;
BA_REL_ "GenSigTimeoutTime" BU_SG_REL_ ICAS1_X_Gateway SG_ 619 TA_Fehler 1000;
BA_REL_ "GenSigTimeoutTime" BU_SG_REL_ ICAS1_X_Gateway SG_ 2264486930 TLT_ReqMsgType_ACC_01 5000;
BA_REL_ "GenSigTimeoutTime" BU_SG_REL_ ICAS1_X_Gateway SG_ 2264486930 TLT_ReqProtocolType_ACC_01 5000;
BA_REL_ "GenSigTimeoutTime" BU_SG_REL_ ICAS1_X_Gateway SG_ 2264486930 TLT_ReqSlaveID_ACC_01 5000;
BA_REL_ "GenSigTimeoutTime" BU_SG_REL_ ICAS1_X_Gateway SG_ 2264486930 TLT_ReqSequenceID_ACC_01 5000;
BA_REL_ "GenSigTimeoutTime" BU_SG_REL_ ICAS1_X_Gateway SG_ 2264486930 TLT_CurSlaveTimestampS_ACC_01 5000;
BA_REL_ "GenSigTimeoutTime" BU_SG_REL_ ICAS1_X_Gateway SG_ 2264486930 TLT_CurSlaveTimestampNs_ACC_01 5000;
BA_REL_ "GenSigTimeoutTime" BU_SG_REL_ ICAS1_X_Gateway SG_ 2264486930 TLT_CurRTTS_ACC_01 5000;
BA_REL_ "GenSigTimeoutTime" BU_SG_REL_ ICAS1_X_Gateway SG_ 2264486930 TLT_CurRTTNs_ACC_01 5000;
BA_REL_ "GenSigTimeoutTime" BU_SG_REL_ ICAS1_X_Gateway SG_ 2264486930 TLT_ErrorMaxNs_ACC_01 5000;
BA_REL_ "GenSigTimeoutTime" BU_SG_REL_ ICAS1_X_Gateway SG_ 2264486930 TLT_ErrorMinNs_ACC_01 5000;
BA_REL_ "GenSigTimeoutTime" BU_SG_REL_ ICAS1_X_Gateway SG_ 2264486928 TLT_ReqMsgType_Kamera 5000;
BA_REL_ "GenSigTimeoutTime" BU_SG_REL_ ICAS1_X_Gateway SG_ 2264486928 TLT_ReqProtocolType_Kamera 5000;
BA_REL_ "GenSigTimeoutTime" BU_SG_REL_ ICAS1_X_Gateway SG_ 2264486928 TLT_ReqSlaveID_Kamera 5000;
BA_REL_ "GenSigTimeoutTime" BU_SG_REL_ ICAS1_X_Gateway SG_ 2264486928 TLT_ReqSequenceID_Kamera 5000;
BA_REL_ "GenSigTimeoutTime" BU_SG_REL_ ICAS1_X_Gateway SG_ 2264486928 TLT_CurSlaveTimestampS_Kamera 5000;
BA_REL_ "GenSigTimeoutTime" BU_SG_REL_ ICAS1_X_Gateway SG_ 2264486928 TLT_CurSlaveTimestampNs_Kamera 5000;
BA_REL_ "GenSigTimeoutTime" BU_SG_REL_ ICAS1_X_Gateway SG_ 2264486928 TLT_CurRTTS_Kamera 5000;
BA_REL_ "GenSigTimeoutTime" BU_SG_REL_ ICAS1_X_Gateway SG_ 2264486928 TLT_CurRTTNs_Kamera 5000;
BA_REL_ "GenSigTimeoutTime" BU_SG_REL_ ICAS1_X_Gateway SG_ 2264486928 TLT_ErrorMaxNs_Kamera 5000;
BA_REL_ "GenSigTimeoutTime" BU_SG_REL_ ICAS1_X_Gateway SG_ 2264486928 TLT_ErrorMinNs_Kamera 5000;
BA_REL_ "GenSigTimeoutTime" BU_SG_REL_ ICAS1_X_Gateway SG_ 2264486932 TLT_ReqMsgType_NR_01 5000;
BA_REL_ "GenSigTimeoutTime" BU_SG_REL_ ICAS1_X_Gateway SG_ 2264486932 TLT_ReqProtocolType_NR_01 5000;
BA_REL_ "GenSigTimeoutTime" BU_SG_REL_ ICAS1_X_Gateway SG_ 2264486932 TLT_ReqSlaveID_NR_01 5000;
BA_REL_ "GenSigTimeoutTime" BU_SG_REL_ ICAS1_X_Gateway SG_ 2264486932 TLT_ReqSequenceID_NR_01 5000;
BA_REL_ "GenSigTimeoutTime" BU_SG_REL_ ICAS1_X_Gateway SG_ 2264486932 TLT_CurSlaveTimestampS_NR_01 5000;
BA_REL_ "GenSigTimeoutTime" BU_SG_REL_ ICAS1_X_Gateway SG_ 2264486932 TLT_CurSlaveTimestampNs_NR_01 5000;
BA_REL_ "GenSigTimeoutTime" BU_SG_REL_ ICAS1_X_Gateway SG_ 2264486932 TLT_CurRTTS_NR_01 5000;
BA_REL_ "GenSigTimeoutTime" BU_SG_REL_ ICAS1_X_Gateway SG_ 2264486932 TLT_CurRTTNs_NR_01 5000;
BA_REL_ "GenSigTimeoutTime" BU_SG_REL_ ICAS1_X_Gateway SG_ 2264486932 TLT_ErrorMaxNs_NR_01 5000;
BA_REL_ "GenSigTimeoutTime" BU_SG_REL_ ICAS1_X_Gateway SG_ 2264486932 TLT_ErrorMinNs_NR_01 5000;
BA_REL_ "GenSigTimeoutTime" BU_SG_REL_ ICAS1_X_Gateway SG_ 2264486934 TLT_ReqMsgType_NR_02 5000;
BA_REL_ "GenSigTimeoutTime" BU_SG_REL_ ICAS1_X_Gateway SG_ 2264486934 TLT_ReqProtocolType_NR_02 5000;
BA_REL_ "GenSigTimeoutTime" BU_SG_REL_ ICAS1_X_Gateway SG_ 2264486934 TLT_ReqSlaveID_NR_02 5000;
BA_REL_ "GenSigTimeoutTime" BU_SG_REL_ ICAS1_X_Gateway SG_ 2264486934 TLT_ReqSequenceID_NR_02 5000;
BA_REL_ "GenSigTimeoutTime" BU_SG_REL_ ICAS1_X_Gateway SG_ 2264486934 TLT_CurSlaveTimestampS_NR_02 5000;
BA_REL_ "GenSigTimeoutTime" BU_SG_REL_ ICAS1_X_Gateway SG_ 2264486934 TLT_CurSlaveTimestampNs_NR_02 5000;
BA_REL_ "GenSigTimeoutTime" BU_SG_REL_ ICAS1_X_Gateway SG_ 2264486934 TLT_CurRTTS_NR_02 5000;
BA_REL_ "GenSigTimeoutTime" BU_SG_REL_ ICAS1_X_Gateway SG_ 2264486934 TLT_ErrorMaxNs_NR_02 5000;
BA_REL_ "GenSigTimeoutTime" BU_SG_REL_ ICAS1_X_Gateway SG_ 2264486934 TLT_ErrorMinNs_NR_02 5000;
BA_REL_ "GenSigTimeoutTime" BU_SG_REL_ ICAS1_X_Gateway SG_ 2463978729 TPA_PaCo_Parking_lot_selected 1000;
BA_REL_ "GenSigTimeoutTime" BU_SG_REL_ ICAS1_X_Gateway SG_ 2463978729 TPA_PaCo_MainState 1000;
BA_REL_ "GenSigTimeoutTime" BU_SG_REL_ ICAS1_X_Gateway SG_ 2463978729 TPA_PaCo_Parking_lot_available 1000;
BA_REL_ "GenSigTimeoutTime" BU_SG_REL_ ICAS1_X_Gateway SG_ 2463978729 TPA_PaCo_Preselection_State 1000;
BA_REL_ "GenSigTimeoutTime" BU_SG_REL_ ICAS1_X_Gateway SG_ 2463978729 TPA_PaCo_FunctionState 1000;
BA_REL_ "GenSigTimeoutTime" BU_SG_REL_ ICAS1_X_Gateway SG_ 2463978729 TPA_PaCo_Parkout_Training 1000;
BA_REL_ "GenSigTimeoutTime" BU_SG_REL_ ICAS1_X_Gateway SG_ 2463978729 TPA_PaCo_Number_ParkingManeuvers 1000;
BA_REL_ "GenSigTimeoutTime" BU_SG_REL_ ICAS1_X_Gateway SG_ 2463978729 TPA_PaCo_SavingAvailable 1000;
BA_REL_ "GenSigTimeoutTime" BU_SG_REL_ MFK SG_ 1440 RS_Wischergeschwindigkeit 2000;
BA_REL_ "GenSigTimeoutTime" BU_SG_REL_ MFK SG_ 2463978697 SAL_Aussenbeleuchtung_defekt 800;
BA_REL_ "GenSigTimeoutTime" BU_SG_REL_ MFK SG_ 980 BH_Blinker_li 5000;
BA_REL_ "GenSigTimeoutTime" BU_SG_REL_ MFK SG_ 980 BH_Blinker_re 5000;
BA_REL_ "GenSigTimeoutTime" BU_SG_REL_ MFK SG_ 980 BH_Fernlicht 5000;
BA_REL_ "GenSigTimeoutTime" BU_SG_REL_ MFK SG_ 980 FAS_Taster 5000;
BA_REL_ "GenSigTimeoutTime" BU_SG_REL_ MFK SG_ 980 FAS_Taster_Fehler 5000;
BA_REL_ "GenSigTimeoutTime" BU_SG_REL_ MFK SG_ 1413 SI_NWDF 5000;
BA_REL_ "GenSigTimeoutTime" BU_SG_REL_ MFK SG_ 1413 SI_NWDF_gueltig 5000;
BA_REL_ "GenSigTimeoutTime" BU_SG_REL_ MFK120 SG_ 1440 RS_Regenmenge 2000;
BA_REL_ "GenSigTimeoutTime" BU_SG_REL_ MFK120 SG_ 1440 RS_Wischergeschwindigkeit 2000;
BA_REL_ "GenSigTimeoutTime" BU_SG_REL_ MFK120 SG_ 980 BH_Blinker_li 5000;
BA_REL_ "GenSigTimeoutTime" BU_SG_REL_ MFK120 SG_ 980 BH_Blinker_re 5000;
BA_REL_ "GenSigTimeoutTime" BU_SG_REL_ MFK120 SG_ 2589283750 KBI_Aussen_Temp_gef 5000;
BA_REL_ "GenSigTimeoutTime" BU_SG_REL_ MFK120 SG_ 165 TS_CAN_Ma_Type 1000;
BA_REL_ "GenSigTimeoutTime" BU_SG_REL_ MFK120 SG_ 165 TS_CAN_Ma_CRC 1000;
BA_REL_ "GenSigTimeoutTime" BU_SG_REL_ MFK120 SG_ 165 TS_CAN_Ma_SequenceCounter 1000;
BA_REL_ "GenSigTimeoutTime" BU_SG_REL_ MFK120 SG_ 165 TS_CAN_Ma_TimeDomain 1000;
BA_REL_ "GenSigTimeoutTime" BU_SG_REL_ MFK120 SG_ 165 TS_CAN_Ma_OVS 1000;
BA_REL_ "GenSigTimeoutTime" BU_SG_REL_ MFK120 SG_ 165 TS_CAN_Ma_SGW 1000;
BA_REL_ "GenSigTimeoutTime" BU_SG_REL_ MFK120 SG_ 165 TS_CAN_Ma_SyncTimeSec 1000;
BA_REL_ "GenSigTimeoutTime" BU_SG_REL_ MFK120 SG_ 2264486929 TLT_RespMsgType_Kamera 5000;
BA_REL_ "GenSigTimeoutTime" BU_SG_REL_ MFK120 SG_ 2264486929 TLT_RespProtocolType_Kamera 5000;
BA_REL_ "GenSigTimeoutTime" BU_SG_REL_ MFK120 SG_ 2264486929 TLT_LapCounter_Kamera 5000;
BA_REL_ "GenSigTimeoutTime" BU_SG_REL_ MFK120 SG_ 2264486929 TLT_RespSequenceID_Kamera 5000;
BA_REL_ "GenSigTimeoutTime" BU_SG_REL_ MFK120 SG_ 2264486929 TLT_RespSlaveID_Kamera 5000;
BA_REL_ "GenSigTimeoutTime" BU_SG_REL_ MFK120 SG_ 2264486929 TLT_ReqIngressTimestampNs_Kamera 5000;
BA_REL_ "GenSigTimeoutTime" BU_SG_REL_ MFK120 SG_ 2264486929 TLT_ReqIngressTimestampS_Kamera 5000;
BA_REL_ "GenSigTimeoutTime" BU_SG_REL_ MFK120 SG_ 2264486929 TLT_RespEgressTimestampNs_Kamera 5000;
BA_REL_ "GenSigTimeoutTime" BU_SG_REL_ MFK120 SG_ 2264486929 TLT_RespEgressTimestampS_Kamera 5000;
BA_REL_ "GenSigTimeoutTime" BU_SG_REL_ MIK SG_ 2464155061 SOK_FR_Auth_NAD_Challenge 5000;
BA_REL_ "GenSigTimeoutTime" BU_SG_REL_ MIK SG_ 1413 SI_QRS_Mode 5000;
BA_REL_ "GenSigTimeoutTime" BU_SG_REL_ MIK SG_ 1413 SI_T_Mode 5000;
BA_REL_ "GenSigTimeoutTime" BU_SG_REL_ MIK SG_ 1413 SI_NWDF 5000;
BA_REL_ "GenSigTimeoutTime" BU_SG_REL_ MIK SG_ 1413 SI_NWDF_gueltig 5000;
BA_REL_ "GenSigTimeoutTime" BU_SG_REL_ MIK SG_ 1413 SI_T_Schutz 5000;
BA_REL_ "GenSigTimeoutTime" BU_SG_REL_ MIK SG_ 1413 SI_BUS_01 5000;
BA_REL_ "GenSigTimeoutTime" BU_SG_REL_ MIK SG_ 1413 SI_BUS_02 5000;
BA_REL_ "GenSigTimeoutTime" BU_SG_REL_ MIK SG_ 1447 FaceRec_Enroll_Challenge_Request 5000;
BA_REL_ "GenSigTimeoutTime" BU_SG_REL_ MRR2023 SG_ 980 BH_Blinker_li 5000;
BA_REL_ "GenSigTimeoutTime" BU_SG_REL_ MRR2023 SG_ 980 BH_Blinker_re 5000;
BA_REL_ "GenSigTimeoutTime" BU_SG_REL_ MRR2023 SG_ 980 BH_Blinker_Fehler 5000;
BA_REL_ "GenSigTimeoutTime" BU_SG_REL_ MRR2023 SG_ 619 TA_ACC_Sollstatus 1000;
BA_REL_ "GenSigTimeoutTime" BU_SG_REL_ MRR2023 SG_ 619 TA_Status 1000;
BA_REL_ "GenSigTimeoutTime" BU_SG_REL_ MRR2023 SG_ 619 TA_Spurwechsel 1000;
BA_REL_ "GenSigTimeoutTime" BU_SG_REL_ MRR2023 SG_ 619 TA_Texte 1000;
BA_REL_ "GenSigTimeoutTime" BU_SG_REL_ MRR2023 SG_ 619 TA_aktiv_HMI 1000;
BA_REL_ "GenSigTimeoutTime" BU_SG_REL_ MRR2023 SG_ 619 TA_Fehler 1000;
BA_REL_ "GenSigTimeoutTime" BU_SG_REL_ MRR2023 SG_ 619 TA_Ueberholhilfe 1000;
BA_REL_ "GenSigTimeoutTime" BU_SG_REL_ MRR2023 SG_ 165 TS_CAN_Ma_Type 1000;
BA_REL_ "GenSigTimeoutTime" BU_SG_REL_ MRR2023 SG_ 165 TS_CAN_Ma_CRC 1000;
BA_REL_ "GenSigTimeoutTime" BU_SG_REL_ MRR2023 SG_ 165 TS_CAN_Ma_SequenceCounter 1000;
BA_REL_ "GenSigTimeoutTime" BU_SG_REL_ MRR2023 SG_ 165 TS_CAN_Ma_TimeDomain 1000;
BA_REL_ "GenSigTimeoutTime" BU_SG_REL_ MRR2023 SG_ 165 TS_CAN_Ma_OVS 1000;
BA_REL_ "GenSigTimeoutTime" BU_SG_REL_ MRR2023 SG_ 165 TS_CAN_Ma_SGW 1000;
BA_REL_ "GenSigTimeoutTime" BU_SG_REL_ MRR2023 SG_ 165 TS_CAN_Ma_SyncTimeSec 1000;
BA_REL_ "GenSigTimeoutTime" BU_SG_REL_ MRR2023 SG_ 2264486931 TLT_Resp_ACC_01_CRC 5000;
BA_REL_ "GenSigTimeoutTime" BU_SG_REL_ MRR2023 SG_ 2264486931 TLT_Resp_ACC_01_BZ 5000;
BA_REL_ "GenSigTimeoutTime" BU_SG_REL_ MRR2023 SG_ 2264486931 TLT_RespMsgType_ACC_01 5000;
BA_REL_ "GenSigTimeoutTime" BU_SG_REL_ MRR2023 SG_ 2264486931 TLT_RespProtocolType_ACC_01 5000;
BA_REL_ "GenSigTimeoutTime" BU_SG_REL_ MRR2023 SG_ 2264486931 TLT_LapCounter_ACC_01 5000;
BA_REL_ "GenSigTimeoutTime" BU_SG_REL_ MRR2023 SG_ 2264486931 TLT_RespSequenceID_ACC_01 5000;
BA_REL_ "GenSigTimeoutTime" BU_SG_REL_ MRR2023 SG_ 2264486931 TLT_RespSlaveID_ACC_01 5000;
BA_REL_ "GenSigTimeoutTime" BU_SG_REL_ MRR2023 SG_ 2264486931 TLT_ReqIngressTimestampNs_ACC_01 5000;
BA_REL_ "GenSigTimeoutTime" BU_SG_REL_ MRR2023 SG_ 2264486931 TLT_ReqIngressTimestampS_ACC_01 5000;
BA_REL_ "GenSigTimeoutTime" BU_SG_REL_ MRR2023 SG_ 2264486931 TLT_RespEgressTimestampNs_ACC_01 5000;
BA_REL_ "GenSigTimeoutTime" BU_SG_REL_ MRR2023 SG_ 2264486931 TLT_RespEgressTimestampS_ACC_01 5000;
BA_REL_ "GenSigTimeoutTime" BU_SG_REL_ NR_1 SG_ 165 TS_CAN_Ma_Type 1000;
BA_REL_ "GenSigTimeoutTime" BU_SG_REL_ NR_1 SG_ 165 TS_CAN_Ma_CRC 1000;
BA_REL_ "GenSigTimeoutTime" BU_SG_REL_ NR_1 SG_ 165 TS_CAN_Ma_SequenceCounter 1000;
BA_REL_ "GenSigTimeoutTime" BU_SG_REL_ NR_1 SG_ 165 TS_CAN_Ma_TimeDomain 1000;
BA_REL_ "GenSigTimeoutTime" BU_SG_REL_ NR_1 SG_ 165 TS_CAN_Ma_OVS 1000;
BA_REL_ "GenSigTimeoutTime" BU_SG_REL_ NR_1 SG_ 165 TS_CAN_Ma_SGW 1000;
BA_REL_ "GenSigTimeoutTime" BU_SG_REL_ NR_1 SG_ 165 TS_CAN_Ma_SyncTimeSec 1000;
BA_REL_ "GenSigTimeoutTime" BU_SG_REL_ NR_1 SG_ 2264486933 TLT_RespMsgType_NR_01 5000;
BA_REL_ "GenSigTimeoutTime" BU_SG_REL_ NR_1 SG_ 2264486933 TLT_RespProtocolType_NR_01 5000;
BA_REL_ "GenSigTimeoutTime" BU_SG_REL_ NR_1 SG_ 2264486933 TLT_LapCounter_NR_01 5000;
BA_REL_ "GenSigTimeoutTime" BU_SG_REL_ NR_1 SG_ 2264486933 TLT_RespSequenceID_NR_01 5000;
BA_REL_ "GenSigTimeoutTime" BU_SG_REL_ NR_1 SG_ 2264486933 TLT_RespSlaveID_NR_01 5000;
BA_REL_ "GenSigTimeoutTime" BU_SG_REL_ NR_1 SG_ 2264486933 TLT_ReqIngressTimestampNs_NR_01 5000;
BA_REL_ "GenSigTimeoutTime" BU_SG_REL_ NR_1 SG_ 2264486933 TLT_ReqIngressTimestampS_NR_01 5000;
BA_REL_ "GenSigTimeoutTime" BU_SG_REL_ NR_1 SG_ 2264486933 TLT_RespEgressTimestampNs_NR_01 5000;
BA_REL_ "GenSigTimeoutTime" BU_SG_REL_ NR_1 SG_ 2264486933 TLT_RespEgressTimestampS_NR_01 5000;
BA_REL_ "GenSigTimeoutTime" BU_SG_REL_ NR_2 SG_ 165 TS_CAN_Ma_Type 1000;
BA_REL_ "GenSigTimeoutTime" BU_SG_REL_ NR_2 SG_ 165 TS_CAN_Ma_CRC 1000;
BA_REL_ "GenSigTimeoutTime" BU_SG_REL_ NR_2 SG_ 165 TS_CAN_Ma_SequenceCounter 1000;
BA_REL_ "GenSigTimeoutTime" BU_SG_REL_ NR_2 SG_ 165 TS_CAN_Ma_TimeDomain 1000;
BA_REL_ "GenSigTimeoutTime" BU_SG_REL_ NR_2 SG_ 165 TS_CAN_Ma_OVS 1000;
BA_REL_ "GenSigTimeoutTime" BU_SG_REL_ NR_2 SG_ 165 TS_CAN_Ma_SGW 1000;
BA_REL_ "GenSigTimeoutTime" BU_SG_REL_ NR_2 SG_ 165 TS_CAN_Ma_SyncTimeSec 1000;
VAL_ 1440 LS_Helligkeit_IR 254 "Init" 255 "Fehler" ;
VAL_ 1440 LS_Helligkeit_FW 1022 "Init" 1023 "Fehler" ;
VAL_ 1440 LS_defekt 0 "OK" 1 "defekt" ;
VAL_ 1440 LS_Verbau 0 "Init" 1 "Lichtsensor_verbaut" ;
VAL_ 1440 RS_Regenmenge 0 "0" 1 "0,0_bis_0,3" 2 "0,31_bis_1,4" 3 "1,41_bis_2,0" 4 "2,01_bis_2,8" 5 "2,81_bis_3,3" 6 "3,31_bis_4,0" 7 "4,01_bis_5,0" 8 "5,01_bis_7,0" 9 "7,01_bis_9,0" 10 "9,01_bis_11,0" 11 "11,01_bis_15,0" 12 "15,01_bis_22,0" 13 ">22,01" 14 "Init" 15 "Fehler" ;
VAL_ 1440 RS_Schwall 0 "Aus" 1 "Ein" ;
VAL_ 1440 RS_Verbau 0 "Init" 1 "Regensensor verbaut" ;
VAL_ 1440 RS_Verglasung_schliessen 0 "Verglasung nicht schliessen" 1 "Verglasung schliessen" ;
VAL_ 1440 RS_defekt 0 "OK" 1 "defekt" ;
VAL_ 1440 RS_Wischergeschwindigkeit 0 "kein Wischen" 1 "42 Huebe/min" 2 "45 Huebe/min" 3 "48 Huebe/min" 4 "51 Huebe/min" 5 "54 Huebe/min" 6 "57 Huebe/min" 7 "60 Huebe/min" ;
VAL_ 1440 RLS_Vorfeldhelligkeit_Boost 0 "groesser_24413_Lux" 1 "bis_24413_Lux" 2 "bis_22193_Lux" 3 "bis_20176_Lux" 4 "bis_18342_Lux" 5 "bis_16647_Lux" 6 "bis_15158_Lux" 7 "bis_13780_Lux" 8 "bis_12527_Lux" 9 "bis_11388_Lux" 10 "bis_10353_Lux" 11 "bis_9412_Lux" 12 "bis_8556_Lux" 13 "bis_7778_Lux" 14 "bis_7071_Lux" 15 "bis_6428_Lux" ;
VAL_ 1440 SLS_Helligkeit_IR 254 "Init" 255 "Fehler" ;
VAL_ 2463978697 SAL_LDS_Abblendlicht_Anf 0 "nicht_aktiv" 1 "aktiv" ;
VAL_ 2463978697 SAL_LDS_Assistenzfahrlicht_Anf 0 "nicht_aktiv" 1 "aktiv" ;
VAL_ 2463978697 SAL_LDS_Nullstellung_Anf 0 "nicht_aktiv" 1 "aktiv" ;
VAL_ 2463978697 SAL_LDS_Standlicht_Anf 0 "nicht_aktiv" 1 "aktiv" ;
VAL_ 2463978697 SBBR_SL_AnimDimm_Freigabe 0 "Dimmung_aus_Animation_aus" 1 "Dimmung_an_Animation_aus" 2 "Dimmung_aus_Animation_an" 3 "Dimmung_an_Animation_an" ;
VAL_ 2463978697 BCM2_Bremsl_durch_ECD 0 "Bremslicht_ist_aus" 1 "Bremslicht_durch_ECD_aktiv" ;
VAL_ 2463978697 SAL_LH_Anf 0 "nicht_angefordert" 1 "angefordert" ;
VAL_ 2463978697 SAL_BRL_Anf 0 "nicht_angefordert" 1 "angefordert" ;
VAL_ 2463978697 SAL_WBT_Bel 0 "nicht_angefordert" 1 "angefordert" ;
VAL_ 2463978697 SAL_CH_Anf 0 "nicht_angefordert" 1 "angefordert" ;
VAL_ 2463978697 SAL_PL_R_Anf 0 "nicht_angefordert" 1 "angefordert" ;
VAL_ 2463978697 SAL_PL_L_Anf 0 "nicht_angefordert" 1 "angefordert" ;
VAL_ 2463978697 SAL_BLK_R_Anf 0 "nicht_angefordert" 1 "angefordert" ;
VAL_ 2463978697 SAL_BLK_L_Anf 0 "nicht_angefordert" 1 "angefordert" ;
VAL_ 2463978697 SAL_RFL_Anf 0 "nicht_angefordert" 1 "angefordert" ;
VAL_ 2463978697 SAL_NSL_Anf 0 "nicht_angefordert" 1 "angefordert" ;
VAL_ 2463978697 SAL_SL_Anf 0 "nicht_angefordert" 1 "angefordert" ;
VAL_ 2463978697 SAL_HGB_Anf 0 "nicht_angefordert" 1 "angefordert" ;
VAL_ 2463978697 LWR_SollDC 254 "Init" 255 "Fehler" ;
VAL_ 2463978697 SAL_Bremszyklus 0 "nicht_aktiv" 1 "aktiv" ;
VAL_ 2463978697 SAL_Blinkerzyklus_R 0 "inaktiv" 1 "aktiv" ;
VAL_ 2463978697 SAL_Blinkerzyklus_L 0 "inaktiv" 1 "aktiv" ;
VAL_ 2463978697 LWR_Lampe 0 "LWR Fehlerlampe aus" 1 "LWR Fehlerlampe ein" ;
VAL_ 2463978697 AFS_Lampe 0 "Aus" 1 "Ein" ;
VAL_ 2463978697 LWR_Reisemodus_Texte 0 "keine_Anzeige" 1 "Umschaltung_auf_Linksverkehr_aktiv" 2 "Umschaltung_auf_Rechtsverkehr_aktiv" ;
VAL_ 2463978697 SAL_KZL_Anf 0 "nicht_angefordert" 1 "angefordert" ;
VAL_ 2463978697 SAL_KL_50 0 "aus" 1 "ein" ;
VAL_ 2463978697 SAL_KL_75a_vFzg 0 "aus" 1 "ein" ;
VAL_ 2463978697 SAL_KL_75a 0 "aus" 1 "ein" ;
VAL_ 2463978697 SAL_KL_75_vFzg 0 "aus" 1 "ein" ;
VAL_ 2463978697 SAL_Kl_75 0 "aus" 1 "ein" ;
VAL_ 2463978697 SAL_KL_50_5s 0 "aus" 1 "ein" ;
VAL_ 2463978697 SAL_Kl_15_vFzg_S 0 "aus" 1 "ein" ;
VAL_ 2463978697 SAL_Kl_15_vFzg 0 "aus" 1 "ein" ;
VAL_ 2463978697 SAL_Kl_15 0 "aus" 1 "ein" ;
VAL_ 2463978697 DLI_Ambex_RefStatus 0 "Init" 1 "notAvailable" 2 "Referenzlaufaktiv" 3 "Referenzlaufbeendet" 4 "Fehler" ;
VAL_ 2463978697 SAL_Aussenbeleuchtung_defekt 0 "ok" 1 "defekt" ;
VAL_ 980 BH_Blinker_li 0 "nicht_betaetigt" 1 "Blinkerhebel_Pos_li_betaetigt" ;
VAL_ 980 BH_Blinker_re 0 "nicht_betaetigt" 1 "Blinkerhebel_Pos_re_betaetigt" ;
VAL_ 980 BH_Lichthupe 0 "nicht_betaetigt" 1 "Blinkerhebel in Richtung Lichthupe betaetigt" ;
VAL_ 980 BH_Fernlicht 0 "nicht_betaetigt" 1 "Blinkerhebel_in_Richtung_Fernlicht_betaetigt" ;
VAL_ 980 WH_Tipwischen 0 "nicht_betaetigt" 1 "betaetigt" ;
VAL_ 980 WH_Intervall 0 "aus" 1 "Wischerhebel in Stellung Intervall" ;
VAL_ 980 WH_WischerStufe1 0 "aus" 1 "Wischerhebel in Stufe Wischen 1" ;
VAL_ 980 WH_WischerStufe2 0 "aus" 1 "Wischerhebel in Stufe Wischen 2" ;
VAL_ 980 WH_Frontwaschen 0 "aus" 1 "Wischerhebel in Stellung Wisch Wasch vorne" ;
VAL_ 980 WH_Heckintervall 0 "nicht_betaetigt" 1 "Wischerhebel in Stellung Heckintervall" ;
VAL_ 980 WH_Heckwaschen 0 "nicht_betaetigt" 1 "Wischerhebel in Stellung Wisch Wasch hinten" ;
VAL_ 980 WH_Intervallstufen 0 "Init / Default" 1 "Intervallstufe 1" 5 "Intervallstufe 2" 9 "Intervallstufe 3" 13 "Intervallstufe 4" 15 "Fehler" ;
VAL_ 980 FAS_Taster 0 "nicht_betaetigt" 1 "betaetigt" ;
VAL_ 980 FAS_Taster_Fehler 0 "kein_Fehler" 1 "Fehler" ;
VAL_ 980 SMLS_Hupe 0 "nicht_betaetigt" 1 "Hupe_gedrueckt" ;
VAL_ 980 LRH_On_Off 0 "LRH_aus__keine Anzeige" 1 "LRH_aus" 2 "LRH_ein" 3 "Fehler" ;
VAL_ 980 LSS_Tastencode 0 "Key_Released__No_Key" 4 "Up" 5 "Down" 7 "OK__ThumbWheel_Button" ;
VAL_ 980 LRH_aktiv 0 "inaktiv" 1 "aktiv" ;
VAL_ 980 SMLS_P_verriegelt 0 "Init" 1 "nicht_verriegelt" 2 "verriegelt" 3 "Fehler" ;
VAL_ 980 SMLS_P_verriegelt_plausibel 0 "unplausibel" 1 "plausibel" ;
VAL_ 980 WH_SRA 0 "SRA_Aus" 1 "SRA_Ein" ;
VAL_ 980 WH_Wischer_Fehler 0 "kein_Fehler" 1 "Fehler" ;
VAL_ 980 BH_Blinker_Fehler 0 "kein_Fehler" 1 "Fehler" ;
VAL_ 980 SMLS_PTT 0 "nicht_betaetigt" 1 "PTT_gedrueckt" ;
VAL_ 980 WH_Tipwischen_lang 0 "nicht_betaetigt" 1 "betaetigt" ;
VAL_ 2589283756 SOK_ungeschuetzte_Zeit 0 "Init" ;
VAL_ 1413 SI_Sammel_SG_Fehler 61 "Reserviert" 62 "Overflow" 63 "ungueltig" ;
VAL_ 1413 SI_P_Mode_gueltig 0 "dezentraler_Produktionsmode" 1 "zentraler_Produktionsmode" ;
VAL_ 1413 SI_Diagnose_Aktiv 0 "inaktiv" 1 "aktiv" ;
VAL_ 1413 SI_QRS_Mode 0 "QRS_Messmodus_nicht_aktiv" 1 "QRS_Messmodus_aktiv" ;
VAL_ 1413 SI_T_Mode 0 "Transportmodus_nicht_aktiv" 1 "Transportmodus_aktiv" ;
VAL_ 1413 SI_NWDF 0 "Ueberwachung_nicht_freigegeben" 1 "Ueberwachung_freigegeben" ;
VAL_ 1413 SI_NWDF_gueltig 0 "NWDF_wird_nicht_unterstuetzt" 1 "NWDF_wird_unterstuetzt" ;
VAL_ 1413 SI_Sammelfehler 0 "kein_Sammelfehler" 1 "Sammelfehler" ;
VAL_ 1413 GW_KD_Fehler 0 "kein_KD_Fehler" 1 "KD_Fehler" ;
VAL_ 1413 SI_T_Schutz 0 "Transportschutz_nicht_aktiv" 1 "Transportschutz_aktiv" ;
VAL_ 1413 SI_P_Mode 0 "inaktiv" 1 "aktiv" ;
VAL_ 1413 SI_BUS_01 0 "keine_Busruhe" 1 "Busruhe" ;
VAL_ 1413 SI_BUS_02 0 "keine_Busruhe" 1 "Busruhe" ;
VAL_ 1413 SI_BUS_03 0 "keine_Busruhe" 1 "Busruhe" ;
VAL_ 1413 SI_BUS_04 0 "keine_Busruhe" 1 "Busruhe" ;
VAL_ 1413 SI_BUS_05 0 "keine_Busruhe" 1 "Busruhe" ;
VAL_ 1413 SI_BUS_06 0 "keine_Busruhe" 1 "Busruhe" ;
VAL_ 1413 SI_BUS_07 0 "keine_Busruhe" 1 "Busruhe" ;
VAL_ 1413 SI_BUS_08 0 "keine_Busruhe" 1 "Busruhe" ;
VAL_ 1413 SI_BUS_09 0 "keine_Busruhe" 1 "Busruhe" ;
VAL_ 1413 SI_BUS_10 0 "keine_Busruhe" 1 "Busruhe" ;
VAL_ 1413 SI_BUS_11 0 "keine_Busruhe" 1 "Busruhe" ;
VAL_ 1413 SI_BUS_12 0 "keine_Busruhe" 1 "Busruhe" ;
VAL_ 1413 SI_BUS_13 0 "keine_Busruhe" 1 "Busruhe" ;
VAL_ 1413 SI_BUS_14 0 "keine_Busruhe" 1 "Busruhe" ;
VAL_ 1413 SI_BUS_15 0 "keine_Busruhe" 1 "Busruhe" ;
VAL_ 1413 SI_Bus_Identifikation 16 "CAN_Diagnose" 17 "CAN_Antrieb" 18 "CAN_Komfort" 19 "CAN_Infotainment" 20 "CAN_Fahrwerk" 21 "CAN_Extended" 22 "CAN_Hybrid" 23 "CAN_Lade" 24 "CAN_Kombi" 25 "CAN_Komfort_2" 26 "CAN_AFS" 27 "CAN_MIB" 28 "CAN_Batterie_BMC" 29 "CAN_Motor" 31 "CAN_Airbag_Sicherheitssysteme" 33 "CAN_FahrerAssistenzSysteme" 34 "CAN_Migration" 35 "CAN_Connect" 36 "CAN_AnzeigeBedienung" 37 "CAN_ElectricalVehicle" 40 "CAN_Telematik" 41 "CAN_MFL" 42 "CAN_FahrerAssistenzSysteme_2" 43 "CAN_FahrerAssistenzSysteme_3" 45 "CAN_Fahrwerk_2" 47 "CAN_Komfort_3" 48 "FlexRay_A" 49 "FlexRay_B" 70 "CAN_PowerSupply" 71 "CAN_Passenger" 72 "CAN_Connect_2" 73 "CAN_ElectricalVehicle_2" 74 "CAN_ElectricalVehicle_3" 75 "CAN_ElectricalVehicle_4" 76 "CAN_AutonomousDriving_1" 77 "CAN_AutonomousDriving_2" 78 "CAN_Drive" 79 "CAN_NVEV" 97 "VLAN_FAS" 98 "VLAN_Infotainment" 99 "VLAN_Connect" 100 "VLAN_Komfort" 101 "VLAN_Antrieb" 102 "VLAN_Diagnose" 103 "VLAN_Internet" 104 "VLAN_Gateway" 105 "VLAN_Remote_FC" 106 "VLAN_Connect_2" 107 "VLAN_Licht" 108 "VLAN_Charge" 109 "VLAN_Cockpit" 110 "VLAN_Connect_3" 111 "VLAN_IoT" 112 "VLAN_CarPerformance" 113 "VLAN_ConMod" 114 "VLAN_FAS2" 115 "VLAN_DMZ_1" 116 "VLAN_SDS" 117 "VLAN_Rechenplattform" 118 "VLAN_Internet_2" 119 "VLAN_MaaS" 176 "HCP1_CANFD01" 177 "HCP1_CANFD02" 178 "HCP1_CANFD03" 179 "HCP1_CANFD04" 180 "HCP1_CANFD05" 181 "HCP1_CANFD06" 182 "HCP1_CANFD07" 183 "HCP1_CANFD08" 186 "HCP4_CANFD03" 187 "HCP4_CANFD04" 188 "HCP1_CANFD09" 189 "HCP4_CANFD06" 190 "HCP4_CANFD07" 191 "HCP4_CANFD08" 192 "HCP4_CANFD09" 193 "HCP4_CANFD10" 194 "HCP1_CANFD10" 195 "ICAS1_CANFD2_HCP5_CANFD02" 196 "HCP1_CANFD11" 197 "WU_HCP1_CANFD" 199 "WU_HCP2_CANFD" 200 "WU_HCP3_CANFD" 201 "WU_HCP4_CANFD" 202 "HCP3_CANFD02" 204 "ESC_CANFD" 205 "HCP4_CANFD11" 206 "HCP4_CANFD12" 207 "CAN_Innenraumsensorik" 212 "WU_ConMod_CANFD" 213 "WU_PASD_CANFD" 215 "CAN_MobileDeviceKey" 217 "CAN_Tuerantrieb_VL" 218 "CAN_Tuerantrieb_VR" 219 "CAN_Tuerantrieb_HL" 220 "CAN_Tuerantrieb_HR" 221 "CAN_Komfort_4" 222 "CAN_Komfort_5" ;
VAL_ 1413 SI_CAB_V15 0 "Init" 1 "CAB_01_Antrieb" 2 "CAB_02_Hybrid_Laden" 4 "CAB_03_Fahrwerk" 8 "CAB_04_Fahrerassistenz" 16 "CAB_05_Komfort" 32 "CAB_06_Anzeige" 64 "CAB_07_Connect" 128 "CAB_08_MIB" 256 "CAB_09_Standheizung" 512 "CAB_10_MDK" 1024 "CAB_11_VLAN_Fahrerassistenz" 4096 "CAB_13_VLAN_Connect" 8192 "CAB_14_VLAN_Infotainment" 16384 "CAB_15_Laden" 32768 "CAB_16_Licht" 65536 "CAB_17_RTM" ;
VAL_ 2589283775 NM_Req_Kessy 0 "Inaktiv" 1 "Nachlauf_aufgrund_KY" ;
VAL_ 2589283775 NM_Req_USS 0 "Inaktiv" 1 "Nachlauf_aufgrund_USS" ;
VAL_ 2589283775 NM_Req_IAA_PSO 0 "Inaktiv" 1 "Nachlauf_aufgrund_IAA_PSO" ;
VAL_ 2589283775 NM_Req_KS 0 "Inaktiv" 1 "Nachlauf_aufgrund_KS" ;
VAL_ 2589283775 NM_Req_PaCo 0 "Inaktiv" 1 "Nachlauf_aufgrund_PaCo" ;
VAL_ 2589283775 NM_Req_STK 0 "inaktiv" 1 "Nachlauf_aktiv" ;
VAL_ 2589283775 NM_Req_ZV 0 "inaktiv" 1 "Nachlauf_aktiv" ;
VAL_ 2589283775 NM_Req_RTM 0 "inaktiv" 1 "Nachlauf_aktiv" ;
VAL_ 2589283775 NM_Req_ZM 0 "Inaktiv" 1 "Nachlauf_aufgrund_ZM" ;
VAL_ 2589283775 NM_Req_FoD 0 "Inaktiv" 1 "Nachlauf_aufgrund_FoD" ;
VAL_ 2589283775 NM_Req_EMHLR 0 "inaktiv" 1 "Nachlauf_aktiv" ;
VAL_ 2589283775 NM_Req_HVEM 0 "Inaktiv" 1 "Nachlauf_aufgrund_HVEM" ;
VAL_ 2589283775 NM_Req_ECM 0 "inaktiv" 1 "Nachlauf_aktiv" ;
VAL_ 2589283775 NM_Req_CMS 0 "inaktiv" 1 "Nachlauf_aktiv" ;
VAL_ 2589283775 NM_Req_DCP_01 0 "inaktiv" 1 "Nachlauf_aktiv" ;
VAL_ 2589283775 NM_Req_DIM 0 "inaktiv" 1 "Nachlauf_aktiv" ;
VAL_ 2589283775 NM_Req_SAL 0 "Inaktiv" 1 "Nachlauf_aufgrund_SAL" ;
VAL_ 2589283775 NM_Req_KLS 0 "Inaktiv" 1 "Nachlauf_aufgrund_KLS" ;
VAL_ 2589283775 NM_Req_DCP_02 0 "inaktiv" 1 "Nachlauf_aktiv" ;
VAL_ 2589283775 NM_Req_SWC1 0 "inaktiv" 1 "Nachlauf_aktiv" ;
VAL_ 2589283775 NM_Req_SWC2 0 "inaktiv" 1 "Nachlauf_aktiv" ;
VAL_ 2589283775 NM_Req_internal 0 "inaktiv" 1 "Nachlauf_aktiv" ;
VAL_ 2589283775 NM_Req_EOC 0 "Inaktiv" 1 "Nachlauf_Aktiv" ;
VAL_ 2589283775 NM_Req_SWC3 0 "Inaktiv" 1 "Nachlauf_aktiv" ;
VAL_ 2589283775 NM_aktiv_CWU 0 "nicht_aktiv" 1 "aktiv" ;
VAL_ 2589283775 NM_aktiv_Buskopplung 0 "nicht_aktiv" 1 "aktiv" ;
VAL_ 2589283775 NM_aktiv_CAB 0 "nicht_aktiv" 1 "aktiv" ;
VAL_ 2589283775 NM_Req_SWC4 0 "Inaktiv" 1 "Nachlauf_aktiv" ;
VAL_ 2589283775 NM_Req_SWC5 0 "Inaktiv" 1 "Nachlauf_aktiv" ;
VAL_ 2589283775 NM_Req_SWC6 0 "Inaktiv" 1 "Nachlauf_aktiv" ;
VAL_ 2589283775 NM_Req_SWC7 0 "Inaktiv" 1 "Nachlauf_aktiv" ;
VAL_ 2589283775 NM_Req_SWC8 0 "Inaktiv" 1 "Nachlauf_aktiv" ;
VAL_ 2589283775 Powerstate_Act 0 "Init" 1 "KL30_to_FullOperation" 2 "Reset_to_FullOperation" 5 "Parking_to_FullOperation" 7 "FullOperation_to_ChargingMin" 9 "FullOperation_to_Parking" 13 "ChargingMin_to_FullOperation" 15 "Parking_to_TransportMode" 17 "Transport_to_Parking" 21 "ParkingMin_to_Parking" ;
VAL_ 2589283775 NM_Req_LIN_EMHLR 0 "Inaktiv" 1 "Nachlauf_aktiv" ;
VAL_ 2589283775 NM_Req_LIN_AI 0 "Inaktiv" 1 "Nachlauf_aktiv" ;
VAL_ 2589283775 NM_Req_LIN_EOC 0 "Inaktiv" 1 "Nachlauf_aktiv" ;
VAL_ 2589283775 NM_Req_LIN_SWC1 0 "Inaktiv" 1 "Nachlauf_aktiv" ;
VAL_ 2589283775 NM_Req_LIN_SWC2 0 "Inaktiv" 1 "Nachlauf_aktiv" ;
VAL_ 2589283775 NM_Req_LIN_SWC3 0 "Inaktiv" 1 "Nachlauf_aktiv" ;
VAL_ 2589283775 Diagnose_ActLine 0 "Inaktiv" 1 "Nachlauf_aktiv" ;
VAL_ 2589283775 Diagnose_OnBoard 0 "Inaktiv" 1 "Nachlauf_aktiv" ;
VAL_ 2589283775 Diagnose_OffBoard 0 "Inaktiv" 1 "Nachlauf_aktiv" ;
VAL_ 2589283947 NM_Reason_Kessy 0 "Inaktiv" ;
VAL_ 2589283947 NM_Reason_USS 0 "Inaktiv" ;
VAL_ 2589283947 NM_Reason_IAA_PSO 0 "Inaktiv" ;
VAL_ 2589283947 NM_Reason_KS 0 "Inaktiv" ;
VAL_ 2589283947 NM_Reason_PaCo 0 "Inaktiv" ;
VAL_ 2589283947 NM_Reason_STK 0 "Inaktiv" ;
VAL_ 2589283947 NM_Reason_ZV 0 "Inaktiv" ;
VAL_ 2589283947 NM_Reason_RTM 0 "Inaktiv" ;
VAL_ 2589283947 NM_Reason_ZM 0 "Inaktiv" ;
VAL_ 2589283947 NM_Reason_FoD 0 "Inaktiv" ;
VAL_ 2589283947 NM_Reason_EMHLR 0 "Inaktiv" ;
VAL_ 2589283947 NM_Reason_HVEM 0 "Inaktiv" ;
VAL_ 2589283947 NM_Reason_ECM 0 "Inaktiv" ;
VAL_ 2589283947 NM_Reason_CMS 0 "Inaktiv" ;
VAL_ 2589283947 NM_Reason_DCP_1 0 "Inaktiv" ;
VAL_ 2589283947 NM_Reason_DCP_2 0 "Inaktiv" ;
VAL_ 2589283947 NM_Reason_DIM 0 "Inaktiv" ;
VAL_ 2589283947 NM_Reason_SAL 0 "Inaktiv" ;
VAL_ 2589283947 NM_Reason_KLS 0 "Inaktiv" ;
VAL_ 2589283947 NM_Reason_SWC1 0 "Inaktiv" ;
VAL_ 2589283947 NM_Reason_SWC2 0 "Inaktiv" ;
VAL_ 2589283947 NM_Reason_ICAS1_internal 0 "Inaktiv" ;
VAL_ 2589283947 NM_Reason_EOC 0 "Inaktiv" ;
VAL_ 2589283947 NM_Reason_SWC3 0 "Inaktiv" ;
VAL_ 2589283947 NM_Reason_SWC4 0 "Inaktiv" ;
VAL_ 2589283947 NM_Reason_SWC5 0 "Inaktiv" ;
VAL_ 2589283947 Powerstate_Prev_01 0 "Init" 1 "KL30_to_FullOperation" 2 "Reset_to_FullOperation" 5 "Parking_to_FullOperation" 7 "FullOperation_to_ChargingMin" 9 "FullOperation_to_Parking" 13 "ChargingMin_to_FullOperation" 15 "Parking_to_TransportMode" 17 "Transport_to_Parking" 21 "ParkingMin_to_Parking" ;
VAL_ 2589283947 Powerstate_Prev_02 0 "Init" 1 "KL30_to_FullOperation" 2 "Reset_to_FullOperation" 5 "Parking_to_FullOperation" 7 "FullOperation_to_ChargingMin" 9 "FullOperation_to_Parking" 13 "ChargingMin_to_FullOperation" 15 "Parking_to_TransportMode" 17 "Transport_to_Parking" 21 "ParkingMin_to_Parking" ;
VAL_ 2589283947 NM_Reason_SWC6 0 "Inaktiv" ;
VAL_ 2589283947 NM_Reason_SWC7 0 "Inaktiv" ;
VAL_ 2589283947 NM_Reason_SWC8 0 "Inaktiv" ;
VAL_ 619 TA_ACC_Sollstatus 0 "Init" 1 "ACC_aktivieren" 2 "ACC_deaktivieren" ;
VAL_ 619 TA_Status 0 "Keine_Anzeige" 1 "Passiv" 2 "Aktiv" 3 "Warnung" ;
VAL_ 619 TA_Spurwechsel 0 "Kein_Spurwechsel" 1 "Spurwechsel_links" 2 "Spurwechsel_rechts" 3 "Spurwechselfreigabe_links" 4 "Spurwechselfreigabe_rechts" 5 "TA_Modus_StandBy" 6 "Spurwechselfreigabe_li_und_re" ;
VAL_ 619 TA_Texte 0 "Keine_Anzeige" 1 "Nicht_verfuegbar" 2 "Modus_TA_m_ass_Spurwechsel_gewae" 3 "Modus_ACC_ausgewaehlt" 4 "Modus_TravelAssist_ausgewaehlt" 5 "Spurwechsel_nicht_verfuegbar" 6 "Spurwechsel_abgebrochen" 7 "Spurw_abgebr_Lenkung_uebernehmen" ;
VAL_ 619 TA_FoD_Status 0 "Init" 1 "kein_TA_verbaut" 2 "TA_Low_verbaut" 3 "TA_Low_und_TA_High_verbaut" ;
VAL_ 619 TA_Spurwechsel_Ready 0 "nicht_moeglich" 1 "links_moeglich" 2 "rechts_moeglich" 3 "links_rechts_moeglich" ;
VAL_ 619 TA_Texte_02 0 "Keine_Anzeige" 1 "TA_zur_Zeit_nicht_aktivierbar" 2 "Zurzeit_nur_Spurfuehrung_verfueg" 3 "Fahreruebernahme_stumm" 4 "Fahreruebernahme_leise" 5 "Systemgrenzenwarnung" 6 "Fehler_TA_Low_keine_Sensorsicht" 7 "Fehler_TA_High_keine_Sensorsicht" 8 "Reserved_08" 9 "Reserved_09" 10 "Reserved_10" 11 "Reserved_11" 12 "Reserved_12" 13 "Reserved_13" 14 "Reserved_14" 15 "Reserved_15" ;
VAL_ 619 TA_Handsoff_LED 0 "keine_Anzeige" 1 "weiss" 2 "rot" 3 "reserviert" ;
VAL_ 619 TA_aktiv_HMI 0 "nicht_aktiv" 1 "TA_Low_aktiv" 2 "TA_High_aktiv" ;
VAL_ 619 TA_Fehler 0 "kein_Fehler" 1 "Fehler_TA_Low" 2 "Fehler_TA_Low_keine_Sensorsicht" 3 "Fehler_TA_High" 4 "Fehler_TA_High_keine_Sensorsicht" ;
VAL_ 619 TA_Ueberholhilfe 0 "Init" 1 "keine_Ueberholhilfe" 2 "ACC_Ueberholhilfe" 3 "TA_FSW_Ueberholhilfe" ;
VAL_ 2589283750 KBI_QBit_Aussen_Temp_gef 0 "gueltiger_Wert" 1 "Ersatz_Init_oder_Fehlerwert" ;
VAL_ 2589283750 KBI_Aussen_Temp_gef 253 "nicht verbaut" 254 "Init" 255 "Fehler" ;
VAL_ 165 TS_CAN_Ma_Type 32 "SYNC_CRC_secured_message_format" 40 "FUP_CRC_secured_message_format" ;
VAL_ 165 TS_CAN_Ma_SGW 0 "SyncToGTM" 1 "SyncToSubDomain" ;
VAL_ 2264486930 TLT_ReqMsgType_ACC_01 0 "Init" 1 "TLT_Request_Message" 2 "TLT_Response_Message" 3 "TLT_Response_FollowUp_Message" 7 "Fehler" ;
VAL_ 2264486930 TLT_ReqProtocolType_ACC_01 0 "Init" 1 "Request_Response" 2 "Extended_Req_Resp_w_FollowUp" 3 "Extended_Req_Resp_across_cycles" 7 "Fehler" ;
VAL_ 2264486930 TLT_ReqSlaveID_ACC_01 254 "Init" 255 "Fehler" ;
VAL_ 2264486930 TLT_ReqSequenceID_ACC_01 65534 "Init" 65535 "Fehler" ;
VAL_ 2264486930 TLT_CurSlaveTimestampS_ACC_01 0 "Init" 0 "Fehler" ;
VAL_ 2264486930 TLT_CurSlaveTimestampNs_ACC_01 0 "Init" 0 "Fehler" ;
VAL_ 2264486930 TLT_CurRTTS_ACC_01 0 "Init" 0 "Fehler" ;
VAL_ 2264486930 TLT_CurRTTNs_ACC_01 0 "Init" 0 "Fehler" ;
VAL_ 2264486930 TLT_ErrorMaxNs_ACC_01 0 "Init" 0 "Fehler" ;
VAL_ 2264486930 TLT_ErrorMinNs_ACC_01 0 "Init" 0 "Fehler" ;
VAL_ 2264486928 TLT_ReqMsgType_Kamera 0 "Init" 1 "TLT_Request_Message" 2 "TLT_Response_Message" 3 "TLT_Response_FollowUp_Message" 7 "Fehler" ;
VAL_ 2264486928 TLT_ReqProtocolType_Kamera 0 "Init" 1 "Request_Response" 2 "Extended_Req_Resp_w_FollowUp" 3 "Extended_Req_Resp_across_cycles" 7 "Fehler" ;
VAL_ 2264486928 TLT_ReqSlaveID_Kamera 254 "Init" 255 "Fehler" ;
VAL_ 2264486928 TLT_ReqSequenceID_Kamera 65534 "Init" 65535 "Fehler" ;
VAL_ 2264486928 TLT_CurSlaveTimestampS_Kamera 0 "Init" 0 "Fehler" ;
VAL_ 2264486928 TLT_CurSlaveTimestampNs_Kamera 0 "Init" 0 "Fehler" ;
VAL_ 2264486928 TLT_CurRTTS_Kamera 0 "Init" 0 "Fehler" ;
VAL_ 2264486928 TLT_CurRTTNs_Kamera 0 "Init" 0 "Fehler" ;
VAL_ 2264486928 TLT_ErrorMaxNs_Kamera 0 "Init" 0 "Fehler" ;
VAL_ 2264486928 TLT_ErrorMinNs_Kamera 0 "Init" 0 "Fehler" ;
VAL_ 2264486932 TLT_ReqMsgType_NR_01 0 "Init" 1 "TLT_Request_Message" 2 "TLT_Response_Message" 3 "TLT_Response_FollowUp_Message" 7 "Fehler" ;
VAL_ 2264486932 TLT_ReqProtocolType_NR_01 0 "Init" 1 "Request_Response" 2 "Extended_Req_Resp_w_FollowUp" 3 "Extended_Req_Resp_across_cycles" 7 "Fehler" ;
VAL_ 2264486932 TLT_ReqSlaveID_NR_01 254 "Init" 255 "Fehler" ;
VAL_ 2264486932 TLT_ReqSequenceID_NR_01 65534 "Init" 65535 "Fehler" ;
VAL_ 2264486932 TLT_CurSlaveTimestampS_NR_01 0 "Init" 0 "Fehler" ;
VAL_ 2264486932 TLT_CurSlaveTimestampNs_NR_01 0 "Init" 0 "Fehler" ;
VAL_ 2264486932 TLT_CurRTTS_NR_01 0 "Init" 0 "Fehler" ;
VAL_ 2264486932 TLT_CurRTTNs_NR_01 0 "Init" 0 "Fehler" ;
VAL_ 2264486932 TLT_ErrorMaxNs_NR_01 0 "Init" 0 "Fehler" ;
VAL_ 2264486932 TLT_ErrorMinNs_NR_01 0 "Init" 0 "Fehler" ;
VAL_ 2264486934 TLT_ReqMsgType_NR_02 0 "Init" 1 "TLT_Request_Message" 2 "TLT_Response_Message" 3 "TLT_Response_FollowUp_Message" 7 "Fehler" ;
VAL_ 2264486934 TLT_ReqProtocolType_NR_02 0 "Init" 1 "Request_Response" 2 "Extended_Req_Resp_w_FollowUp" 3 "Extended_Req_Resp_across_cycles" 7 "Fehler" ;
VAL_ 2264486934 TLT_ReqSlaveID_NR_02 254 "Init" 255 "Fehler" ;
VAL_ 2264486934 TLT_ReqSequenceID_NR_02 65534 "Init" 65535 "Fehler" ;
VAL_ 2264486934 TLT_CurSlaveTimestampS_NR_02 0 "Init" 0 "Fehler" ;
VAL_ 2264486934 TLT_CurSlaveTimestampNs_NR_02 0 "Init" 0 "Fehler" ;
VAL_ 2264486934 TLT_CurRTTS_NR_02 0 "Init" 0 "Fehler" ;
VAL_ 2264486934 TLT_CurRTTNs_NR_02 0 "Init" 0 "Fehler" ;
VAL_ 2264486934 TLT_ErrorMaxNs_NR_02 0 "Init" 0 "Fehler" ;
VAL_ 2264486934 TLT_ErrorMinNs_NR_02 0 "Init" 0 "Fehler" ;
VAL_ 2264486931 TLT_RespMsgType_ACC_01 0 "Init" 1 "TLT_Request_Message" 2 "TLT_Response_Message" 3 "TLT_Response_FollowUp_Message" 7 "Fehler" ;
VAL_ 2264486931 TLT_RespProtocolType_ACC_01 0 "Init" 1 "Request_Response" 2 "Extended_Req_Resp_w_FollowUp" 3 "Extended_Req_Resp_across_cycles" 7 "Fehler" ;
VAL_ 2264486931 TLT_LapCounter_ACC_01 16382 "Init" 16383 "Fehler" ;
VAL_ 2264486931 TLT_RespSequenceID_ACC_01 65534 "Init" 65535 "Fehler" ;
VAL_ 2264486931 TLT_RespSlaveID_ACC_01 254 "Init" 255 "Fehler" ;
VAL_ 2264486931 TLT_ReqIngressTimestampNs_ACC_01 0 "Init" 0 "Fehler" ;
VAL_ 2264486931 TLT_ReqIngressTimestampS_ACC_01 0 "Init" 0 "Fehler" ;
VAL_ 2264486931 TLT_RespEgressTimestampNs_ACC_01 0 "Init" 0 "Fehler" ;
VAL_ 2264486931 TLT_RespEgressTimestampS_ACC_01 0 "Init" 0 "Fehler" ;
VAL_ 2264486929 TLT_RespMsgType_Kamera 0 "Init" 1 "TLT_Request_Message" 2 "TLT_Response_Message" 3 "TLT_Response_FollowUp_Message" 7 "Fehler" ;
VAL_ 2264486929 TLT_RespProtocolType_Kamera 0 "Init" 1 "Request_Response" 2 "Extended_Req_Resp_w_FollowUp" 3 "Extended_Req_Resp_across_cycles" 7 "Fehler" ;
VAL_ 2264486929 TLT_LapCounter_Kamera 16382 "Init" 16383 "Fehler" ;
VAL_ 2264486929 TLT_RespSequenceID_Kamera 65534 "Init" 65535 "Fehler" ;
VAL_ 2264486929 TLT_RespSlaveID_Kamera 254 "Init" 255 "Fehler" ;
VAL_ 2264486929 TLT_ReqIngressTimestampNs_Kamera 0 "Init" 0 "Fehler" ;
VAL_ 2264486929 TLT_ReqIngressTimestampS_Kamera 0 "Init" 0 "Fehler" ;
VAL_ 2264486929 TLT_RespEgressTimestampNs_Kamera 0 "Init" 0 "Fehler" ;
VAL_ 2264486929 TLT_RespEgressTimestampS_Kamera 0 "Init" 0 "Fehler" ;
VAL_ 2264486933 TLT_RespMsgType_NR_01 0 "Init" 1 "TLT_Request_Message" 2 "TLT_Response_Message" 3 "TLT_Response_FollowUp_Message" 7 "Fehler" ;
VAL_ 2264486933 TLT_RespProtocolType_NR_01 0 "Init" 1 "Request_Response" 2 "Extended_Req_Resp_w_FollowUp" 3 "Extended_Req_Resp_across_cycles" 7 "Fehler" ;
VAL_ 2264486933 TLT_LapCounter_NR_01 16382 "Init" 16383 "Fehler" ;
VAL_ 2264486933 TLT_RespSequenceID_NR_01 65534 "Init" 65535 "Fehler" ;
VAL_ 2264486933 TLT_RespSlaveID_NR_01 254 "Init" 255 "Fehler" ;
VAL_ 2264486933 TLT_ReqIngressTimestampNs_NR_01 0 "Init" 0 "Fehler" ;
VAL_ 2264486933 TLT_ReqIngressTimestampS_NR_01 0 "Init" 0 "Fehler" ;
VAL_ 2264486933 TLT_RespEgressTimestampNs_NR_01 0 "Init" 0 "Fehler" ;
VAL_ 2264486933 TLT_RespEgressTimestampS_NR_01 0 "Init" 0 "Fehler" ;
VAL_ 2264486935 TLT_RespMsgType_NR_02 0 "Init" 1 "TLT_Request_Message" 2 "TLT_Response_Message" 3 "TLT_Response_FollowUp_Message" 7 "Fehler" ;
VAL_ 2264486935 TLT_RespProtocolType_NR_02 0 "Init" 1 "Request_Response" 2 "Extended_Req_Resp_w_FollowUp" 3 "Extended_Req_Resp_across_cycles" 7 "Fehler" ;
VAL_ 2264486935 TLT_LapCounter_NR_02 16382 "Init" 16383 "Fehler" ;
VAL_ 2264486935 TLT_RespSequenceID_NR_02 65534 "Init" 65535 "Fehler" ;
VAL_ 2264486935 TLT_RespSlaveID_NR_02 254 "Init" 255 "Fehler" ;
VAL_ 2264486935 TLT_ReqIngressTimestampNs_NR_02 0 "Init" 0 "Fehler" ;
VAL_ 2264486935 TLT_ReqIngressTimestampS_NR_02 0 "Init" 0 "Fehler" ;
VAL_ 2264486935 TLT_RespEgressTimestampNs_NR_02 0 "Init" 0 "Fehler" ;
VAL_ 2264486935 TLT_RespEgressTimestampS_NR_02 0 "Init" 0 "Fehler" ;
VAL_ 1447 OCU_Privacymode_Locationdata 0 "Init" 1 "locationdata_freigabe" 2 "locationdata_gesperrt" ;
VAL_ 1447 OCU_Privacymode_Status 0 "Init" 1 "Privacymode_not_active" 2 "Privacymode_active" ;
VAL_ 1447 MOD_Energie_Anf 0 "Keine_Anforderung" 1 "Anforderung_NV" 2 "Anforderung_HV_Nutzung_Erlaubt" 3 "Fehler" ;
VAL_ 1447 FaceRec_Enroll_Challenge_Request 0 "SEND_NOTHING" 1 "SEND_CHALLENGE" ;
VAL_ 1447 iCall_active 0 "inaktiv" 1 "aktiv" ;
VAL_ 1447 bCall_active 0 "bcall_inactive" 1 "bcall_active" ;
VAL_ 1447 eCall_Funktionsstatus_02 0 "kein_Fehler" 1 "Manueller_Notruf_aktiv" 2 "Automatischer_Notruf_aktiv" 7 "Init" ;
VAL_ 1447 eCall_Funktionsstatus 0 "kein_Fehler" 1 "Fkt_eingeschraenkt" 2 "Fkt_eingeschraenkt_service" 3 "Fkt_nicht_verfuegbar" 4 "Fkt_Service" 5 "Fkt_deaktiviert" 6 "Fkt_aktiviert" 7 "init" ;
VAL_ 1447 TM_Spiegel_Anklappen 0 "Init" 1 "Spiegel_anklappen" ;
VAL_ 1447 TM_Nur_Hupen 0 "inaktiv" 1 "aktiv" ;
VAL_ 1447 TM_Door_Lock 0 "Init" 1 "door_lock" ;
VAL_ 1447 TM_Door_Unlock 0 "Init" 1 "door_unlock" ;
VAL_ 1447 TM_Warnblinken 0 "Init" 1 "Warnblinken_on" ;
VAL_ 1447 TM_Panik_Alarm 0 "Init" 1 "panik_alarm_on" ;
VAL_ 1447 TM_ZV_Signatur 0 "Init" ;
VAL_ 2463978729 TPA_PaCo_Parking_lot_selected 0 "Parking_lot_not_selected" 1 "Parking_lot_selected" ;
VAL_ 2463978729 TPA_PaCo_MainState 0 "Init" 1 "InOperation_NoError" 7 "Error" ;
VAL_ 2463978729 TPA_PaCo_Parking_lot_available 0 "No_Parking_lot_available" 1 "One_Parking_lot_available" 2 "Multiple_Parking_lots_available" ;
VAL_ 2463978729 TPA_PaCo_Preselection_State 0 "No_Preselection" 1 "Parking_lot_preselected" 2 "Start_position_reached" ;
VAL_ 2463978729 TPA_PaCo_FunctionState 0 "Passive_Standby" 1 "Park_In_Intervention" 2 "Park_Out_Intervention" 3 "Resume_Possible" 4 "Completed" 5 "Cancelled" 6 "Not_Activatable" ;
VAL_ 2463978729 TPA_PaCo_Parkout_Training 0 "Inactive" 1 "Active" ;
VAL_ 2463978729 TPA_PaCo_Number_ParkingManeuvers 0 "No_Parking_lot_recognised" 1 "One_Parking_lot_recognised" 2 "Two_Parking_lots_recognised" 3 "Three_Parking_lots_recognised" 4 "Four_Parking_lots_recognised" 5 "Five_Parking_lots_recognised" 6 "Six_Parking_lots_recognised" 7 "Seven_Parking_lots_recognised" 8 "Eight_Parking_lots_recognised" 9 "Nine_Parking_lots_recognised" 10 "Ten_Parking_lots_recognised" 11 "Eleven_Parking_lots_recognised" 12 "Twelve_Parking_lots_recognised" 13 "Thirteen_Parking_lots_recognised" 14 "Fourteen_Parking_lots_recognised" 15 "Fifteen_Parking_lots_recognised" ;
VAL_ 2463978729 TPA_PaCo_SavingAvailable 0 "Saving_not_available" 1 "Saving_available" ;
VAL_ 2463978788 TPA_Zeitstempel 8191 "Init" ;
VAL_ 2463978788 TPA_Fortschrittsanzeige 125 "ungueltig" 126 "Init" ;
VAL_ 2463978788 TPA_Status 0 "Deaktiv" 1 "Init" 2 "Passiv" 3 "Aktiv_Parkvorganginitiierung_AP" 4 "Aktiv_Aufnahme_Lokalisierung" 5 "Aktiv_Parkvorganginitiierung" 6 "Aktiv_Einparkvorgang" 7 "Aktiv_Ausparkvorgang" 8 "Aktiv_Zielposition_EP_erreicht" 9 "Aktiv_Zielposition_AP_erreicht" 10 "Vorruhe" 15 "Error" ;
VAL_ 2463978788 TPA_FzgPositionY 8190 "Init" ;
VAL_ 2463978788 TPA_Verfuegbarkeit 0 "verfuegbar" 1 "kein_GPS_Lock" 2 "Kamerasicht_eingeschraenkt" 3 "Systemfehler" 4 "temporaerer_Fehler" 5 "sonstiger_Fehler" ;
VAL_ 2463978788 TPA_FzgPositionX 8190 "Init" ;
VAL_ 2463978788 TPA_FzgAusrichtung 510 "Init" ;
VAL_ 2463978788 TPA_Traj_P1_Zugrichtung 0 "Init_Stillstand" 1 "vorwaerts" 2 "rueckwaerts" ;
VAL_ 2463978788 TPA_Traj_P2_Zugrichtung 0 "Init_Stillstand" 1 "vorwaerts" 2 "rueckwaerts" ;
VAL_ 2463978788 TPA_Traj_P3_Zugrichtung 0 "Init_Stillstand" 1 "vorwaerts" 2 "rueckwaerts" ;
VAL_ 2463978788 TPA_Traj_P4_Zugrichtung 0 "Init_Stillstand" 1 "vorwaerts" 2 "rueckwaerts" ;
VAL_ 2463978788 TPA_Traj_P5_Zugrichtung 0 "Init_Stillstand" 1 "vorwaerts" 2 "rueckwaerts" ;
VAL_ 2463978788 TPA_Traj_P6_Zugrichtung 0 "Init_Stillstand" 1 "vorwaerts" 2 "rueckwaerts" ;
VAL_ 2463978788 TPA_Traj_P7_Zugrichtung 0 "Init_Stillstand" 1 "vorwaerts" 2 "rueckwaerts" ;
VAL_ 2463978788 TPA_Traj_P8_Zugrichtung 0 "Init_Stillstand" 1 "vorwaerts" 2 "rueckwaerts" ;
VAL_ 2463978788 TPA_Traj_P9_Zugrichtung 0 "Init_Stillstand" 1 "vorwaerts" 2 "rueckwaerts" ;
VAL_ 2463978788 TPA_Traj_P10_Zugrichtung 0 "Init_Stillstand" 1 "vorwaerts" 2 "rueckwaerts" ;
VAL_ 2463978788 TPA_Traj_P11_Zugrichtung 0 "Init_Stillstand" 1 "vorwaerts" 2 "rueckwaerts" ;
VAL_ 2463978788 TPA_Traj_P12_Zugrichtung 0 "Init_Stillstand" 1 "vorwaerts" 2 "rueckwaerts" ;
VAL_ 2463978788 TPA_Traj_P1_X 8190 "Init" ;
VAL_ 2463978788 TPA_Traj_P1_Y 8190 "Init" ;
VAL_ 2463978788 TPA_Traj_P2_dX 254 "Init" ;
VAL_ 2463978788 TPA_Traj_P2_dY 254 "Init" ;
VAL_ 2463978788 TPA_Traj_P3_dX 254 "Init" ;
VAL_ 2463978788 TPA_Traj_P3_dY 254 "Init" ;
VAL_ 2463978788 TPA_Traj_P4_dX 254 "Init" ;
VAL_ 2463978788 TPA_Traj_P4_dY 254 "Init" ;
VAL_ 2463978788 TPA_Traj_P5_dX 254 "Init" ;
VAL_ 2463978788 TPA_Traj_P5_dY 254 "Init" ;
VAL_ 2463978788 TPA_Traj_P6_dX 254 "Init" ;
VAL_ 2463978788 TPA_Traj_P6_dY 254 "Init" ;
VAL_ 2463978788 TPA_Traj_P7_dX 254 "Init" ;
VAL_ 2463978788 TPA_Traj_P7_dY 254 "Init" ;
VAL_ 2463978788 TPA_Traj_P8_dX 254 "Init" ;
VAL_ 2463978788 TPA_Traj_P8_dY 254 "Init" ;
VAL_ 2463978788 TPA_Traj_P9_dX 254 "Init" ;
VAL_ 2463978788 TPA_Traj_P9_dY 254 "Init" ;
VAL_ 2463978788 TPA_Traj_P10_dX 254 "Init" ;
VAL_ 2463978788 TPA_Traj_P10_dY 254 "Init" ;
VAL_ 2463978788 TPA_Traj_P11_dX 254 "Init" ;
VAL_ 2463978788 TPA_Traj_P11_dY 254 "Init" ;
VAL_ 2463978788 TPA_Traj_P12_dX 254 "Init" ;
VAL_ 2463978788 TPA_Traj_P12_dY 254 "Init" ;
VAL_ 2463978788 TPA_Traj_P1_Tangentenwinkel 126 "Init" ;
VAL_ 2463978788 TPA_Traj_P2_Tangentenwinkel 126 "Init" ;
VAL_ 2463978788 TPA_Traj_P3_Tangentenwinkel 126 "Init" ;
VAL_ 2463978788 TPA_Traj_P4_Tangentenwinkel 126 "Init" ;
VAL_ 2463978788 TPA_Traj_P5_Tangentenwinkel 126 "Init" ;
VAL_ 2463978788 TPA_Traj_P6_Tangentenwinkel 126 "Init" ;
VAL_ 2463978788 TPA_Traj_P7_Tangentenwinkel 126 "Init" ;
VAL_ 2463978788 TPA_Traj_P8_Tangentenwinkel 126 "Init" ;
VAL_ 2463978788 TPA_Traj_P9_Tangentenwinkel 126 "Init" ;
VAL_ 2463978788 TPA_Traj_P10_Tangentenwinkel 126 "Init" ;
VAL_ 2463978788 TPA_Traj_P11_Tangentenwinkel 126 "Init" ;
VAL_ 2463978788 TPA_Traj_P12_Tangentenwinkel 126 "Init" ;
VAL_ 2463978788 TPA_Abbruch 0 "kein_Abbruch" 1 "Abweichung_von_Trajektorie" 2 "Kamerasicht_eingeschraenkt" 3 "Lokalisierungsfehler" 4 "Systemfehler" 5 "AP_Training_Abbruch" 6 "sonstiger_Grund" ;
VAL_ 2463978788 TPA_Remote_aktivierbar 0 "Remote_nicht_aktivierbar" 1 "Remote_aktivierbar" ;
VAL_ 2463978788 TPA_Remote_verfuegbar 0 "Remote_nicht_verfuegbar" 1 "Remote_verfuegbar" ;
VAL_ 2463978788 TPA_Traj_P1_Kruemmung_VZ 0 "positiv" 1 "negativ" ;
VAL_ 2463978788 TPA_Traj_P2_Kruemmung_VZ 0 "positiv" 1 "negativ" ;
VAL_ 2463978788 TPA_Traj_P3_Kruemmung_VZ 0 "positiv" 1 "negativ" ;
VAL_ 2463978788 TPA_Traj_P4_Kruemmung_VZ 0 "positiv" 1 "negativ" ;
VAL_ 2463978788 TPA_Traj_P5_Kruemmung_VZ 0 "positiv" 1 "negativ" ;
VAL_ 2589283583 TPA_Traj_P6_Kruemmung_VZ 0 "positiv" 1 "negativ" ;
VAL_ 2589283583 TPA_Traj_P7_Kruemmung_VZ 0 "positiv" 1 "negativ" ;
VAL_ 2589283583 TPA_Traj_P8_Kruemmung_VZ 0 "positiv" 1 "negativ" ;
VAL_ 2589283583 TPA_Traj_P9_Kruemmung_VZ 0 "positiv" 1 "negativ" ;
VAL_ 2589283583 TPA_Traj_P10_Kruemmung_VZ 0 "positiv" 1 "negativ" ;
VAL_ 2589283583 TPA_Traj_P11_Kruemmung_VZ 0 "positiv" 1 "negativ" ;
VAL_ 2589283583 TPA_Traj_P12_Kruemmung_VZ 0 "positiv" 1 "negativ" ;
VAL_ 2589283583 TPA_Traj_P13_Kruemmung_VZ 0 "positiv" 1 "negativ" ;
VAL_ 2589283583 TPA_Traj_P14_Kruemmung_VZ 0 "positiv" 1 "negativ" ;
VAL_ 2589283583 TPA_Traj_P15_Kruemmung_VZ 0 "positiv" 1 "negativ" ;
